VERSION ""

NS_ :

BS_:

BU_: BCM NAB NVO SGW

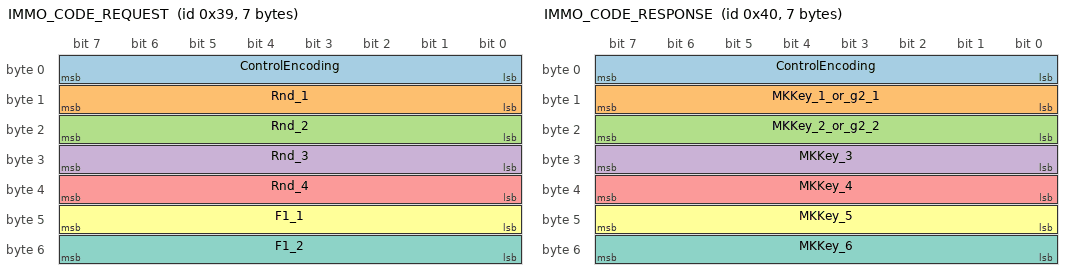
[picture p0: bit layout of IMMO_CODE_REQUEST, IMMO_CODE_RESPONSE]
BO_ 57 IMMO_CODE_REQUEST: 7 SGW
  SG_ ControlEncoding : 7|8@0+ (1,0) [0|255] "" BCM
  SG_ Rnd_1 : 15|8@0+ (1,0) [0|255] "" BCM
  SG_ Rnd_2 : 23|8@0+ (1,0) [0|255] "" BCM
  SG_ Rnd_3 : 31|8@0+ (1,0) [0|255] "" BCM
  SG_ Rnd_4 : 39|8@0+ (1,0) [0|255] "" BCM
  SG_ F1_1 : 47|8@0+ (1,0) [0|255] "" BCM
  SG_ F1_2 : 55|8@0+ (1,0) [0|255] "" BCM

BO_ 64 IMMO_CODE_RESPONSE: 7 BCM
  SG_ ControlEncoding : 7|8@0+ (1,0) [0|255] "" SGW
  SG_ MKKey_1_or_g2_1 : 15|8@0+ (1,0) [0|255] "" SGW
  SG_ MKKey_2_or_g2_2 : 23|8@0+ (1,0) [0|255] "" SGW
  SG_ MKKey_3 : 31|8@0+ (1,0) [0|255] "" SGW
  SG_ MKKey_4 : 39|8@0+ (1,0) [0|255] "" SGW
  SG_ MKKey_5 : 47|8@0+ (1,0) [0|255] "" SGW
  SG_ MKKey_6 : 55|8@0+ (1,0) [0|255] "" SGW

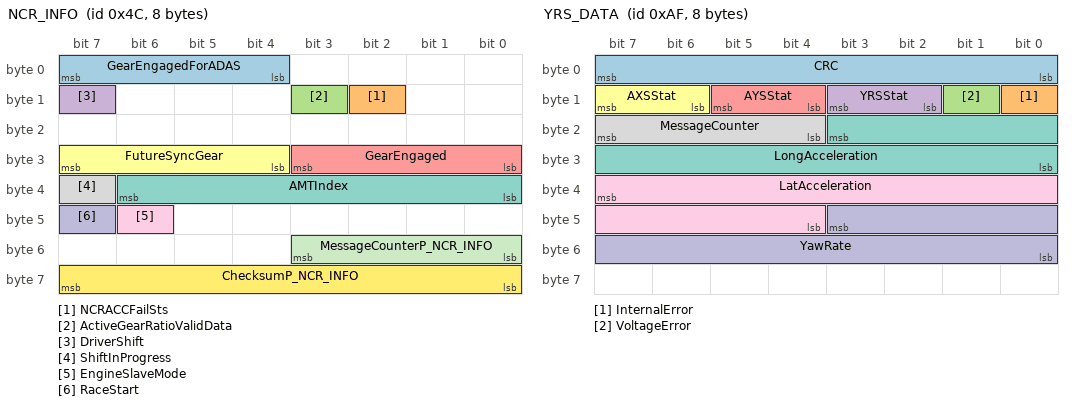
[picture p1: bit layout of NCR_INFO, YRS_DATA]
BO_ 76 NCR_INFO: 8 SGW
  SG_ GearEngagedForADAS : 7|4@0+ (1,0) [0|15] "" Vector__XXX
  SG_ NCRACCFailSts : 10|1@0+ (1,0) [0|1] "" Vector__XXX
  SG_ ActiveGearRatioValidData : 11|1@0+ (1,0) [0|1] "" Vector__XXX
  SG_ DriverShift : 15|1@0+ (1,0) [0|1] "" Vector__XXX
  SG_ GearEngaged : 27|4@0+ (1,0) [0|15] "" BCM
  SG_ FutureSyncGear : 31|4@0+ (1,0) [0|15] "" Vector__XXX
  SG_ AMTIndex : 38|7@0+ (1,0) [0|100] "" Vector__XXX
  SG_ ShiftInProgress : 39|1@0+ (1,0) [0|1] "" Vector__XXX
  SG_ EngineSlaveMode : 46|1@0+ (1,0) [0|1] "" Vector__XXX
  SG_ RaceStart : 47|1@0+ (1,0) [0|1] "" Vector__XXX
  SG_ MessageCounterP_NCR_INFO : 51|4@0+ (1,0) [0|15] "" Vector__XXX
  SG_ ChecksumP_NCR_INFO : 63|8@0+ (1,0) [0|255] "" Vector__XXX

BO_ 175 YRS_DATA: 8 SGW
  SG_ CRC : 7|8@0+ (1,0) [0|255] "" BCM,NAB
  SG_ InternalError : 8|1@0+ (1,0) [0|1] "" Vector__XXX
  SG_ VoltageError : 9|1@0+ (1,0) [0|1] "" Vector__XXX
  SG_ YRSStat : 11|2@0+ (1,0) [0|3] "" BCM
  SG_ AYSStat : 13|2@0+ (1,0) [0|3] "" BCM
  SG_ AXSStat : 15|2@0+ (1,0) [0|3] "" BCM
  SG_ LongAcceleration : 19|12@0+ (0.02,-40.96) [-40.96|40.92] "m/s²" BCM
  SG_ MessageCounter : 23|4@0+ (1,0) [0|15] "" BCM,NAB
  SG_ LatAcceleration : 39|12@0+ (0.02,-40.96) [-40.96|40.92] "m/s²" BCM
  SG_ YawRate : 43|12@0+ (0.08,-163.84) [-163.84|163.68] "°/s" BCM,NAB

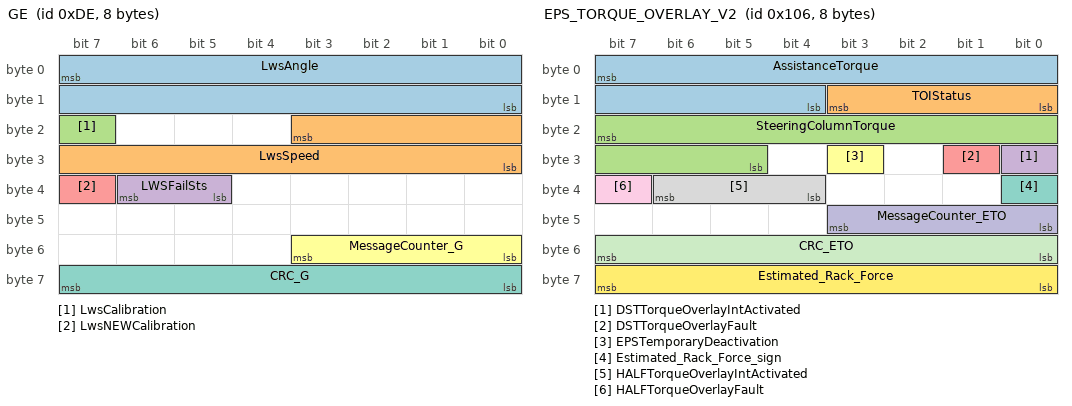
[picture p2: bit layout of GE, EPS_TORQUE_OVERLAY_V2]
BO_ 222 GE: 8 SGW
  SG_ LwsAngle : 7|16@0+ (0.1,-720) [-720|720] "°" BCM,NAB
  SG_ LwsSpeed : 19|12@0+ (1,-2000) [-2000|2094] "°/S" Vector__XXX
  SG_ LwsCalibration : 23|1@0+ (1,0) [0|1] "" Vector__XXX
  SG_ LWSFailSts : 38|2@0+ (1,0) [0|3] "" BCM,NAB
  SG_ LwsNEWCalibration : 39|1@0+ (1,0) [0|1] "" Vector__XXX
  SG_ MessageCounter_G : 51|4@0+ (1,0) [0|15] "" Vector__XXX
  SG_ CRC_G : 63|8@0+ (1,0) [0|255] "" Vector__XXX

BO_ 262 EPS_TORQUE_OVERLAY_V2: 8 SGW
  SG_ AssistanceTorque : 7|12@0+ (0.05,-100) [-100|104.75] "Nm" Vector__XXX
  SG_ TOIStatus : 11|4@0+ (1,0) [0|15] "" Vector__XXX
  SG_ SteeringColumnTorque : 23|11@0+ (0.0078125,-8) [-8|7.984375] "Nm" Vector__XXX
  SG_ DSTTorqueOverlayIntActivated : 24|1@0+ (1,0) [0|1] "" Vector__XXX
  SG_ DSTTorqueOverlayFault : 25|1@0+ (1,0) [0|1] "" Vector__XXX
  SG_ EPSTemporaryDeactivation : 27|1@0+ (1,0) [0|1] "" Vector__XXX
  SG_ Estimated_Rack_Force_sign : 32|1@0+ (1,0) [0|1] "" Vector__XXX
  SG_ HALFTorqueOverlayIntActivated : 38|3@0+ (1,0) [0|7] "" NAB
  SG_ HALFTorqueOverlayFault : 39|1@0+ (1,0) [0|1] "" NAB
  SG_ MessageCounter_ETO : 43|4@0+ (1,0) [0|15] "" Vector__XXX
  SG_ CRC_ETO : 55|8@0+ (1,0) [0|255] "" Vector__XXX
  SG_ Estimated_Rack_Force : 63|8@0+ (80,0) [0|20400] "N" Vector__XXX

BO_ 359 RFHUB1: 8 BCM
  SG_ ExteriorRearSwitch : 0|1@0+ (1,0) [0|1] "" SGW
  SG_ IgnPosSts : 3|3@0+ (1,0) [0|7] "" SGW
  SG_ ValidKeySts : 5|2@0+ (1,0) [0|3] "" SGW
  SG_ CustKeyInIgnSts : 7|2@0+ (1,0) [0|3] "" SGW
  SG_ RFFuncReq : 8|5@0+ (1,0) [0|31] "" SGW
  SG_ RFFobNum : 12|4@0+ (1,0) [0|15] "" SGW
  SG_ RFRearFuncReq : 15|3@0+ (1,0) [0|7] "" SGW
  SG_ FobSearchResult : 16|8@0+ (1,0) [0|255] "" SGW
  SG_ RFReq : 19|3@0+ (1,0) [0|7] "" SGW
  SG_ EmergencyShutdown : 24|1@0+ (1,0) [0|1] "" SGW
  SG_ FobSearchFault : 32|1@0+ (1,0) [0|1] "" SGW
  SG_ HMIPowerOnReq : 33|1@0+ (1,0) [0|1] "" NVO,SGW
  SG_ FOBInterferenceAvoid : 34|1@0+ (1,0) [0|1] "raw" SGW
  SG_ DriverEnginOffRequest : 35|1@0+ (1,0) [0|1] "" SGW
  SG_ FobSearchResult_LongPressure : 39|3@0+ (1,0) [0|7] "" SGW
  SG_ FobSearchExteriorRear : 41|1@0+ (1,0) [0|1] "" SGW
  SG_ FobSearchExteriorLeft : 42|1@0+ (1,0) [0|1] "" SGW
  SG_ FobSearchExteriorRight : 43|1@0+ (1,0) [0|1] "" SGW
  SG_ FobSearchInterior : 44|1@0+ (1,0) [0|1] "" SGW
  SG_ FobSearchTrunk : 45|1@0+ (1,0) [0|1] "" SGW
  SG_ FobSearchStatus : 47|2@0+ (1,0) [0|3] "" SGW
  SG_ MessageCounter_HUB1 : 51|4@0+ (1,0) [0|15] "" SGW
  SG_ KeyCommandReq : 52|1@0+ (1,0) [0|1] "" SGW
  SG_ NPE_ActuationReq : 55|2@0+ (1,0) [0|3] "" SGW
  SG_ Checksum_HUB1 : 63|8@0+ (1,0) [0|255] "" SGW

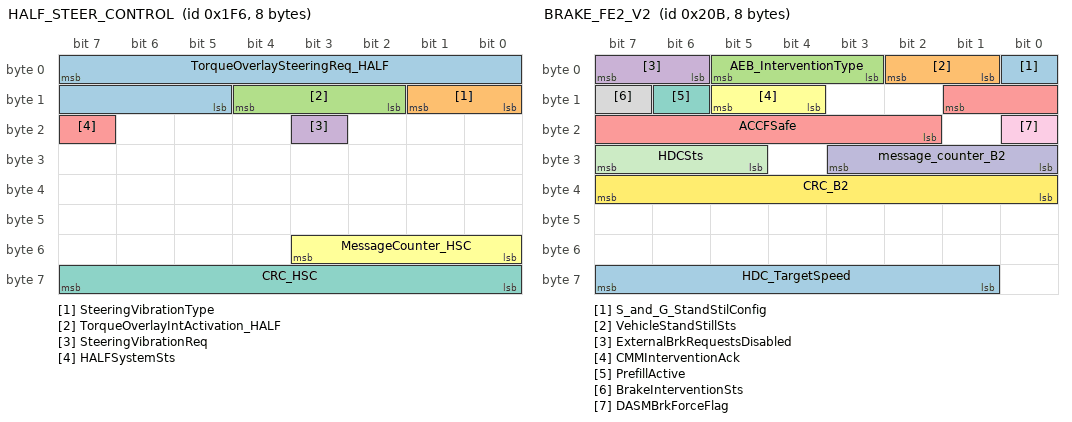
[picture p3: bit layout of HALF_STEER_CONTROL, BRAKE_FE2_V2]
BO_ 502 HALF_STEER_CONTROL: 8 SGW
  SG_ TorqueOverlaySteeringReq_HALF : 7|11@0+ (0.00195312,-2) [-2|1.99803664] "Nm" Vector__XXX
  SG_ SteeringVibrationType : 9|2@0+ (1,0) [0|3] "" Vector__XXX
  SG_ TorqueOverlayIntActivation_HALF : 12|3@0+ (1,0) [0|7] "" Vector__XXX
  SG_ SteeringVibrationReq : 19|1@0+ (1,0) [0|1] "" Vector__XXX
  SG_ HALFSystemSts : 23|1@0+ (1,0) [0|1] "" NAB
  SG_ MessageCounter_HSC : 51|4@0+ (1,0) [0|15] "" Vector__XXX
  SG_ CRC_HSC : 63|8@0+ (1,0) [0|255] "" Vector__XXX

BO_ 523 BRAKE_FE2_V2: 8 SGW
  SG_ S_and_G_StandStilConfig : 0|1@0+ (1,0) [0|1] "" Vector__XXX
  SG_ VehicleStandStillSts : 2|2@0+ (1,0) [0|3] "" Vector__XXX
  SG_ AEB_InterventionType : 5|3@0+ (1,0) [0|7] "" NAB
  SG_ ExternalBrkRequestsDisabled : 7|2@0+ (1,0) [0|3] "" Vector__XXX
  SG_ ACCFSafe : 9|8@0+ (1,0) [0|255] "" Vector__XXX
  SG_ CMMInterventionAck : 13|2@0+ (1,0) [0|3] "" Vector__XXX
  SG_ PrefillActive : 14|1@0+ (1,0) [0|1] "" Vector__XXX
  SG_ BrakeInterventionSts : 15|1@0+ (1,0) [0|1] "" Vector__XXX
  SG_ DASMBrkForceFlag : 16|1@0+ (1,0) [0|1] "" Vector__XXX
  SG_ message_counter_B2 : 27|4@0+ (1,0) [0|15] "" NVO
  SG_ HDCSts : 31|3@0+ (1,0) [0|7] "" NVO
  SG_ CRC_B2 : 39|8@0+ (1,0) [0|255] "" NVO
  SG_ HDC_TargetSpeed : 63|7@0+ (1,0) [0|120] "" Vector__XXX

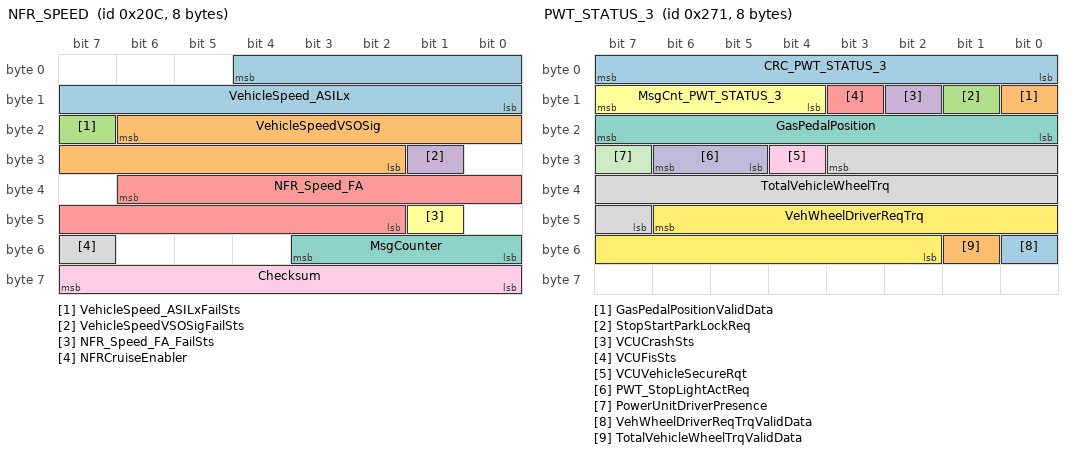
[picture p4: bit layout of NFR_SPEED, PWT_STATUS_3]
BO_ 524 NFR_SPEED: 8 SGW
  SG_ VehicleSpeed_ASILx : 4|13@0+ (0.0625,0) [0|511.9375] "km/h" BCM
  SG_ VehicleSpeedVSOSig : 22|13@0+ (0.0625,0) [0|511.9375] "km/h" BCM,NAB,NVO
  SG_ VehicleSpeed_ASILxFailSts : 23|1@0+ (1,0) [0|1] "" BCM
  SG_ VehicleSpeedVSOSigFailSts : 25|1@0+ (1,0) [0|1] "" BCM,NAB,NVO
  SG_ NFR_Speed_FA : 38|13@0+ (0.0625,0) [0|511.9375] "km/h" BCM,NAB
  SG_ NFR_Speed_FA_FailSts : 41|1@0+ (1,0) [0|1] "" BCM,NAB
  SG_ MsgCounter : 51|4@0+ (1,0) [0|15] "" BCM
  SG_ NFRCruiseEnabler : 55|1@0+ (1,0) [0|1] "" BCM
  SG_ Checksum : 63|8@0+ (1,0) [0|255] "" BCM

BO_ 599 AIRBAG1: 8 NAB
  SG_ SBR2RowCentralSeatBuckleFailSts : 0|2@0+ (1,0) [0|3] "" BCM,SGW
  SG_ SBR2RowCentralSeatConfigSts : 1|1@0+ (1,0) [0|1] "" BCM,SGW
  SG_ AirBagFailSts : 7|2@0+ (1,0) [0|3] "" BCM,SGW
  SG_ SBR1RowDriverSeatFailSts : 8|2@0+ (1,0) [0|3] "" BCM,SGW
  SG_ SBR1RowDriverSeatConfigSts : 9|1@0+ (1,0) [0|1] "" BCM,SGW
  SG_ SBR2RowCentralSeatSts : 12|3@0+ (1,0) [0|7] "" BCM,SGW
  SG_ SBR1RowCentralSeatPPDFailSts : 14|2@0+ (1,0) [0|3] "" BCM,SGW
  SG_ SBR1RowPsngrSeatPPDFailSts : 17|2@0+ (1,0) [0|3] "" BCM,SGW
  SG_ SBR1RowPsngrSeatBuckleFailSts : 19|2@0+ (1,0) [0|3] "" BCM,SGW
  SG_ SBR1RowPsngrSeatConfigSts : 20|1@0+ (1,0) [0|1] "" BCM,SGW
  SG_ SBR1RowDriverSeatSts : 22|2@0+ (1,0) [0|3] "" BCM,SGW
  SG_ SBR2RowLeftSeatSts : 24|2@0+ (1,0) [0|3] "" BCM,SGW
  SG_ SBR2RowRightSeatFailSts : 26|2@0+ (1,0) [0|3] "" BCM,SGW
  SG_ SBR2RowLeftSeatFailSts : 28|2@0+ (1,0) [0|3] "" BCM,SGW
  SG_ SBR1RowPsngrSeatSts : 31|3@0+ (1,0) [0|7] "" BCM,SGW
  SG_ CrashOutputSts : 36|8@0+ (1,0) [0|255] "" BCM,SGW
  SG_ SBR2RowRightSeatSts : 38|2@0+ (1,0) [0|3] "" BCM,SGW
  SG_ MessageCounterNAB1 : 43|4@0+ (1,0) [0|15] "" BCM,SGW
  SG_ CrashOutputValidData : 44|1@0+ (1,0) [0|1] "" BCM,SGW
  SG_ ChecksumNAB1 : 55|8@0+ (1,0) [0|255] "" BCM,SGW
  SG_ AirBagWarningPADLampOnSts : 56|1@0+ (1,0) [0|1] "" BCM,SGW
  SG_ AirBagWarningPADLampOffSts : 57|1@0+ (1,0) [0|1] "" BCM,SGW
  SG_ SBR2RowRightSeatConfigSts : 58|1@0+ (1,0) [0|1] "" BCM,SGW
  SG_ SBR2RowLeftSeatConfigSts : 59|1@0+ (1,0) [0|1] "" BCM,SGW
  SG_ Ppd_psngr_info : 61|2@0+ (1,0) [0|3] "" BCM,SGW
  SG_ AirBagWarningLampSts : 62|1@0+ (1,0) [0|1] "" BCM,SGW
  SG_ AirBagWarningPADPassengerAirbagSts : 63|1@0+ (1,0) [0|1] "" BCM,SGW

BO_ 625 PWT_STATUS_3: 8 SGW
  SG_ CRC_PWT_STATUS_3 : 7|8@0+ (1,0) [0|255] "" BCM
  SG_ GasPedalPositionValidData : 8|1@0+ (1,0) [0|1] "" Vector__XXX
  SG_ StopStartParkLockReq : 9|1@0+ (1,0) [0|1] "" Vector__XXX
  SG_ VCUCrashSts : 10|1@0+ (1,0) [0|1] "" Vector__XXX
  SG_ VCUFisSts : 11|1@0+ (1,0) [0|1] "" BCM
  SG_ MsgCnt_PWT_STATUS_3 : 15|4@0+ (1,0) [0|14] "" BCM
  SG_ GasPedalPosition : 23|8@0+ (0.392,0) [0|99.96] "%" Vector__XXX
  SG_ TotalVehicleWheelTrq : 27|13@0+ (10,-25000) [-25000|25000] "Nm" Vector__XXX
  SG_ VCUVehicleSecureRqt : 28|1@0+ (1,0) [0|1] "" Vector__XXX
  SG_ PWT_StopLightActReq : 30|2@0+ (1,0) [0|3] "" Vector__XXX
  SG_ PowerUnitDriverPresence : 31|1@0+ (1,0) [0|1] "" Vector__XXX
  SG_ VehWheelDriverReqTrq : 46|13@0+ (10,-25000) [-25000|25000] "Nm" Vector__XXX
  SG_ VehWheelDriverReqTrqValidData : 48|1@0+ (1,0) [0|1] "" Vector__XXX
  SG_ TotalVehicleWheelTrqValidData : 49|1@0+ (1,0) [0|1] "" Vector__XXX

BO_ 630 NFR_INFO: 8 SGW
  SG_ CRC_NFR_INFO : 7|8@0+ (1,0) [0|255] "" BCM
  SG_ EPBMalfunction : 8|1@0+ (1,0) [0|1] "" BCM,NAB
  SG_ EPBSts : 11|3@0+ (1,0) [0|7] "" BCM,NAB
  SG_ MessageCounter_NFR_INFO : 15|4@0+ (1,0) [0|14] "" BCM
  SG_ CRBSts : 17|3@0+ (1,0) [0|7] "" BCM
  SG_ AVHSts : 20|3@0+ (1,0) [0|7] "" BCM
  SG_ CDPSts : 23|3@0+ (1,0) [0|7] "" BCM
  SG_ HHCSts : 24|3@0+ (1,0) [0|7] "" BCM
  SG_ ABSSts : 27|3@0+ (1,0) [0|7] "" BCM,NAB
  SG_ EBDSts : 30|3@0+ (1,0) [0|7] "" BCM
  SG_ ESCOFF_Mode : 32|1@0+ (1,0) [0|1] "" BCM,NAB
  SG_ MSRSts : 35|3@0+ (1,0) [0|7] "" BCM
  SG_ EPB_ButtonSts : 37|2@0+ (1,0) [0|3] "" BCM
  SG_ AutoEPBEnable : 41|2@0+ (1,0) [0|3] "" BCM
  SG_ VDCSts : 44|3@0+ (1,0) [0|7] "" BCM,NAB
  SG_ LDISts : 47|3@0+ (1,0) [0|7] "" BCM
  SG_ Slope : 53|7@0+ (1,-61) [-61|61] "%" BCM
  SG_ TireToleranceCompensation : 54|1@0+ (1,0) [0|1] "" BCM
  SG_ MiniSpareDetection : 55|1@0+ (1,0) [0|1] "" BCM
  SG_ SlopeValidData : 62|1@0+ (1,0) [0|1] "" BCM

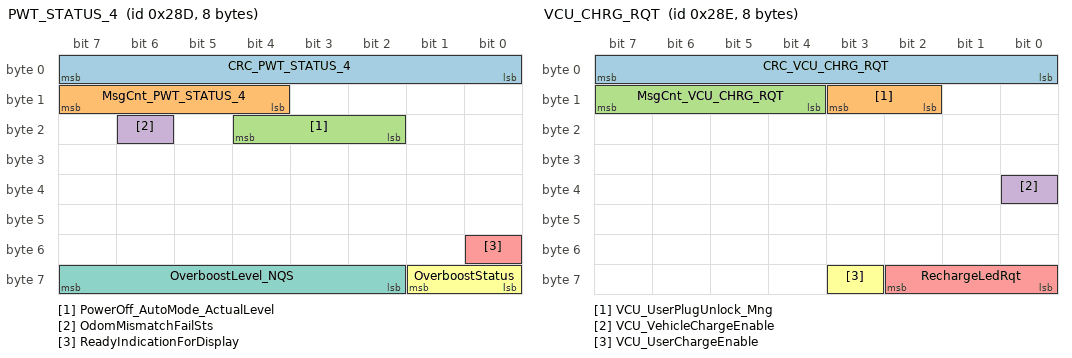
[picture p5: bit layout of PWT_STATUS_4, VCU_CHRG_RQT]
BO_ 653 PWT_STATUS_4: 8 SGW
  SG_ CRC_PWT_STATUS_4 : 7|8@0+ (1,0) [0|255] "" Vector__XXX
  SG_ MsgCnt_PWT_STATUS_4 : 15|4@0+ (1,0) [0|14] "" Vector__XXX
  SG_ PowerOff_AutoMode_ActualLevel : 20|3@0+ (1,0) [0|7] "" Vector__XXX
  SG_ OdomMismatchFailSts : 22|1@0+ (1,0) [0|1] "" Vector__XXX
  SG_ ReadyIndicationForDisplay : 48|1@0+ (1,0) [0|1] "" Vector__XXX
  SG_ OverboostStatus : 57|2@0+ (1,0) [0|3] "" Vector__XXX
  SG_ OverboostLevel_NQS : 63|6@0+ (1,0) [0|60] "" Vector__XXX

BO_ 654 VCU_CHRG_RQT: 8 SGW
  SG_ CRC_VCU_CHRG_RQT : 7|8@0+ (1,0) [0|255] "" BCM
  SG_ VCU_UserPlugUnlock_Mng : 11|2@0+ (1,0) [0|3] "" BCM
  SG_ MsgCnt_VCU_CHRG_RQT : 15|4@0+ (1,0) [0|14] "" BCM
  SG_ VCU_VehicleChargeEnable : 32|1@0+ (1,0) [0|1] "" BCM
  SG_ RechargeLedRqt : 58|3@0+ (1,0) [0|7] "" BCM
  SG_ VCU_UserChargeEnable : 59|1@0+ (1,0) [0|1] "" BCM

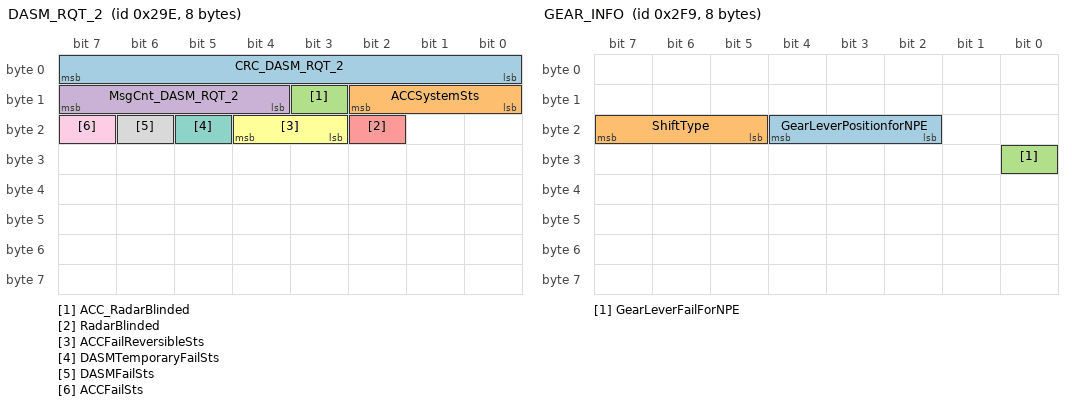
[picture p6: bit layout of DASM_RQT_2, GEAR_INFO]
BO_ 670 DASM_RQT_2: 8 SGW
  SG_ CRC_DASM_RQT_2 : 7|8@0+ (1,0) [0|255] "" NVO
  SG_ ACCSystemSts : 10|3@0+ (1,0) [0|7] "" NAB,NVO
  SG_ ACC_RadarBlinded : 11|1@0+ (1,0) [0|1] "" Vector__XXX
  SG_ MsgCnt_DASM_RQT_2 : 15|4@0+ (1,0) [0|14] "" NVO
  SG_ RadarBlinded : 18|1@0+ (1,0) [0|1] "" Vector__XXX
  SG_ ACCFailReversibleSts : 20|2@0+ (1,0) [0|3] "" Vector__XXX
  SG_ DASMTemporaryFailSts : 21|1@0+ (1,0) [0|1] "" NAB
  SG_ DASMFailSts : 22|1@0+ (1,0) [0|1] "" NAB
  SG_ ACCFailSts : 23|1@0+ (1,0) [0|1] "" NAB

BO_ 761 GEAR_INFO: 8 SGW
  SG_ GearLeverPositionforNPE : 20|3@0+ (1,0) [0|7] "" BCM
  SG_ ShiftType : 23|3@0+ (1,0) [0|7] "" Vector__XXX
  SG_ GearLeverFailForNPE : 24|1@0+ (1,0) [0|1] "" BCM

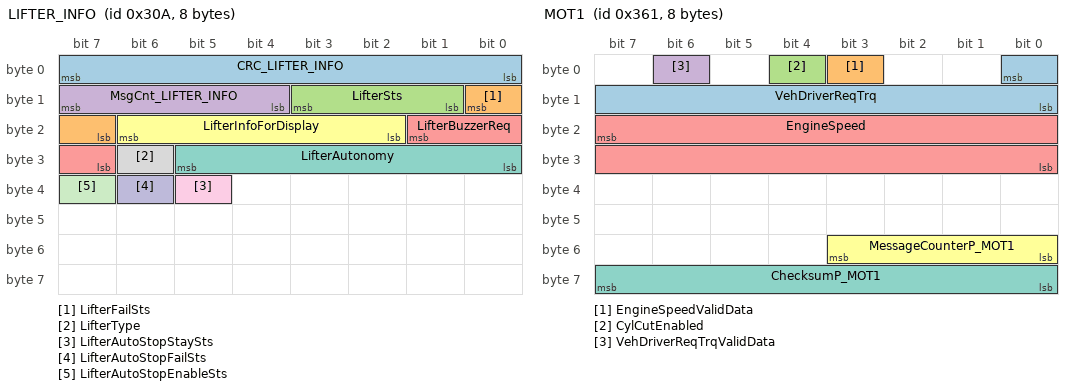
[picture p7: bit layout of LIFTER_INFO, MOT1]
BO_ 778 LIFTER_INFO: 8 SGW
  SG_ CRC_LIFTER_INFO : 7|8@0+ (1,0) [0|255] "" BCM
  SG_ LifterFailSts : 8|2@0+ (1,0) [0|3] "" BCM
  SG_ LifterSts : 11|3@0+ (1,0) [0|7] "" BCM
  SG_ MsgCnt_LIFTER_INFO : 15|4@0+ (1,0) [0|14] "" BCM
  SG_ LifterBuzzerReq : 17|3@0+ (1,0) [0|7] "" Vector__XXX
  SG_ LifterInfoForDisplay : 22|5@0+ (1,0) [0|31] "" Vector__XXX
  SG_ LifterAutonomy : 29|6@0+ (5,0) [0|300] "" Vector__XXX
  SG_ LifterType : 30|1@0+ (1,0) [0|1] "" Vector__XXX
  SG_ LifterAutoStopStaySts : 37|1@0+ (1,0) [0|1] "" Vector__XXX
  SG_ LifterAutoStopFailSts : 38|1@0+ (1,0) [0|1] "" Vector__XXX
  SG_ LifterAutoStopEnableSts : 39|1@0+ (1,0) [0|1] "" Vector__XXX

BO_ 865 MOT1: 8 SGW
  SG_ VehDriverReqTrq : 0|9@0+ (4,-508) [-508|1536] "Nm" Vector__XXX
  SG_ EngineSpeedValidData : 3|1@0+ (1,0) [0|1] "" NAB
  SG_ CylCutEnabled : 4|1@0+ (1,0) [0|1] "" Vector__XXX
  SG_ VehDriverReqTrqValidData : 6|1@0+ (1,0) [0|1] "" Vector__XXX
  SG_ EngineSpeed : 23|16@0+ (1,0) [0|10240] "1/min" NAB
  SG_ MessageCounterP_MOT1 : 51|4@0+ (1,0) [0|15] "" BCM
  SG_ ChecksumP_MOT1 : 63|8@0+ (1,0) [0|255] "" BCM

BO_ 980 NVO_INFO_V2: 8 NVO
  SG_ CruiseControlCmdResumeSts : 0|1@0+ (1,0) [0|1] "" BCM,SGW
  SG_ CruiseControlCmdChangeSts : 1|1@0+ (1,0) [0|1] "" BCM,SGW
  SG_ CruiseControlCmdDecelerationSts : 2|1@0+ (1,0) [0|1] "" BCM,SGW
  SG_ CruiseControlCmdAccelerationSts : 3|1@0+ (1,0) [0|1] "" BCM,SGW
  SG_ EManettinoDriverWish : 7|4@0+ (1,0) [0|15] "" BCM,SGW
  SG_ CruiseControlFailSts : 9|1@0+ (1,0) [0|1] "" SGW
  SG_ ACC_OnOffSts : 10|1@0+ (1,0) [0|1] "" BCM,SGW
  SG_ SpeedRockerSts : 13|3@0+ (1,0) [0|7] "" BCM,SGW
  SG_ ACC_DistSts : 14|1@0+ (1,0) [0|1] "" SGW
  SG_ ResumeSwitch : 15|1@0+ (1,0) [0|1] "" BCM,SGW
  SG_ ManettinoSuspensionSts : 18|3@0+ (1,0) [0|7] "" SGW
  SG_ ESPChangeModeReqSts : 19|1@0+ (1,0) [0|1] "" SGW
  SG_ ManettinoFailSts : 20|1@0+ (1,0) [0|1] "" SGW
  SG_ ManettinoSts : 23|3@0+ (1,0) [0|7] "" BCM,SGW
  SG_ FrontWindshieldWiperSwitchSts : 26|3@0+ (1,0) [0|7] "" BCM,SGW
  SG_ SuspensionButtonSts : 27|1@0+ (1,0) [0|1] "" BCM,SGW
  SG_ LdirectionSwitchSts : 28|1@0+ (1,0) [0|1] "" BCM,SGW
  SG_ RdirectionSwitchSts : 29|1@0+ (1,0) [0|1] "" BCM,SGW
  SG_ LTICmdFailSts : 32|1@0+ (1,0) [0|1] "" BCM,SGW
  SG_ SuspensionButtonValidData : 33|1@0+ (1,0) [0|1] "" SGW
  SG_ EManettinoDriverWishDirection : 35|2@0+ (1,0) [0|3] "" SGW
  SG_ HDCButtonSts : 37|1@0+ (1,0) [0|1] "" SGW
  SG_ WiperCmdFailSts : 38|1@0+ (1,0) [0|1] "" BCM,SGW
  SG_ FrontWindshieldWasherSwitchSts : 39|1@0+ (1,0) [0|1] "" BCM,SGW
  SG_ ConfirmationCommand : 42|2@0+ (1,0) [0|3] "" BCM,SGW
  SG_ ContentsCommand : 44|2@0+ (1,0) [0|3] "" BCM,SGW
  SG_ RChangeLaneSts : 45|1@0+ (1,0) [0|1] "" BCM,SGW
  SG_ LChangeLaneSts : 46|1@0+ (1,0) [0|1] "" BCM,SGW
  SG_ RTICmdFailSts : 47|1@0+ (1,0) [0|1] "" BCM,SGW
  SG_ MessageCounterP_NVO_INFO : 51|4@0+ (1,0) [0|15] "" BCM,SGW
  SG_ ChecksumP_NVO_INFO : 63|8@0+ (1,0) [0|255] "" BCM,SGW

BO_ 988 STATUS_NTP: 8 SGW
  SG_ TyrePressureSystemSts : 0|1@0+ (1,0) [0|1] "" NAB
  SG_ TyrePressureSystemFailSts : 1|1@0+ (1,0) [0|1] "" NAB
  SG_ TyrePressureSysCalibrationSts : 2|1@0+ (1,0) [0|1] "" Vector__XXX
  SG_ NTPTempNotActiveSts : 3|1@0+ (1,0) [0|1] "" Vector__XXX
  SG_ NTPCalibrationReqACK : 4|1@0+ (1,0) [0|1] "" Vector__XXX
  SG_ IDtyre_temperature : 7|2@0+ (1,0) [0|3] "" Vector__XXX
  SG_ TemperatureSts_xx : 15|8@0+ (1,-40) [-40|125] "°C" Vector__XXX
  SG_ UnknownTyrePressureSts : 17|2@0+ (1,0) [0|3] "" Vector__XXX
  SG_ TPMSTelltaleSts : 23|2@0+ (1,0) [0|3] "" Vector__XXX
  SG_ RHRTyrePressureSts : 25|2@0+ (1,0) [0|3] "" Vector__XXX
  SG_ LHRTyrePressureSts : 27|2@0+ (1,0) [0|3] "" Vector__XXX
  SG_ RHFTyrePressureSts : 29|2@0+ (1,0) [0|3] "" Vector__XXX
  SG_ LHFTyrePressureSts : 31|2@0+ (1,0) [0|3] "" Vector__XXX
  SG_ LHFPressureSts : 39|8@0+ (0.025,0) [0|5.375] "bar" Vector__XXX
  SG_ RHFPressureSts : 47|8@0+ (0.025,0) [0|5.375] "bar" Vector__XXX
  SG_ LHRPressureSts : 55|8@0+ (0.025,0) [0|5.375] "bar" Vector__XXX
  SG_ RHRPressureSts : 63|8@0+ (0.025,0) [0|5.375] "bar" Vector__XXX

BO_ 1023 LCU_COMMAND: 8 BCM
  SG_ HBActivation : 1|2@0+ (1,0) [0|3] "" SGW
  SG_ LBActivation : 2|1@0+ (1,0) [0|1] "" SGW
  SG_ ParkingLightCmd : 3|1@0+ (1,0) [0|1] "" SGW
  SG_ LeftPL : 4|1@0+ (1,0) [0|1] "" SGW
  SG_ RightPL : 5|1@0+ (1,0) [0|1] "" SGW
  SG_ LeftDRL : 6|1@0+ (1,0) [0|1] "" SGW
  SG_ RightDRL : 7|1@0+ (1,0) [0|1] "" SGW
  SG_ AHB_Memory : 12|1@0+ (1,0) [0|1] "" SGW
  SG_ FBL_Activation : 13|1@0+ (1,0) [0|1] "" SGW
  SG_ TrafficChangeEnable : 15|2@0+ (1,0) [0|3] "" SGW
  SG_ AFSReq : 40|1@0+ (1,0) [0|1] "" SGW
  SG_ MsgCounter_LCUCmd : 51|4@0+ (1,0) [0|15] "" SGW
  SG_ FrontWindshieldWiperSts : 52|1@0+ (1,0) [0|1] "" SGW
  SG_ FrontWindshieldWasherSts : 53|1@0+ (1,0) [0|1] "" SGW
  SG_ AHBFeature : 54|1@0+ (1,0) [0|1] "" SGW
  SG_ AHB_ON : 55|1@0+ (1,0) [0|1] "" SGW
  SG_ Checksum_LCUCmd : 63|8@0+ (1,0) [0|255] "" SGW

BO_ 1024 Gyro_Data: 6 BCM
  SG_ YawRate : 39|12@0+ (0.08,-163.84) [-163.84|163.68] "°/s" SGW
  SG_ YRSStat : 43|2@0+ (1,0) [0|3] "" SGW

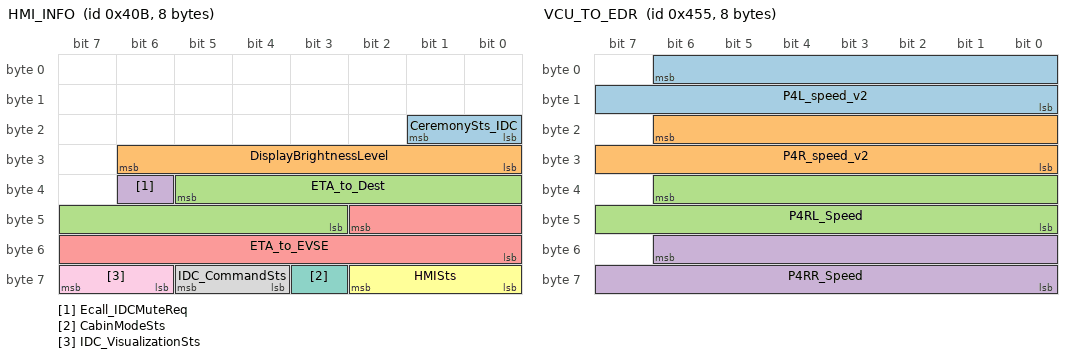
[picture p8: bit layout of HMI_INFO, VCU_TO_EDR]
BO_ 1035 HMI_INFO: 8 SGW
  SG_ CeremonySts_IDC : 17|2@0+ (1,0) [0|3] "" BCM
  SG_ DisplayBrightnessLevel : 30|7@0+ (1,0) [0|127] "" BCM
  SG_ ETA_to_Dest : 37|11@0+ (1,0) [0|2047] "min" BCM
  SG_ Ecall_IDCMuteReq : 38|1@0+ (1,0) [0|1] "" BCM
  SG_ ETA_to_EVSE : 42|11@0+ (1,0) [0|2047] "min" BCM
  SG_ HMISts : 58|3@0+ (1,0) [0|3] "" BCM,NVO
  SG_ CabinModeSts : 59|1@0+ (1,0) [0|1] "" BCM
  SG_ IDC_CommandSts : 61|2@0+ (1,0) [0|3] "" BCM
  SG_ IDC_VisualizationSts : 63|2@0+ (1,0) [0|3] "" BCM

BO_ 1109 VCU_TO_EDR: 8 SGW
  SG_ P4L_speed_v2 : 6|15@0+ (2,-20000) [-20000|40000] "rpm" NAB
  SG_ P4R_speed_v2 : 22|15@0+ (2,-20000) [-20000|40000] "rpm" NAB
  SG_ P4RL_Speed : 38|15@0+ (2,-20000) [-20000|40000] "rpm" NAB
  SG_ P4RR_Speed : 54|15@0+ (2,-20000) [-20000|40000] "rpm" NAB

BO_ 1212 COMMAND_SGW_TO_NBC: 8 SGW
  SG_ RemoteFuncReq : 11|4@0+ (1,0) [0|15] "" BCM
  SG_ TCU_Replacement_Warning : 23|1@0+ (1,0) [0|1] "" BCM

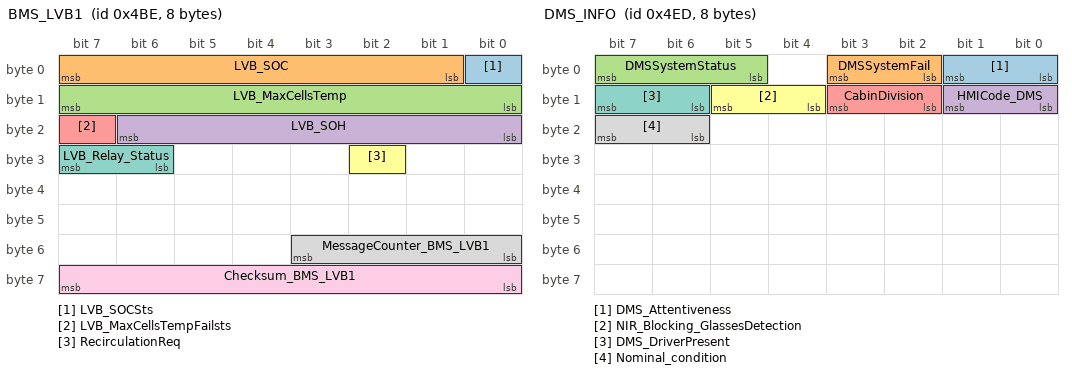
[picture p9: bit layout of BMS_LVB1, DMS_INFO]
BO_ 1214 BMS_LVB1: 8 SGW
  SG_ LVB_SOCSts : 0|1@0+ (1,0) [0|1] "" BCM
  SG_ LVB_SOC : 7|7@0+ (1,0) [0|100] "%" BCM
  SG_ LVB_MaxCellsTemp : 15|8@0+ (1,-45) [-45|170] "°C" BCM
  SG_ LVB_SOH : 22|7@0+ (1,0) [0|100] "%" BCM
  SG_ LVB_MaxCellsTempFailsts : 23|1@0+ (1,0) [0|1] "" BCM
  SG_ RecirculationReq : 26|1@0+ (1,0) [0|1] "" BCM
  SG_ LVB_Relay_Status : 31|2@0+ (1,0) [0|3] "" BCM
  SG_ MessageCounter_BMS_LVB1 : 51|4@0+ (1,0) [0|15] "" BCM
  SG_ Checksum_BMS_LVB1 : 63|8@0+ (1,0) [0|255] "" BCM

BO_ 1261 DMS_INFO: 8 SGW
  SG_ DMS_Attentiveness : 1|2@0+ (1,0) [0|3] "" Vector__XXX
  SG_ DMSSystemFail : 3|2@0+ (1,0) [0|3] "" Vector__XXX
  SG_ DMSSystemStatus : 7|3@0+ (1,0) [0|7] "" Vector__XXX
  SG_ HMICode_DMS : 9|2@0+ (1,0) [0|3] "" Vector__XXX
  SG_ CabinDivision : 11|2@0+ (1,0) [0|3] "" Vector__XXX
  SG_ NIR_Blocking_GlassesDetection : 13|2@0+ (1,0) [0|3] "" Vector__XXX
  SG_ DMS_DriverPresent : 15|2@0+ (1,0) [0|3] "" BCM
  SG_ Nominal_condition : 23|2@0+ (1,0) [0|3] "" Vector__XXX

BO_ 1267 PWT_STATUS_1: 8 SGW
  SG_ CRC_PWT_STATUS_1 : 7|8@0+ (1,0) [0|255] "" BCM
  SG_ PWT_Limited_Perfo : 8|1@0+ (1,0) [0|1] "" BCM
  SG_ RechargeSts_HVB : 10|2@0+ (1,0) [0|3] "" BCM
  SG_ PWTBuzzerReq : 11|1@0+ (1,0) [0|1] "" BCM
  SG_ MsgCnt_PWT_STATUS_1 : 15|4@0+ (1,0) [0|14] "" BCM
  SG_ HMICode_CC : 18|5@0+ (1,0) [0|31] "" BCM
  SG_ Recharge_PlugSts : 20|2@0+ (1,0) [0|3] "" BCM
  SG_ VehicleStartNotAllowed : 21|1@0+ (1,0) [0|1] "" BCM
  SG_ START_ButtonPress_Rqt : 23|2@0+ (1,0) [0|3] "" BCM
  SG_ CCSpeedWarning : 29|2@0+ (1,0) [0|1] "" BCM
  SG_ PlugInRechargeWarning : 36|5@0+ (1,0) [0|31] "" BCM
  SG_ LVSysWarningForDisplay : 42|5@0+ (1,0) [0|31] "" BCM
  SG_ PWTSystemWarningForDisplay : 47|5@0+ (1,0) [0|31] "" BCM
  SG_ PWTLimpHomeSts : 53|5@0+ (1,0) [0|31] "" BCM
  SG_ PropulsionSystemFailure : 57|1@0+ (1,0) [0|1] "" BCM
  SG_ MVSysWarningForDisplay : 61|4@0+ (1,0) [0|15] "" BCM
  SG_ PWTFailSts : 62|1@0+ (1,0) [0|1] "" BCM
  SG_ MVFailSts : 63|1@0+ (1,0) [0|1] "" BCM

BO_ 1274 NPE_DEBUG_1: 8 BCM
  SG_ Five_min_decount : 7|16@0+ (1,0) [0|65535] "" Vector__XXX
  SG_ rub_Current_WAL_Status : 18|3@0+ (1,0) [0|7] "" Vector__XXX
  SG_ rub_WAL_Current_Activation : 22|4@0+ (1,0) [0|15] "" Vector__XXX
  SG_ Passenger_And_ReadDoors_Closed : 23|1@0+ (1,0) [0|1] "" Vector__XXX
  SG_ WAL_Trig_EV : 27|4@0+ (1,0) [0|15] "" Vector__XXX
  SG_ WAL_Exit_Trig_EV : 28|1@0+ (1,0) [0|1] "" Vector__XXX
  SG_ X_SET_WAL_Area_To_Search_m : 31|3@0+ (1,0) [0|7] "" Vector__XXX
  SG_ is_WAL_Search : 34|3@0+ (1,0) [0|7] "" Vector__XXX
  SG_ X_SET_WAL_RKE_Window_c : 35|1@0+ (1,0) [0|1] "" Vector__XXX
  SG_ rub_WAL_Current_Exit : 39|4@0+ (1,0) [0|15] "" Vector__XXX
  SG_ rub_wal_activity_sts : 40|1@0+ (1,0) [0|1] "" Vector__XXX
  SG_ rub_walsearch_activity_sts : 41|1@0+ (1,0) [0|1] "" Vector__XXX
  SG_ rub_wal_tracking_ID_allowed : 42|1@0+ (1,0) [0|1] "" Vector__XXX
  SG_ PEStatus : 43|1@0+ (1,0) [0|1] "" Vector__XXX
  SG_ TSC_AUTH_VALID : 44|1@0+ (1,0) [0|1] "" Vector__XXX
  SG_ rub_PK_AUTH_RESULT_C : 45|1@0+ (1,0) [0|1] "" Vector__XXX
  SG_ rub_TP_AUTH_RESULT_C : 46|1@0+ (1,0) [0|1] "" Vector__XXX
  SG_ Message1_Byte5 : 47|1@0+ (1,0) [0|1] "" Vector__XXX
  SG_ Message1_Byte6 : 55|8@0+ (1,0) [0|255] "" Vector__XXX
  SG_ Message1_Byte7 : 63|8@0+ (1,0) [0|255] "" Vector__XXX

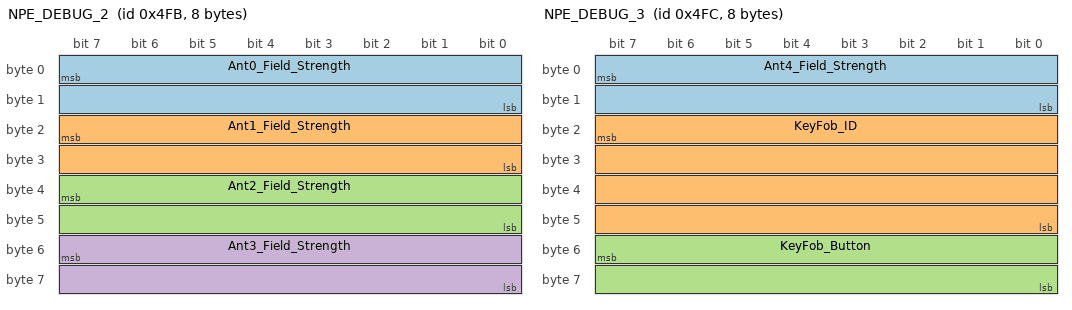
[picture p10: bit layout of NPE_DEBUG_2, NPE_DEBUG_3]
BO_ 1275 NPE_DEBUG_2: 8 BCM
  SG_ Ant0_Field_Strength : 7|16@0+ (1,0) [0|32768] "" Vector__XXX
  SG_ Ant1_Field_Strength : 23|16@0+ (1,0) [0|32768] "" Vector__XXX
  SG_ Ant2_Field_Strength : 39|16@0+ (1,0) [0|32768] "" Vector__XXX
  SG_ Ant3_Field_Strength : 55|16@0+ (1,0) [0|32768] "" Vector__XXX

BO_ 1276 NPE_DEBUG_3: 8 BCM
  SG_ Ant4_Field_Strength : 7|16@0+ (1,0) [0|32768] "" Vector__XXX
  SG_ KeyFob_ID : 23|32@0+ (1,0) [0|4294967295] "" Vector__XXX
  SG_ KeyFob_Button : 55|16@0+ (1,0) [0|64] "" Vector__XXX

BO_ 1286 NFR_HMI: 8 SGW
  SG_ AVHDisplayInfo : 1|2@0+ (1,0) [0|3] "" Vector__XXX
  SG_ HHCDisplayInfo : 2|1@0+ (1,0) [0|1] "" Vector__XXX
  SG_ EBDDisplayInfo : 3|1@0+ (1,0) [0|1] "" BCM
  SG_ ABSDisplayInfo : 4|1@0+ (1,0) [0|1] "" NAB
  SG_ ESCOFFLampRequest : 5|1@0+ (1,0) [0|1] "" NAB,NVO
  SG_ BrakeFluidLevelSts : 7|1@0+ (1,0) [0|1] "" Vector__XXX
  SG_ NFRSts : 11|4@0+ (1,0) [0|15] "" NAB,NVO
  SG_ EPBRemovePLRqtInfo : 14|1@0+ (1,0) [0|1] "" Vector__XXX
  SG_ ThirdLightFaultSts : 15|1@0+ (1,0) [0|1] "" Vector__XXX
  SG_ EPB_BrakePedalPressIndicationReq : 16|1@0+ (1,0) [0|1] "" Vector__XXX
  SG_ EPB_BuzzerReq : 17|1@0+ (1,0) [0|1] "" BCM
  SG_ LDIDisplayInfo : 20|3@0+ (1,0) [0|7] "" NAB
  SG_ PBDisplayInfoValidData : 21|1@0+ (1,0) [0|1] "" BCM
  SG_ VDCDisplayInfo : 23|2@0+ (1,0) [0|3] "" NAB,NVO
  SG_ ServiceLampBlinkFreq : 26|3@0+ (1,0) [0|7] "" BCM
  SG_ PBDisplayInfo : 31|5@0+ (1,0) [0|31] "" BCM
  SG_ FadeWarning : 33|2@0+ (1,0) [0|3] "" Vector__XXX
  SG_ EPBDisplayEnable : 35|2@0+ (1,0) [0|3] "" Vector__XXX
  SG_ WarningLampReq : 37|2@0+ (1,0) [0|3] "" BCM
  SG_ ServiceLampReq : 39|2@0+ (1,0) [0|3] "" Vector__XXX
  SG_ ESCOFF_Inhibition_Info : 43|1@0+ (1,0) [0|1] "" Vector__XXX
  SG_ CRBInfoForDisplay : 45|2@0+ (1,0) [0|3] "" Vector__XXX
  SG_ MSRInfoForDisplay : 47|2@0+ (1,0) [0|3] "" Vector__XXX
  SG_ MessageCounter : 51|4@0+ (1,0) [0|15] "" BCM
  SG_ EPBLifeCycleWarning : 52|1@0+ (1,0) [0|1] "" BCM
  SG_ HDC_Pop_Up : 55|3@0+ (1,0) [0|3] "" Vector__XXX
  SG_ Checksum : 63|8@0+ (1,0) [0|255] "" BCM

BO_ 1312 VEHSTAT_V2: 8 BCM
  SG_ TurnIndicatorSts : 2|2@0+ (1,0) [0|3] "" NAB,SGW
  SG_ KeySts : 6|4@0+ (1,0) [0|15] "raw" SGW
  SG_ TrailerConnected : 7|1@0+ (1,0) [0|1] "" SGW
  SG_ LHRTurnLightFailSts : 8|1@0+ (1,0) [0|1] "" SGW
  SG_ LHRParkTailLightFailSts : 9|1@0+ (1,0) [0|1] "" SGW
  SG_ HazardLightSts : 10|1@0+ (1,0) [0|1] "" NAB,SGW
  SG_ LHFTurnLightFailSts : 11|1@0+ (1,0) [0|1] "" SGW
  SG_ NBCFISSts : 12|1@0+ (1,0) [0|1] "" SGW
  SG_ StopLightFault : 13|1@0+ (1,0) [0|1] "" SGW
  SG_ AHBFeature : 14|1@0+ (1,0) [0|1] "" SGW
  SG_ RHTurnSignalSts : 16|1@0+ (1,0) [0|1] "" SGW
  SG_ RHStopLightFailSts : 17|1@0+ (1,0) [0|1] "" SGW
  SG_ RHRTurnLightFailSts : 18|1@0+ (1,0) [0|1] "" SGW
  SG_ RHRParkTailLightFailSts : 19|1@0+ (1,0) [0|1] "" SGW
  SG_ TrailerConnectedFailSts : 20|1@0+ (1,0) [0|1] "" SGW
  SG_ RHFTurnLightFailSts : 21|1@0+ (1,0) [0|1] "" SGW
  SG_ LHTurnSignalSts : 22|1@0+ (1,0) [0|1] "" SGW
  SG_ LHStopLightFailSts : 23|1@0+ (1,0) [0|1] "" SGW
  SG_ Position_FbkWMRR : 27|4@0+ (10,0) [0|1000] "" SGW
  SG_ LBCmdNightInfoForDisplay : 28|1@0+ (1,0) [0|1] "" SGW
  SG_ Position_Fbk_WLMR : 35|4@0+ (10,0) [0|1000] "" SGW
  SG_ Position_FbkWMRL : 39|4@0+ (10,0) [0|1000] "" SGW
  SG_ NSVSts : 41|2@0+ (1,0) [0|3] "" SGW
  SG_ LHParkTailLightSts : 42|1@0+ (1,0) [0|1] "" SGW
  SG_ RHParkTailLightSts : 43|1@0+ (1,0) [0|1] "" SGW
  SG_ Position_Fbk_WLML : 47|4@0+ (10,0) [0|1000] "" SGW
  SG_ message_counter_B01 : 51|4@0+ (1,0) [0|15] "" SGW
  SG_ RLSWiperSpeed : 54|3@0+ (1,0) [0|7] "" SGW
  SG_ FrontWiperModeSts : 55|1@0+ (1,0) [0|1] "" SGW
  SG_ CRC_B01 : 63|8@0+ (1,0) [0|255] "" SGW

BO_ 1313 STATUS_DOORS: 8 BCM
  SG_ STS_DRS_DriverLatchsts : 1|2@0+ (1,0) [0|3] "" SGW
  SG_ STS_DRS_PsngrDoorSts : 3|2@0+ (1,0) [0|3] "" SGW
  SG_ STS_DRS_DriverDoorSts : 5|2@0+ (1,0) [0|3] "" SGW
  SG_ STS_DRS_VPSTrunkSts : 7|2@0+ (1,0) [0|3] "" SGW
  SG_ STS_DRS_RearRightLatchsts : 9|2@0+ (1,0) [0|3] "" SGW
  SG_ STS_DRS_RearLeftDoorSts : 11|2@0+ (1,0) [0|3] "" SGW
  SG_ STS_DRS_RearRightDoorSts : 13|2@0+ (1,0) [0|3] "" SGW
  SG_ STS_DRS_PsngrLatchsts : 15|2@0+ (1,0) [0|3] "" SGW
  SG_ STS_DRS_PsngrWindowSts : 17|3@0+ (1,0) [0|7] "" SGW
  SG_ STS_DRS_DriverWindowSts : 20|3@0+ (1,0) [0|7] "" SGW
  SG_ STS_DRS_VPSLockValidData : 21|1@0+ (1,0) [0|1] "" SGW
  SG_ STS_DRS_RearLeftLatchsts : 23|2@0+ (1,0) [0|3] "" SGW
  SG_ TrunkInternalButton : 24|1@0+ (1,0) [0|1] "" SGW
  SG_ STS_DRS_RearRightWindowSts : 27|3@0+ (1,0) [0|7] "" SGW
  SG_ STS_DRS_RearLeftWindowSts : 30|3@0+ (1,0) [0|7] "" SGW
  SG_ Interior_Lock : 35|1@0+ (1,0) [0|1] "" SGW
  SG_ VPSDoorSts : 37|2@0+ (1,0) [0|3] "" SGW
  SG_ LockUnlockDoors_Button : 38|1@0+ (1,0) [0|1] "" SGW
  SG_ TrunkExternalButton : 39|1@0+ (1,0) [0|1] "" SGW
  SG_ STS_DRS_MsgCounter : 51|4@0+ (1,0) [0|15] "" SGW
  SG_ STS_DRS_Checksum : 63|8@0+ (1,0) [0|255] "" SGW

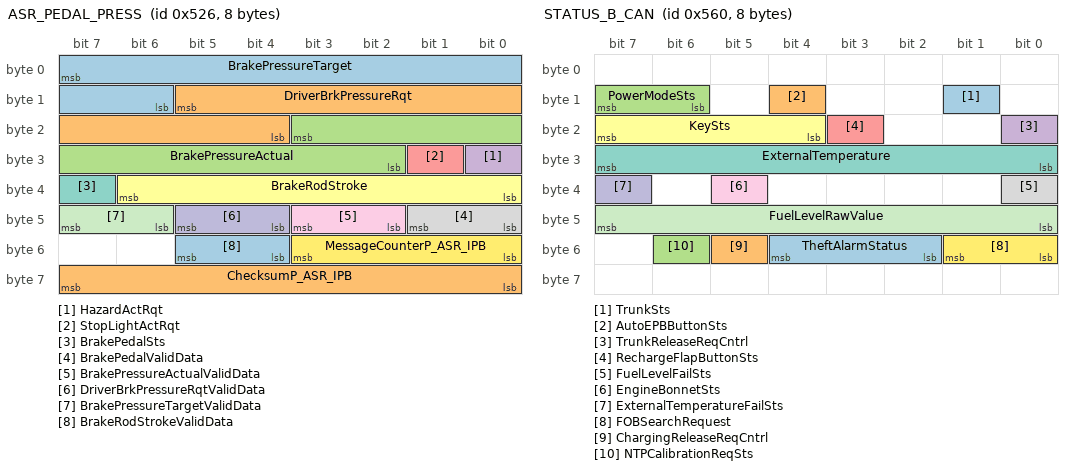
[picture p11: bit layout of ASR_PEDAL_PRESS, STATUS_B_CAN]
BO_ 1318 ASR_PEDAL_PRESS: 8 SGW
  SG_ BrakePressureTarget : 7|10@0+ (0.25,0) [0|200] "bar" BCM
  SG_ DriverBrkPressureRqt : 13|10@0+ (0.25,0) [0|200] "bar" BCM
  SG_ BrakePressureActual : 19|10@0+ (0.25,0) [0|200] "bar" BCM
  SG_ HazardActRqt : 24|1@0+ (1,0) [0|1] "" BCM
  SG_ StopLightActRqt : 25|1@0+ (1,0) [0|1] "" BCM
  SG_ BrakeRodStroke : 38|7@0+ (0.2,0) [0|20] "mm" BCM,NAB
  SG_ BrakePedalSts : 39|1@0+ (1,0) [0|1] "" BCM,NAB
  SG_ BrakePedalValidData : 41|2@0+ (1,0) [0|3] "" BCM,NAB
  SG_ BrakePressureActualValidData : 43|2@0+ (1,0) [0|3] "" BCM
  SG_ DriverBrkPressureRqtValidData : 45|2@0+ (1,0) [0|3] "" BCM
  SG_ BrakePressureTargetValidData : 47|2@0+ (1,0) [0|3] "" BCM
  SG_ MessageCounterP_ASR_IPB : 51|4@0+ (1,0) [0|15] "" BCM
  SG_ BrakeRodStrokeValidData : 53|2@0+ (1,0) [0|3] "" BCM,NAB
  SG_ ChecksumP_ASR_IPB : 63|8@0+ (1,0) [0|255] "" BCM

BO_ 1351 HAPTIC1: 8 SGW
  SG_ HALF_CHIME_TYPESts : 3|4@0+ (1,0) [0|15] "" Vector__XXX
  SG_ TSR_Fault : 4|1@0+ (1,0) [0|1] "" Vector__XXX
  SG_ TSR_ON : 5|1@0+ (1,0) [0|1] "" Vector__XXX
  SG_ LDWSystemSts : 7|2@0+ (1,0) [0|3] "" NAB
  SG_ StatusLKA : 9|2@0+ (1,0) [0|3] "" NAB
  SG_ LDWSensitivitySts : 13|2@0+ (1,0) [0|3] "" Vector__XXX
  SG_ HALF_RF_CHIME_RQSts : 14|1@0+ (1,0) [0|1] "" Vector__XXX
  SG_ HALF_LF_CHIME_RQSts : 15|1@0+ (1,0) [0|1] "" Vector__XXX
  SG_ TSA_ON : 17|2@0+ (1,0) [0|3] "" Vector__XXX
  SG_ HandsOnSts : 21|3@0+ (1,0) [0|7] "" Vector__XXX
  SG_ StatusDDA : 23|2@0+ (1,0) [0|3] "" Vector__XXX
  SG_ ADAS_Unavailable_Camera : 27|2@0+ (1,0) [0|3] "" Vector__XXX
  SG_ TSAMainSign2Fbk : 29|2@0+ (1,0) [0|3] "" Vector__XXX
  SG_ TSASignChangeFbk : 31|2@0+ (1,0) [0|3] "" Vector__XXX
  SG_ DDAW_Level : 35|4@0+ (1,0) [0|15] "" Vector__XXX
  SG_ DrowsinessSts : 37|2@0+ (1,0) [0|3] "" Vector__XXX
  SG_ LDWWarningType_fbk : 39|2@0+ (1,0) [0|3] "" Vector__XXX
  SG_ DisplaySts : 40|8@0+ (1,0) [0|255] "" NAB
  SG_ SensorBlinded : 41|1@0+ (1,0) [0|1] "" BCM
  SG_ AHBFault : 42|1@0+ (1,0) [0|1] "" BCM
  SG_ AHB_ON : 43|1@0+ (1,0) [0|1] "" BCM
  SG_ TSR_Sts : 46|1@0+ (1,0) [0|1] "" Vector__XXX
  SG_ HALF_heaterSts : 47|1@0+ (1,0) [0|1] "" Vector__XXX
  SG_ DDAW_Index : 48|9@0+ (0.2,0) [0|100] "" Vector__XXX

BO_ 1376 STATUS_B_CAN: 8 BCM
  SG_ TrunkSts : 9|1@0+ (1,0) [0|1] "" SGW
  SG_ AutoEPBButtonSts : 12|1@0+ (1,0) [0|1] "" SGW
  SG_ PowerModeSts : 15|2@0+ (1,0) [0|3] "" SGW
  SG_ TrunkReleaseReqCntrl : 16|1@0+ (1,0) [0|1] "" SGW
  SG_ RechargeFlapButtonSts : 19|1@0+ (1,0) [0|1] "" SGW
  SG_ KeySts : 23|4@0+ (1,0) [0|15] "raw" NAB,NVO,SGW
  SG_ ExternalTemperature : 31|8@0+ (0.5,-40) [-39.5|87.5] "°C" NAB,SGW
  SG_ FuelLevelFailSts : 32|1@0+ (1,0) [0|1] "" SGW
  SG_ EngineBonnetSts : 37|1@0+ (1,0) [0|1] "" SGW
  SG_ ExternalTemperatureFailSts : 39|1@0+ (1,0) [0|1] "" NAB,SGW
  SG_ FuelLevelRawValue : 47|8@0+ (1,0) [0|100] "%" SGW
  SG_ FOBSearchRequest : 49|2@0+ (1,0) [0|3] "" SGW
  SG_ TheftAlarmStatus : 52|3@0+ (1,0) [0|7] "" SGW
  SG_ ChargingReleaseReqCntrl : 53|1@0+ (1,0) [0|1] "" SGW
  SG_ NTPCalibrationReqSts : 54|1@0+ (1,0) [0|1] "" SGW

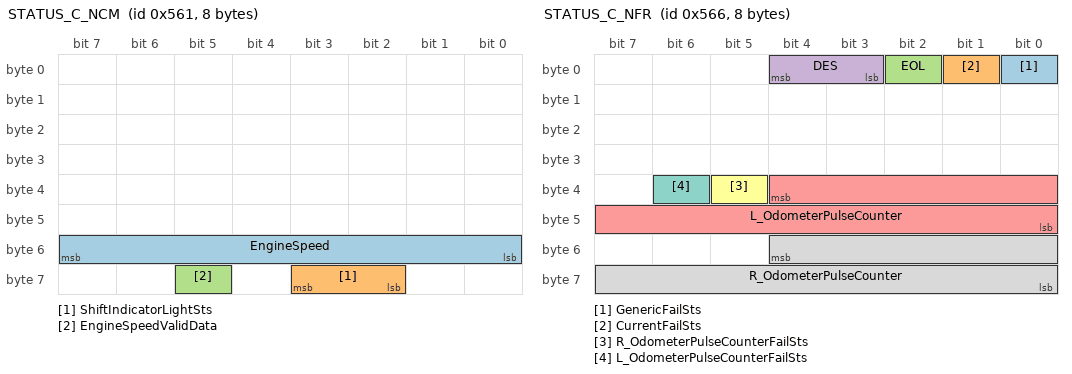
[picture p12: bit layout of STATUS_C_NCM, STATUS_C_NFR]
BO_ 1377 STATUS_C_NCM: 8 SGW
  SG_ EngineSpeed : 55|8@0+ (40,0) [0|10200] "rpm" BCM
  SG_ ShiftIndicatorLightSts : 59|2@0+ (1,0) [0|3] "" Vector__XXX
  SG_ EngineSpeedValidData : 61|1@0+ (1,0) [0|1] "" BCM

BO_ 1382 STATUS_C_NFR: 8 SGW
  SG_ GenericFailSts : 0|1@0+ (1,0) [0|1] "" BCM
  SG_ CurrentFailSts : 1|1@0+ (1,0) [0|1] "" BCM
  SG_ EOL : 2|1@0+ (1,0) [0|1] "" BCM
  SG_ DES : 4|2@0+ (1,0) [0|3] "" BCM
  SG_ L_OdometerPulseCounter : 36|13@0+ (1,0) [0|8191] "pulses" BCM
  SG_ R_OdometerPulseCounterFailSts : 37|1@0+ (1,0) [0|1] "" BCM
  SG_ L_OdometerPulseCounterFailSts : 38|1@0+ (1,0) [0|1] "" BCM
  SG_ R_OdometerPulseCounter : 52|13@0+ (1,0) [0|8191] "pulses" BCM

BO_ 1387 STATUS_C_NCA_NCR: 8 SGW
  SG_ GenericFailSts : 0|1@0+ (1,0) [0|1] "" BCM
  SG_ CurrentFailSts : 1|1@0+ (1,0) [0|1] "" BCM
  SG_ EOL : 2|1@0+ (1,0) [0|1] "" BCM
  SG_ D_ES : 4|2@0+ (1,0) [0|3] "" BCM
  SG_ GPFInfo_NCR_RollingCounter : 9|2@0+ (1,0) [0|3] "" BCM
  SG_ GPFInfo_NCR_Muxed : 14|5@0+ (1,0) [0|31] "" BCM
  SG_ ShiftModeSts : 15|1@0+ (1,0) [0|1] "" BCM
  SG_ Automatic_RoboticXmsnFailSts : 16|1@0+ (1,0) [0|1] "" BCM
  SG_ ActualGearForDisplay : 20|4@0+ (1,0) [0|15] "" BCM,NAB
  SG_ NCDFailSts : 22|2@0+ (1,0) [0|3] "" BCM,NVO
  SG_ GPFInfo_NCR_MuxId : 23|1@0+ (1,0) [0|1] "" BCM
  SG_ LaunchCircularLedSts : 25|2@0+ (1,0) [0|3] "" BCM
  SG_ AutoEPBInhibitionReq : 26|1@0+ (1,0) [0|1] "" BCM
  SG_ Command_Lamp_Fail_Gear : 27|1@0+ (1,0) [0|1] "" BCM
  SG_ BuzzerReqSts : 29|2@0+ (1,0) [0|3] "" BCM
  SG_ GPFInfo_NCR_ValidData : 30|1@0+ (1,0) [0|1] "" BCM
  SG_ GearIndicationSts : 31|1@0+ (1,0) [0|1] "" BCM
  SG_ LaunchLedSts : 33|2@0+ (1,0) [0|3] "" BCM
  SG_ PerformanceLaunchIndication : 35|2@0+ (1,0) [0|3] "" BCM
  SG_ AutomaticRoboticXmsnDegradedMode : 40|1@0+ (1,0) [0|1] "" BCM
  SG_ PerformanceLaunchMode : 41|1@0+ (1,0) [0|1] "" BCM
  SG_ RoboticTransmissionWarning : 47|6@0+ (1,0) [0|63] "" BCM
  SG_ MessageCounter : 51|4@0+ (1,0) [0|15] "" BCM,NVO
  SG_ PLockSts : 53|2@0+ (1,0) [0|3] "" BCM
  SG_ NCR_EPB_Req : 54|1@0+ (1,0) [0|1] "" BCM
  SG_ SailingAct : 55|1@0+ (1,0) [0|1] "" BCM
  SG_ Checksum_STATUS_C_NCA_NCR : 63|8@0+ (1,0) [0|255] "" BCM,NVO

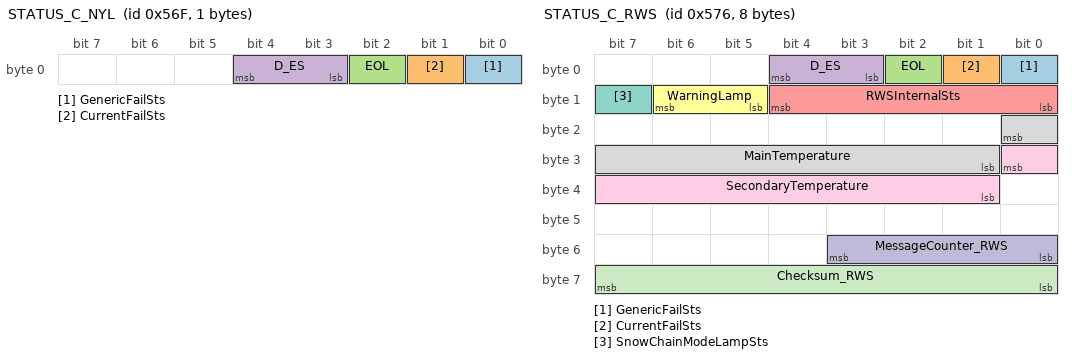
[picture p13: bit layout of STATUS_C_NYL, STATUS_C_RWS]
BO_ 1391 STATUS_C_NYL: 1 SGW
  SG_ GenericFailSts : 0|1@0+ (1,0) [0|1] "" BCM
  SG_ CurrentFailSts : 1|1@0+ (1,0) [0|1] "" BCM
  SG_ EOL : 2|1@0+ (1,0) [0|1] "" BCM
  SG_ D_ES : 4|2@0+ (1,0) [0|3] "" BCM

BO_ 1398 STATUS_C_RWS: 8 SGW
  SG_ GenericFailSts : 0|1@0+ (1,0) [0|1] "" BCM
  SG_ CurrentFailSts : 1|1@0+ (1,0) [0|1] "" BCM
  SG_ EOL : 2|1@0+ (1,0) [0|1] "" BCM
  SG_ D_ES : 4|2@0+ (1,0) [0|3] "" BCM
  SG_ RWSInternalSts : 12|5@0+ (1,0) [0|31] "" Vector__XXX
  SG_ WarningLamp : 14|2@0+ (1,0) [0|3] "" Vector__XXX
  SG_ SnowChainModeLampSts : 15|1@0+ (1,0) [0|1] "" Vector__XXX
  SG_ MainTemperature : 16|8@0+ (1,-40) [-40|150] "°C" Vector__XXX
  SG_ SecondaryTemperature : 24|8@0+ (1,-40) [-40|150] "°C" Vector__XXX
  SG_ MessageCounter_RWS : 51|4@0+ (1,0) [0|15] "" BCM
  SG_ Checksum_RWS : 63|8@0+ (1,0) [0|255] "" BCM

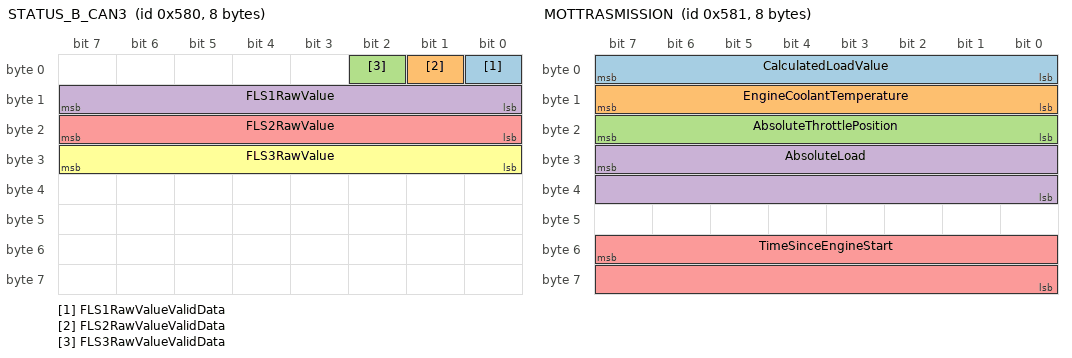
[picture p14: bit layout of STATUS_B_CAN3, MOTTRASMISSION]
BO_ 1408 STATUS_B_CAN3: 8 BCM
  SG_ FLS1RawValueValidData : 0|1@0+ (1,0) [0|1] "" Vector__XXX
  SG_ FLS2RawValueValidData : 1|1@0+ (1,0) [0|1] "" Vector__XXX
  SG_ FLS3RawValueValidData : 2|1@0+ (1,0) [0|1] "" Vector__XXX
  SG_ FLS1RawValue : 15|8@0+ (1,0) [0|100] "%" Vector__XXX
  SG_ FLS2RawValue : 23|8@0+ (1,0) [0|100] "%" Vector__XXX
  SG_ FLS3RawValue : 31|8@0+ (1,0) [0|100] "%" Vector__XXX

BO_ 1409 MOTTRASMISSION: 8 SGW
  SG_ CalculatedLoadValue : 7|8@0+ (0.392,0) [0|99.96] "%" Vector__XXX
  SG_ EngineCoolantTemperature : 15|8@0+ (1,-40) [-40|215] "°C" Vector__XXX
  SG_ AbsoluteThrottlePosition : 23|8@0+ (0.392,0) [0|99.96] "%" NAB
  SG_ AbsoluteLoad : 31|16@0+ (0.392,0) [0|25689.72] "%" Vector__XXX
  SG_ TimeSinceEngineStart : 55|16@0+ (1,0) [0|65535] "sec." Vector__XXX

BO_ 1441 PWT_STATUS_2: 8 SGW
  SG_ CRC_PWT_STATUS_2 : 7|8@0+ (1,0) [0|255] "" BCM,NVO
  SG_ ReducePowerAssist : 9|1@0+ (1,0) [0|1] "" BCM
  SG_ BatteryDisconnectionWarning : 10|1@0+ (1,0) [0|1] "" BCM
  SG_ VCU_EnergyProfileRqt : 13|3@0+ (1,0) [0|7] "" BCM
  SG_ VehicleNotInUse : 15|2@0+ (1,0) [0|3] "" BCM
  SG_ EManettinoSts : 18|3@0+ (1,0) [0|7] "" BCM,NVO
  SG_ EManettinoFailSts : 19|1@0+ (1,0) [0|1] "" BCM,NVO
  SG_ EManettinoTransitionInfo : 22|3@0+ (1,0) [0|7] "" BCM,NVO
  SG_ MVLoadEnable_NPR : 23|1@0+ (1,0) [0|1] "" BCM
  SG_ BatteryVoltageLevel : 30|7@0+ (0.16,0) [0|18] "volt" BCM
  SG_ CruiseControlSts : 31|1@0+ (1,0) [0|1] "" BCM
  SG_ CruiseControlLampSts : 33|2@0+ (1,0) [0|3] "" BCM,NAB,NVO
  SG_ RechargeSts : 34|1@0+ (1,0) [0|1] "" BCM
  SG_ MsgCnt_PWT_STATUS_2 : 38|4@0+ (1,0) [0|15] "" BCM,NVO
  SG_ BatteryVoltageLevelFailSts : 39|1@0+ (1,0) [0|1] "" BCM
  SG_ EngineSts : 45|2@0+ (1,0) [0|3] "" BCM
  SG_ StopStartSts : 47|2@0+ (1,0) [0|3] "" BCM
  SG_ PowertrainSts : 50|3@0+ (1,0) [0|7] "" BCM
  SG_ EDriveSts : 54|2@0+ (1,0) [0|3] "" BCM
  SG_ TargetSpeed : 63|8@0+ (1,0) [0|255] "km/h" BCM,NVO

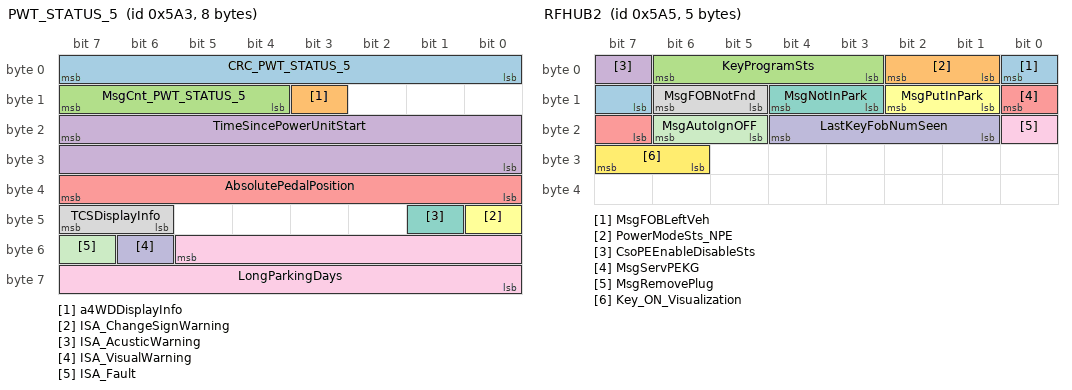
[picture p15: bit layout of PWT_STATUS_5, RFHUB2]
BO_ 1443 PWT_STATUS_5: 8 SGW
  SG_ CRC_PWT_STATUS_5 : 7|8@0+ (1,0) [0|255] "" NVO
  SG_ a4WDDisplayInfo : 11|1@0+ (1,0) [0|1] "" Vector__XXX
  SG_ MsgCnt_PWT_STATUS_5 : 15|4@0+ (1,0) [0|14] "" NVO
  SG_ TimeSincePowerUnitStart : 23|16@0+ (1,0) [0|65535] "sec." Vector__XXX
  SG_ AbsolutePedalPosition : 39|8@0+ (0.392,0) [0|99.96] "%" NAB
  SG_ ISA_ChangeSignWarning : 40|1@0+ (1,0) [0|1] "" Vector__XXX
  SG_ ISA_AcusticWarning : 41|1@0+ (1,0) [0|1] "" Vector__XXX
  SG_ TCSDisplayInfo : 47|2@0+ (1,0) [0|3] "" NAB,NVO
  SG_ LongParkingDays : 53|14@0+ (1,0) [0|9999] "" Vector__XXX
  SG_ ISA_VisualWarning : 54|1@0+ (1,0) [0|1] "" Vector__XXX
  SG_ ISA_Fault : 55|1@0+ (1,0) [0|1] "" Vector__XXX

BO_ 1445 RFHUB2: 5 BCM
  SG_ MsgFOBLeftVeh : 0|2@0+ (1,0) [0|3] "" SGW
  SG_ PowerModeSts_NPE : 2|2@0+ (1,0) [0|3] "" SGW
  SG_ KeyProgramSts : 6|4@0+ (1,0) [0|15] "" SGW
  SG_ CsoPEEnableDisableSts : 7|1@0+ (1,0) [0|1] "" SGW
  SG_ MsgServPEKG : 8|2@0+ (1,0) [0|3] "" SGW
  SG_ MsgPutInPark : 10|2@0+ (1,0) [0|3] "" SGW
  SG_ MsgNotInPark : 12|2@0+ (1,0) [0|3] "" SGW
  SG_ MsgFOBNotFnd : 14|2@0+ (1,0) [0|3] "" SGW
  SG_ MsgRemovePlug : 16|1@0+ (1,0) [0|1] "" SGW
  SG_ LastKeyFobNumSeen : 20|4@0+ (1,0) [0|15] "" SGW
  SG_ MsgAutoIgnOFF : 22|2@0+ (1,0) [0|3] "" SGW
  SG_ Key_ON_Visualization : 31|2@0+ (1,0) [0|3] "" SGW

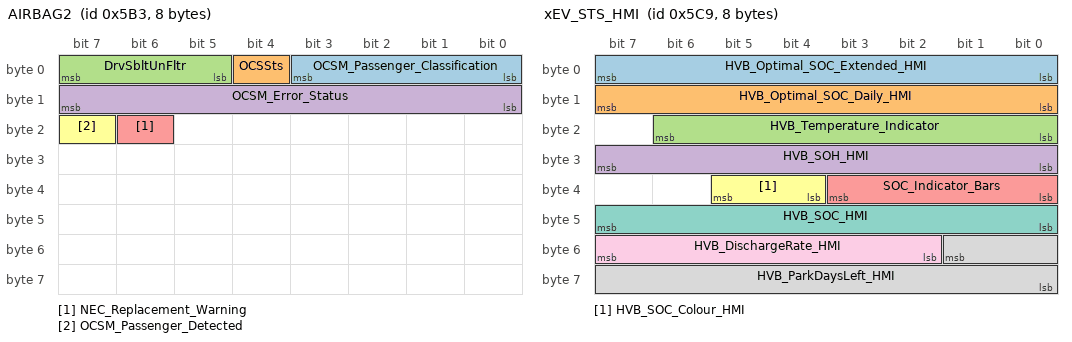
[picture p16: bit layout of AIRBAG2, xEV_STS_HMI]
BO_ 1459 AIRBAG2: 8 NAB
  SG_ OCSM_Passenger_Classification : 3|4@0+ (1,0) [0|15] "" SGW
  SG_ OCSSts : 4|1@0+ (1,0) [0|1] "" SGW
  SG_ DrvSbltUnFltr : 7|3@0+ (1,0) [0|7] "" SGW
  SG_ OCSM_Error_Status : 15|8@0+ (1,0) [0|255] "" SGW
  SG_ NEC_Replacement_Warning : 22|1@0+ (1,0) [0|1] "" BCM,SGW
  SG_ OCSM_Passenger_Detected : 23|1@0+ (1,0) [0|1] "" SGW

BO_ 1481 xEV_STS_HMI: 8 SGW
  SG_ HVB_Optimal_SOC_Extended_HMI : 7|8@0+ (0.39215686274509803,0) [0|100] "%" BCM
  SG_ HVB_Optimal_SOC_Daily_HMI : 15|8@0+ (0.39215686274509803,0) [0|100] "%" BCM
  SG_ HVB_Temperature_Indicator : 22|7@0+ (1,-31) [-31|86] "°C" BCM
  SG_ HVB_SOH_HMI : 31|8@0+ (0.39215686274509803,0) [0|100] "%" BCM
  SG_ SOC_Indicator_Bars : 35|4@0+ (1,0) [0|15] "" BCM
  SG_ HVB_SOC_Colour_HMI : 37|2@0+ (1,0) [0|3] "" BCM
  SG_ HVB_SOC_HMI : 47|8@0+ (0.39215686274509803,0) [0|100] "%" BCM
  SG_ HVB_ParkDaysLeft_HMI : 49|10@0+ (1,0) [0|1023] "day" BCM
  SG_ HVB_DischargeRate_HMI : 55|6@0+ (0.1,0) [0|6.4] "%/h" BCM

BO_ 1485 HVB_HMI_STS: 8 SGW
  SG_ CRC_HVB_HMI_STS : 7|8@0+ (1,0) [0|255] "" BCM
  SG_ LongParkingInfoForDisplay : 10|3@0+ (1,0) [0|7] "" BCM
  SG_ HVBBuzzerReq : 11|1@0+ (1,0) [0|1] "" BCM
  SG_ MsgCnt_HVB_HMI_STS : 15|4@0+ (1,0) [0|14] "" BCM
  SG_ HVBChargeWarningForDisplay : 20|5@0+ (1,0) [0|31] "" BCM
  SG_ LongParkingSts : 21|1@0+ (1,0) [0|1] "" BCM
  SG_ HVBSOC_Status_HMI : 23|2@0+ (1,0) [0|3] "" BCM
  SG_ HVB_SOC_BEV_HMI : 31|8@0+ (0.39215686274509803,0) [0|100] "%" BCM
  SG_ HVB_TemperatureFailSts : 33|2@0+ (1,0) [0|3] "" BCM
  SG_ BatPrecondSts : 35|2@0+ (1,0) [0|3] "" BCM
  SG_ HVSysWarningForDisplay : 39|4@0+ (1,0) [0|15] "" BCM
  SG_ BatEstTimeToTarget : 46|7@0+ (1,0) [0|127] "min" BCM
  SG_ MILrequest : 47|1@0+ (1,0) [0|1] "" BCM
  SG_ BatPrecondProgress : 55|8@0+ (0.5,0) [0|127.5] "%" BCM
  SG_ HVBWarningForDisplay : 60|5@0+ (1,0) [0|31] "" BCM
  SG_ HVBStatus : 62|2@0+ (1,0) [0|3] "" BCM
  SG_ HVBSOC_Status_China_HMI : 63|1@0+ (1,0) [0|1] "" BCM

CM_ BU_ BCM "Nodo Body Computer";
CM_ BU_ NAB "Nodo AIRbag";
CM_ BU_ NVO "Nodo Volante";
CM_ BO_ 175 "{For F173: Sender = NYL}";
CM_ BO_ 1382 "All values less than the minimun VehicleSpeed sensitivity (actually 1.75 Km/h) must be set to 0";
CM_ BO_ 1391 "{For F173: Sender = NYL}";
CM_ BO_ 1409 "{For F173: Sender = NCM_SX}";
CM_ SG_ 57 Rnd_4 "In case the 4 byte field rnd_1 to rnd_4 is processed as a 32 bit integer, rnd_1 is the Most Significant Byte and rnd_4 the Least Significant Byte";
CM_ SG_ 57 F1_2 "In case the 2 byte field f2_1 to f2_2 is processed as a 16 bit integer, f2_1 is the Most Significant Byte and f2_2 is the Least Significant Byte";
CM_ SG_ 64 MKKey_2_or_g2_2 "In case the 2 byte field g2_1 to g2_2 is processed as a 16 bit integer, g2_1 is the Most Significant Byte and g2_2 is the Least Significant Byte";
CM_ SG_ 64 MKKey_6 "In case the 6 byte field MKKey_1 to MKKey_6 is processed as a 48 bit integer, MKKey_1 is the Most Significant Byte and MKKey_6 the Least Significant Byte";
CM_ SG_ 76 GearEngaged "{For 8Marce: Property = 'Not Coded'}";
CM_ SG_ 76 FutureSyncGear "{For 8Marce: Property = 'Not Coded'}";
CM_ SG_ 76 AMTIndex "values can be in the range [0-100]
0: full overlapshift
100: amtshift";
CM_ SG_ 175 CRC "CRC according to SAE
J1850 standard";
CM_ SG_ 222 CRC_G "CRC according to SAE J1850 standard ";
CM_ SG_ 262 MessageCounter_ETO "Calculated by SAE-J1850";
CM_ SG_ 359 RFRearFuncReq "{For F175: Sig_name = RFRearFuncReq}";
CM_ SG_ 359 FobSearchResult "   7         6       5       4         3              2                 1                 0
|Status|Status|Fault|Trunk|Interior|ExteriorRight|ExteriorLeft|ExteriorRear|

Status is 2 bits encoded as:
  7     6
  0     0   = NO_ACTION
  0     1   = IN_PROGRESS
  1     0   = COMPLETE
  1     1   = TIMEOUT

Fault: 0 = NO_FAULT, 1 = FAULT

Trunk, Interior, ExteriorRight, ExteriorLeft, ExteriorRear: 
0 = NO_FOB_IN_ZONE, 1 = FOB_IN_ZONE";
CM_ SG_ 359 FobSearchResult_LongPressure "Passive Entry system (ASC-PE)";
CM_ SG_ 523 ACCFSafe "?";
CM_ SG_ 523 message_counter_B2 "SAE J1850";
CM_ SG_ 523 CRC_B2 "SAE J1850";
CM_ SG_ 524 VehicleSpeedVSOSig "Speed is computed based on driven wheels ( rear wheels for Ferrari-Maserati )
This value is computed as the STATUS_C-NFR.VehicleSpeed received by NBC.
Signal not valid for 500ms after startup ";
CM_ SG_ 524 VehicleSpeedVSOSigFailSts "Signal not valid for 500ms after startup";
CM_ SG_ 524 MsgCounter "SAE J1850";
CM_ SG_ 524 Checksum "According to SAE J1850";
CM_ SG_ 599 ChecksumNAB1 "According SAE J-1850";
CM_ SG_ 625 GasPedalPosition "See Functional Requirements";
CM_ SG_ 865 VehDriverReqTrq "Nm @ clutch level";
CM_ SG_ 865 CylCutEnabled "Partial_cylinder_injection_cut_[enabled/not_enabled]_for_DCT";
CM_ SG_ 865 EngineSpeed "For Ferrari application FFFFhex means :
Data NotValid (Failure)
140322: Remove NOTE $FFFF as invalid value";
CM_ SG_ 980 ManettinoSuspensionSts "(*) See Project SFS for positions name definition";
CM_ SG_ 980 ManettinoSts "See Project SFS for positions name definition
Position 0 has not to be used by any project";
CM_ SG_ 988 TyrePressureSystemSts "TPMS_STAT_OFF";
CM_ SG_ 988 TyrePressureSystemFailSts "TPMS_STAT_SERVICE";
CM_ SG_ 988 TyrePressureSysCalibrationSts "TPMS_STAT_NOTCAL";
CM_ SG_ 988 NTPTempNotActiveSts "TPMS_STAT_TEMPNOTACT";
CM_ SG_ 988 NTPCalibrationReqACK "TPMS_STAT_CALACK";
CM_ SG_ 1023 MsgCounter_LCUCmd "SAE J1850";
CM_ SG_ 1023 Checksum_LCUCmd "SAE J1850";
CM_ SG_ 1286 NFRSts "NVO FAILURE with values (2) and (3)";
CM_ SG_ 1286 ServiceLampBlinkFreq "Note:Without  ServiceLamp ON no blinkfrequency can be set.
Blinking must be processed with Colors set by ServiceLampColors Blinking means Flashing";
CM_ SG_ 1286 PBDisplayInfo "(1) See function F252";
CM_ SG_ 1286 WarningLampReq "Indicates all malfunctions ";
CM_ SG_ 1286 ServiceLampReq "Indicates all safety related malfunctions and system functions";
CM_ SG_ 1286 Checksum "According SAE J-1850";
CM_ SG_ 1312 message_counter_B01 "SAE J1850";
CM_ SG_ 1312 CRC_B01 "SAE J1850";
CM_ SG_ 1313 STS_DRS_DriverLatchsts "Passive Entry system (ASC-PE)";
CM_ SG_ 1313 STS_DRS_PsngrDoorSts "Passive Entry system (ASC-PE)";
CM_ SG_ 1313 STS_DRS_DriverDoorSts "Passive Entry system (ASC-PE)";
CM_ SG_ 1313 STS_DRS_RearRightLatchsts "Passive Entry system (ASC-PE)";
CM_ SG_ 1313 STS_DRS_RearLeftDoorSts "Passive Entry system (ASC-PE)";
CM_ SG_ 1313 STS_DRS_RearRightDoorSts "Passive Entry system (ASC-PE)";
CM_ SG_ 1313 STS_DRS_PsngrLatchsts "Passive Entry system (ASC-PE)";
CM_ SG_ 1313 STS_DRS_RearLeftLatchsts "Passive Entry system (ASC-PE)";
CM_ SG_ 1313 STS_DRS_MsgCounter "Passive Entry system (ASC-PE)";
CM_ SG_ 1313 STS_DRS_Checksum "According SAE J-1850 - Passive Entry system (ASC-PE)";
CM_ SG_ 1318 BrakePressureTarget "Target pressure value available by wire (p_TAR), it includes externnal brake requests (ACC, ?) NOT Available in Back Up mode";
CM_ SG_ 1318 DriverBrkPressureRqt "If valid, it is the master cylinder pressure (pMC), in the 'driver circuit'. Only in by wire mode is related to Brake Rod Stroke (sPTS) by the DBR-curve. In back Up mode reflects the actual pressure in the caliper circuit. ";
CM_ SG_ 1318 BrakePressureActual "Maximum pressure value available at wheels (pS_SP). NOTAvailable in Back Up mode";
CM_ SG_ 1318 StopLightActRqt "This signal is internally used by NBC only. There aren?t any changes for Gateway Function.";
CM_ SG_ 1318 BrakeRodStroke "Available in both 'by wire' and 'Back Up' mode.
Indicate if the Bake pedal is pressed or not AND the amount of the Rod stroke";
CM_ SG_ 1318 BrakePedalSts "Available in both 'by wire' and 'Back Up' mode.
Indicate if the Bake pedal is pressed or not";
CM_ SG_ 1318 DriverBrkPressureRqtValidData "Signal not valid for 800ms after startup";
CM_ SG_ 1376 TrunkReleaseReqCntrl "Passive Entry system (ASC-PE)";
CM_ SG_ 1376 ExternalTemperature "value = -40°C. This value is not the real extenal temperature processed: it means means no valid data available";
CM_ SG_ 1377 EngineSpeed "For Ferrari application Range High is extended from 8000 to 10200 rpm.
Resolution has been increased from 32 to 40 rpm.";
CM_ SG_ 1387 NCDFailSts "0 niente
1 spia ambra
2 spia ambra e richiesta a NVO di forzare il manettino in prima posizione
3 spia rossa e richiesta a NVO di forzare il manettino in prima posizione";
CM_ SG_ 1387 PLockSts "{For VetturaTermica: Sig_name = PLockSts}";
CM_ SG_ 1387 NCR_EPB_Req "{For VetturaTermica: Sig_name = NCR_EPB_Req}";
CM_ SG_ 1398 Checksum_RWS "According SAE J-1850";
CM_ SG_ 1441 BatteryDisconnectionWarning "signal used to inform the driver to don't disconnect the Battery";
CM_ SG_ 1441 EngineSts "This signal indicates the engine state.";
CM_ SG_ 1441 StopStartSts "Engine restart: active 80 mSec before restart, 3 seconds after engine ON";
CM_ SG_ 1485 MILrequest "request mil lamp";

BA_DEF_ SG_  "GenSigSendType" ENUM "NotUsed","OnWrite","OnWriteWithRepetition","OnChange","OnChangeWithRepetition","IfActive","IfActiveWithRepetition","NoSigSendType";
BA_DEF_ SG_  "GenSigInactiveValue" INT 0 2147483647;
BA_DEF_ SG_  "GenSigStartValue" INT 0 2147483647;
BA_DEF_ BO_  "DiagState" ENUM "No","Yes";
BA_DEF_ BO_  "GenMsgDelayTime" INT 0 65535;
BA_DEF_ BO_  "GenMsgCycleTimeFast" INT 0 65535;
BA_DEF_ BO_  "GenMsgStartDelayTime" INT 0 65535;
BA_DEF_ BO_  "GenMsgILSupport" ENUM "No","Yes";
BA_DEF_ BO_  "GenMsgTimeoutTime" INT 0 10000;
BA_DEF_ BO_  "GenMsgSendType" ENUM "Cyclic","NotUsed","NotUsed","NotUsed","NotUsed","NotUsed","NotUsed","NotUsed","NoMsgSendType";
BA_DEF_ BO_  "NmMessage" ENUM "No","Yes";
BA_DEF_ BO_  "Type" ENUM "P","C","PE","COC","PE_Cntrl","E","E_Cntrl","OC","S","BAF","DC","EM","MM","-";
BA_DEF_ BO_  "Period" INT 0 65535;
BA_DEF_ BU_  "TpOwnSystemEcuNumber" HEX 0 255;
BA_DEF_ BU_  "NwmNodeType" ENUM "kMaster","kSlave15","kSlave30","none";
BA_DEF_ BU_  "NmNodeType" ENUM "kMaster","kSlave15","kSlave30","none";
BA_DEF_ BU_  "ILUsed" ENUM "No","Yes";
BA_DEF_ BU_  "NmNode" ENUM "No","Yes";
BA_DEF_ BU_  "NmStationAddress" HEX 0 255;
BA_DEF_ BU_  "NodeLayerModules" STRING;
BA_DEF_ BU_  "Description" STRING;
BA_DEF_ BU_  "NodeAddress" INT 0 127;
BA_DEF_  "Manufacturer" STRING;
BA_DEF_  "VersionYear" INT 0 99;
BA_DEF_  "VersionWeek" INT 0 53;
BA_DEF_  "Version" HEX 0 255;
BA_DEF_  "DBName" STRING;
BA_DEF_  "Baudrate_ARB" INT 0 1000000;
BA_DEF_  "Baudrate_DATA" INT 0 0;
BA_DEF_  "NmType" STRING;
BA_DEF_  "BusType" STRING;
BA_DEF_ SG_  "EventTrans" ENUM "Yes","No";
BA_DEF_ SG_  "Accuracy" STRING;
BA_DEF_ SG_  "SignalAge" INT 0 100000;
BA_DEF_ SG_  "InitialValue" INT -65536 65535;
BA_DEF_ BO_  "DiagResponse" ENUM "No","Yes";
BA_DEF_ BO_  "DiagRequest" ENUM "No","Yes";
BA_DEF_ BO_  "GenMsgCycleTime" INT 0 10000;

BA_DEF_DEF_  "Baudrate_ARB" 500000;
BA_DEF_DEF_  "Baudrate_DATA" 500000;
BA_DEF_DEF_  "DBName" "CAN";
BA_DEF_DEF_  "DiagRequest" "No";
BA_DEF_DEF_  "DiagResponse" "No";
BA_DEF_DEF_  "DiagState" "No";
BA_DEF_DEF_  "EventTrans" "No";
BA_DEF_DEF_  "GenMsgCycleTime" 0;
BA_DEF_DEF_  "GenMsgCycleTimeFast" 0;
BA_DEF_DEF_  "GenMsgDelayTime" 0;
BA_DEF_DEF_  "GenMsgILSupport" "No";
BA_DEF_DEF_  "GenMsgSendType" "NoMsgSendType";
BA_DEF_DEF_  "GenMsgStartDelayTime" 0;
BA_DEF_DEF_  "GenMsgTimeoutTime" 0;
BA_DEF_DEF_  "GenSigInactiveValue" 0;
BA_DEF_DEF_  "GenSigSendType" "NoSigSendType";
BA_DEF_DEF_  "GenSigStartValue" 0;
BA_DEF_DEF_  "ILUsed" "Yes";
BA_DEF_DEF_  "InitialValue" 0;
BA_DEF_DEF_  "Manufacturer" "Ferrari";
BA_DEF_DEF_  "NmMessage" "No";
BA_DEF_DEF_  "NmNode" "Yes";
BA_DEF_DEF_  "NmNodeType" "none";
BA_DEF_DEF_  "NmStationAddress" 0;
BA_DEF_DEF_  "NodeAddress" 0;
BA_DEF_DEF_  "NodeLayerModules" "Osek_TP.dll";
BA_DEF_DEF_  "NwmNodeType" "none";
BA_DEF_DEF_  "Period" 0;
BA_DEF_DEF_  "SignalAge" 0;
BA_DEF_DEF_  "TpOwnSystemEcuNumber" 0;
BA_DEF_DEF_  "Type" "-";
BA_DEF_DEF_  "Version" 160;
BA_DEF_DEF_  "VersionWeek" 51;
BA_DEF_DEF_  "VersionYear" 13;

BA_ "BusType" "CAN";
BA_ "Manufacturer" "Fiat";
BA_ "NmType" "Fiat_Class_C";
BA_ "Version" 0;
BA_ "VersionWeek" 0;
BA_ "VersionYear" 0;
BA_ "Description" BU_ BCM "Nodo Body Computer";
BA_ "NmNodeType" BU_ BCM 0;
BA_ "NmStationAddress" BU_ BCM 64;
BA_ "NodeLayerModules" BU_ BCM "CANoeILNLFiat.dll";
BA_ "NwmNodeType" BU_ BCM 0;
BA_ "TpOwnSystemEcuNumber" BU_ BCM 64;
BA_ "Description" BU_ NAB "Nodo AIRbag";
BA_ "NmNodeType" BU_ NAB 2;
BA_ "NmStationAddress" BU_ NAB 192;
BA_ "NodeAddress" BU_ NAB 26;
BA_ "NodeLayerModules" BU_ NAB "CANoeILNLFiat.dll";
BA_ "NwmNodeType" BU_ NAB 2;
BA_ "TpOwnSystemEcuNumber" BU_ NAB 192;
BA_ "Description" BU_ NVO "Nodo Volante";
BA_ "NmStationAddress" BU_ NVO 143;
BA_ "NodeAddress" BU_ NVO 4;
BA_ "TpOwnSystemEcuNumber" BU_ NVO 143;
BA_ "NmStationAddress" BU_ SGW 203;
BA_ "NodeAddress" BU_ SGW 89;
BA_ "TpOwnSystemEcuNumber" BU_ SGW 203;
BA_ "DiagRequest" BO_ 57 1;
BA_ "Type" BO_ 57 8;
BA_ "DiagResponse" BO_ 64 1;
BA_ "Type" BO_ 64 8;
BA_ "GenMsgCycleTime" BO_ 76 10;
BA_ "GenMsgILSupport" BO_ 76 1;
BA_ "GenMsgSendType" BO_ 76 0;
BA_ "GenMsgTimeoutTime" BO_ 76 2500;
BA_ "Period" BO_ 76 10;
BA_ "Type" BO_ 76 0;
BA_ "GenMsgCycleTime" BO_ 175 10;
BA_ "GenMsgCycleTime" BO_ 175 10;
BA_ "GenMsgILSupport" BO_ 175 1;
BA_ "GenMsgSendType" BO_ 175 0;
BA_ "GenMsgTimeoutTime" BO_ 175 2500;
BA_ "Period" BO_ 175 10;
BA_ "Period" BO_ 175 10;
BA_ "Type" BO_ 175 1;
BA_ "GenMsgCycleTime" BO_ 222 10;
BA_ "GenMsgILSupport" BO_ 222 1;
BA_ "GenMsgSendType" BO_ 222 0;
BA_ "GenMsgTimeoutTime" BO_ 222 2500;
BA_ "Period" BO_ 222 10;
BA_ "Type" BO_ 222 1;
BA_ "GenMsgCycleTime" BO_ 262 10;
BA_ "GenMsgILSupport" BO_ 262 1;
BA_ "GenMsgSendType" BO_ 262 0;
BA_ "GenMsgTimeoutTime" BO_ 262 2500;
BA_ "Period" BO_ 262 10;
BA_ "Type" BO_ 262 1;
BA_ "GenMsgCycleTime" BO_ 359 20;
BA_ "GenMsgILSupport" BO_ 359 1;
BA_ "GenMsgSendType" BO_ 359 0;
BA_ "GenMsgTimeoutTime" BO_ 359 2500;
BA_ "Period" BO_ 359 20;
BA_ "Type" BO_ 359 1;
BA_ "GenMsgCycleTime" BO_ 502 10;
BA_ "GenMsgCycleTime" BO_ 502 10;
BA_ "GenMsgILSupport" BO_ 502 1;
BA_ "GenMsgSendType" BO_ 502 0;
BA_ "GenMsgTimeoutTime" BO_ 502 2500;
BA_ "GenMsgTimeoutTime" BO_ 502 2500;
BA_ "Period" BO_ 502 10;
BA_ "Period" BO_ 502 10;
BA_ "Type" BO_ 502 1;
BA_ "GenMsgCycleTime" BO_ 523 20;
BA_ "GenMsgILSupport" BO_ 523 1;
BA_ "GenMsgSendType" BO_ 523 0;
BA_ "GenMsgTimeoutTime" BO_ 523 2500;
BA_ "Period" BO_ 523 20;
BA_ "Type" BO_ 523 0;
BA_ "GenMsgCycleTime" BO_ 524 20;
BA_ "GenMsgCycleTime" BO_ 524 20;
BA_ "GenMsgILSupport" BO_ 524 1;
BA_ "GenMsgSendType" BO_ 524 0;
BA_ "GenMsgTimeoutTime" BO_ 524 2500;
BA_ "Period" BO_ 524 20;
BA_ "Period" BO_ 524 20;
BA_ "Type" BO_ 524 0;
BA_ "GenMsgCycleTime" BO_ 599 100;
BA_ "GenMsgCycleTime" BO_ 599 100;
BA_ "GenMsgDelayTime" BO_ 599 10;
BA_ "GenMsgDelayTime" BO_ 599 10;
BA_ "GenMsgILSupport" BO_ 599 1;
BA_ "GenMsgSendType" BO_ 599 0;
BA_ "GenMsgTimeoutTime" BO_ 599 2500;
BA_ "Period" BO_ 599 100;
BA_ "Period" BO_ 599 100;
BA_ "Type" BO_ 599 3;
BA_ "GenMsgCycleTime" BO_ 625 10;
BA_ "GenMsgILSupport" BO_ 625 1;
BA_ "GenMsgSendType" BO_ 625 0;
BA_ "GenMsgTimeoutTime" BO_ 625 2500;
BA_ "Period" BO_ 625 10;
BA_ "Type" BO_ 625 1;
BA_ "GenMsgCycleTime" BO_ 630 20;
BA_ "GenMsgCycleTime" BO_ 630 20;
BA_ "GenMsgILSupport" BO_ 630 1;
BA_ "GenMsgSendType" BO_ 630 0;
BA_ "GenMsgTimeoutTime" BO_ 630 2500;
BA_ "Period" BO_ 630 20;
BA_ "Period" BO_ 630 20;
BA_ "Type" BO_ 630 0;
BA_ "GenMsgCycleTime" BO_ 653 50;
BA_ "GenMsgCycleTime" BO_ 653 50;
BA_ "GenMsgILSupport" BO_ 653 1;
BA_ "GenMsgSendType" BO_ 653 0;
BA_ "GenMsgTimeoutTime" BO_ 653 2500;
BA_ "Period" BO_ 653 50;
BA_ "Period" BO_ 653 50;
BA_ "Type" BO_ 653 1;
BA_ "GenMsgCycleTime" BO_ 654 50;
BA_ "GenMsgILSupport" BO_ 654 1;
BA_ "GenMsgSendType" BO_ 654 0;
BA_ "GenMsgTimeoutTime" BO_ 654 2500;
BA_ "Period" BO_ 654 50;
BA_ "Type" BO_ 654 1;
BA_ "GenMsgCycleTime" BO_ 670 20;
BA_ "GenMsgDelayTime" BO_ 670 10;
BA_ "GenMsgILSupport" BO_ 670 1;
BA_ "GenMsgTimeoutTime" BO_ 670 2500;
BA_ "Period" BO_ 670 20;
BA_ "Type" BO_ 670 1;
BA_ "GenMsgCycleTime" BO_ 761 100;
BA_ "GenMsgILSupport" BO_ 761 1;
BA_ "GenMsgSendType" BO_ 761 0;
BA_ "GenMsgTimeoutTime" BO_ 761 2500;
BA_ "Period" BO_ 761 100;
BA_ "Type" BO_ 761 1;
BA_ "GenMsgCycleTime" BO_ 778 100;
BA_ "GenMsgILSupport" BO_ 778 1;
BA_ "GenMsgSendType" BO_ 778 0;
BA_ "GenMsgTimeoutTime" BO_ 778 2500;
BA_ "Period" BO_ 778 100;
BA_ "Type" BO_ 778 1;
BA_ "GenMsgCycleTime" BO_ 865 10;
BA_ "GenMsgCycleTime" BO_ 865 10;
BA_ "GenMsgILSupport" BO_ 865 1;
BA_ "GenMsgSendType" BO_ 865 0;
BA_ "GenMsgTimeoutTime" BO_ 865 2500;
BA_ "Period" BO_ 865 10;
BA_ "Period" BO_ 865 10;
BA_ "Type" BO_ 865 0;
BA_ "GenMsgCycleTime" BO_ 980 100;
BA_ "GenMsgCycleTime" BO_ 980 100;
BA_ "GenMsgILSupport" BO_ 980 1;
BA_ "GenMsgSendType" BO_ 980 0;
BA_ "GenMsgTimeoutTime" BO_ 980 2500;
BA_ "Period" BO_ 980 100;
BA_ "Period" BO_ 980 100;
BA_ "Type" BO_ 980 0;
BA_ "GenMsgCycleTime" BO_ 988 500;
BA_ "GenMsgCycleTime" BO_ 988 500;
BA_ "GenMsgCycleTimeFast" BO_ 988 500;
BA_ "GenMsgILSupport" BO_ 988 1;
BA_ "GenMsgSendType" BO_ 988 0;
BA_ "GenMsgTimeoutTime" BO_ 988 2500;
BA_ "Period" BO_ 988 500;
BA_ "Period" BO_ 988 500;
BA_ "Type" BO_ 988 3;
BA_ "GenMsgCycleTime" BO_ 1023 100;
BA_ "GenMsgDelayTime" BO_ 1023 10;
BA_ "GenMsgILSupport" BO_ 1023 1;
BA_ "GenMsgSendType" BO_ 1023 0;
BA_ "GenMsgStartDelayTime" BO_ 1023 10;
BA_ "GenMsgTimeoutTime" BO_ 1023 2500;
BA_ "Period" BO_ 1023 100;
BA_ "Type" BO_ 1023 3;
BA_ "GenMsgCycleTime" BO_ 1024 60;
BA_ "GenMsgDelayTime" BO_ 1024 10;
BA_ "GenMsgILSupport" BO_ 1024 1;
BA_ "GenMsgSendType" BO_ 1024 0;
BA_ "GenMsgStartDelayTime" BO_ 1024 10;
BA_ "GenMsgTimeoutTime" BO_ 1024 2500;
BA_ "Period" BO_ 1024 60;
BA_ "Type" BO_ 1024 0;
BA_ "GenMsgCycleTime" BO_ 1035 100;
BA_ "GenMsgILSupport" BO_ 1035 1;
BA_ "GenMsgSendType" BO_ 1035 0;
BA_ "GenMsgTimeoutTime" BO_ 1035 2500;
BA_ "Period" BO_ 1035 100;
BA_ "Type" BO_ 1035 1;
BA_ "GenMsgCycleTime" BO_ 1109 100;
BA_ "GenMsgILSupport" BO_ 1109 1;
BA_ "GenMsgSendType" BO_ 1109 0;
BA_ "GenMsgTimeoutTime" BO_ 1109 2500;
BA_ "Period" BO_ 1109 100;
BA_ "Type" BO_ 1109 1;
BA_ "GenMsgCycleTime" BO_ 1212 100;
BA_ "GenMsgILSupport" BO_ 1212 1;
BA_ "GenMsgSendType" BO_ 1212 0;
BA_ "GenMsgTimeoutTime" BO_ 1212 2500;
BA_ "Period" BO_ 1212 100;
BA_ "Type" BO_ 1212 3;
BA_ "GenMsgCycleTime" BO_ 1214 500;
BA_ "GenMsgILSupport" BO_ 1214 1;
BA_ "GenMsgSendType" BO_ 1214 0;
BA_ "GenMsgTimeoutTime" BO_ 1214 2500;
BA_ "Period" BO_ 1214 500;
BA_ "Type" BO_ 1214 1;
BA_ "GenMsgCycleTime" BO_ 1261 200;
BA_ "GenMsgILSupport" BO_ 1261 1;
BA_ "GenMsgSendType" BO_ 1261 0;
BA_ "GenMsgTimeoutTime" BO_ 1261 2500;
BA_ "Period" BO_ 1261 200;
BA_ "Type" BO_ 1261 1;
BA_ "GenMsgCycleTime" BO_ 1267 500;
BA_ "GenMsgILSupport" BO_ 1267 1;
BA_ "GenMsgSendType" BO_ 1267 0;
BA_ "GenMsgTimeoutTime" BO_ 1267 2500;
BA_ "Period" BO_ 1267 500;
BA_ "Type" BO_ 1267 1;
BA_ "GenMsgCycleTime" BO_ 1274 20;
BA_ "GenMsgILSupport" BO_ 1274 1;
BA_ "GenMsgSendType" BO_ 1274 0;
BA_ "GenMsgTimeoutTime" BO_ 1274 2500;
BA_ "Period" BO_ 1274 20;
BA_ "Type" BO_ 1274 0;
BA_ "GenMsgCycleTime" BO_ 1275 20;
BA_ "GenMsgILSupport" BO_ 1275 1;
BA_ "GenMsgSendType" BO_ 1275 0;
BA_ "GenMsgTimeoutTime" BO_ 1275 2500;
BA_ "Period" BO_ 1275 20;
BA_ "Type" BO_ 1275 0;
BA_ "GenMsgCycleTime" BO_ 1276 20;
BA_ "GenMsgILSupport" BO_ 1276 1;
BA_ "GenMsgSendType" BO_ 1276 0;
BA_ "GenMsgTimeoutTime" BO_ 1276 2500;
BA_ "Period" BO_ 1276 20;
BA_ "Type" BO_ 1276 0;
BA_ "GenMsgCycleTime" BO_ 1286 100;
BA_ "GenMsgCycleTime" BO_ 1286 100;
BA_ "GenMsgDelayTime" BO_ 1286 10;
BA_ "GenMsgDelayTime" BO_ 1286 10;
BA_ "GenMsgILSupport" BO_ 1286 1;
BA_ "GenMsgSendType" BO_ 1286 0;
BA_ "GenMsgTimeoutTime" BO_ 1286 2500;
BA_ "Period" BO_ 1286 100;
BA_ "Period" BO_ 1286 100;
BA_ "Type" BO_ 1286 1;
BA_ "GenMsgCycleTime" BO_ 1312 50;
BA_ "GenMsgDelayTime" BO_ 1312 10;
BA_ "GenMsgILSupport" BO_ 1312 1;
BA_ "GenMsgSendType" BO_ 1312 0;
BA_ "GenMsgStartDelayTime" BO_ 1312 10;
BA_ "GenMsgTimeoutTime" BO_ 1312 2500;
BA_ "Period" BO_ 1312 50;
BA_ "Type" BO_ 1312 0;
BA_ "GenMsgCycleTime" BO_ 1313 100;
BA_ "GenMsgCycleTime" BO_ 1313 100;
BA_ "GenMsgDelayTime" BO_ 1313 10;
BA_ "GenMsgDelayTime" BO_ 1313 10;
BA_ "GenMsgILSupport" BO_ 1313 1;
BA_ "GenMsgSendType" BO_ 1313 0;
BA_ "GenMsgTimeoutTime" BO_ 1313 2500;
BA_ "Period" BO_ 1313 100;
BA_ "Period" BO_ 1313 100;
BA_ "Type" BO_ 1313 1;
BA_ "GenMsgCycleTime" BO_ 1318 20;
BA_ "GenMsgCycleTime" BO_ 1318 20;
BA_ "GenMsgILSupport" BO_ 1318 1;
BA_ "GenMsgSendType" BO_ 1318 0;
BA_ "GenMsgTimeoutTime" BO_ 1318 2500;
BA_ "Period" BO_ 1318 20;
BA_ "Period" BO_ 1318 20;
BA_ "Type" BO_ 1318 0;
BA_ "GenMsgCycleTime" BO_ 1351 250;
BA_ "GenMsgCycleTime" BO_ 1351 250;
BA_ "GenMsgILSupport" BO_ 1351 1;
BA_ "GenMsgTimeoutTime" BO_ 1351 2500;
BA_ "Period" BO_ 1351 250;
BA_ "Period" BO_ 1351 250;
BA_ "Type" BO_ 1351 3;
BA_ "GenMsgCycleTime" BO_ 1376 100;
BA_ "GenMsgDelayTime" BO_ 1376 10;
BA_ "GenMsgILSupport" BO_ 1376 1;
BA_ "GenMsgSendType" BO_ 1376 0;
BA_ "GenMsgStartDelayTime" BO_ 1376 10;
BA_ "GenMsgTimeoutTime" BO_ 1376 2500;
BA_ "Period" BO_ 1376 100;
BA_ "Type" BO_ 1376 1;
BA_ "GenMsgCycleTime" BO_ 1377 50;
BA_ "GenMsgCycleTime" BO_ 1377 50;
BA_ "GenMsgILSupport" BO_ 1377 1;
BA_ "GenMsgSendType" BO_ 1377 0;
BA_ "GenMsgTimeoutTime" BO_ 1377 2500;
BA_ "Period" BO_ 1377 50;
BA_ "Period" BO_ 1377 50;
BA_ "Type" BO_ 1377 1;
BA_ "GenMsgCycleTime" BO_ 1382 100;
BA_ "GenMsgCycleTime" BO_ 1382 100;
BA_ "GenMsgILSupport" BO_ 1382 1;
BA_ "GenMsgSendType" BO_ 1382 0;
BA_ "GenMsgTimeoutTime" BO_ 1382 2500;
BA_ "Period" BO_ 1382 100;
BA_ "Period" BO_ 1382 100;
BA_ "Type" BO_ 1382 1;
BA_ "GenMsgCycleTime" BO_ 1387 100;
BA_ "GenMsgILSupport" BO_ 1387 1;
BA_ "GenMsgSendType" BO_ 1387 0;
BA_ "GenMsgStartDelayTime" BO_ 1387 20;
BA_ "GenMsgTimeoutTime" BO_ 1387 2500;
BA_ "Period" BO_ 1387 100;
BA_ "Type" BO_ 1387 1;
BA_ "GenMsgCycleTime" BO_ 1391 500;
BA_ "GenMsgILSupport" BO_ 1391 1;
BA_ "GenMsgSendType" BO_ 1391 0;
BA_ "GenMsgTimeoutTime" BO_ 1391 2500;
BA_ "Period" BO_ 1391 500;
BA_ "Type" BO_ 1391 1;
BA_ "GenMsgCycleTime" BO_ 1398 250;
BA_ "GenMsgILSupport" BO_ 1398 1;
BA_ "GenMsgSendType" BO_ 1398 0;
BA_ "GenMsgTimeoutTime" BO_ 1398 2500;
BA_ "Period" BO_ 1398 250;
BA_ "Type" BO_ 1398 0;
BA_ "GenMsgCycleTime" BO_ 1408 100;
BA_ "GenMsgILSupport" BO_ 1408 1;
BA_ "GenMsgSendType" BO_ 1408 0;
BA_ "GenMsgTimeoutTime" BO_ 1408 2500;
BA_ "Period" BO_ 1408 100;
BA_ "Type" BO_ 1408 1;
BA_ "GenMsgCycleTime" BO_ 1409 1000;
BA_ "GenMsgILSupport" BO_ 1409 1;
BA_ "GenMsgSendType" BO_ 1409 0;
BA_ "GenMsgTimeoutTime" BO_ 1409 2500;
BA_ "Period" BO_ 1409 1000;
BA_ "Type" BO_ 1409 0;
BA_ "GenMsgCycleTime" BO_ 1441 50;
BA_ "GenMsgCycleTime" BO_ 1441 50;
BA_ "GenMsgILSupport" BO_ 1441 1;
BA_ "GenMsgSendType" BO_ 1441 0;
BA_ "GenMsgTimeoutTime" BO_ 1441 2500;
BA_ "Period" BO_ 1441 50;
BA_ "Period" BO_ 1441 50;
BA_ "Type" BO_ 1441 1;
BA_ "GenMsgCycleTime" BO_ 1443 500;
BA_ "GenMsgILSupport" BO_ 1443 1;
BA_ "GenMsgSendType" BO_ 1443 0;
BA_ "GenMsgTimeoutTime" BO_ 1443 2500;
BA_ "Period" BO_ 1443 500;
BA_ "Type" BO_ 1443 0;
BA_ "GenMsgCycleTime" BO_ 1445 1000;
BA_ "GenMsgILSupport" BO_ 1445 1;
BA_ "GenMsgSendType" BO_ 1445 0;
BA_ "GenMsgTimeoutTime" BO_ 1445 2500;
BA_ "Period" BO_ 1445 1000;
BA_ "Type" BO_ 1445 1;
BA_ "GenMsgCycleTime" BO_ 1459 1000;
BA_ "GenMsgILSupport" BO_ 1459 1;
BA_ "GenMsgSendType" BO_ 1459 0;
BA_ "GenMsgTimeoutTime" BO_ 1459 2500;
BA_ "Period" BO_ 1459 1000;
BA_ "Type" BO_ 1459 3;
BA_ "GenMsgCycleTime" BO_ 1481 500;
BA_ "GenMsgILSupport" BO_ 1481 1;
BA_ "GenMsgSendType" BO_ 1481 0;
BA_ "GenMsgTimeoutTime" BO_ 1481 2500;
BA_ "Period" BO_ 1481 500;
BA_ "Type" BO_ 1481 1;
BA_ "GenMsgCycleTime" BO_ 1485 500;
BA_ "GenMsgILSupport" BO_ 1485 1;
BA_ "GenMsgSendType" BO_ 1485 0;
BA_ "GenMsgTimeoutTime" BO_ 1485 2500;
BA_ "Period" BO_ 1485 500;
BA_ "Type" BO_ 1485 1;
BA_ "EventTrans" SG_ 57 ControlEncoding 0;
BA_ "GenSigSendType" SG_ 57 ControlEncoding 1;
BA_ "EventTrans" SG_ 57 Rnd_1 0;
BA_ "GenSigSendType" SG_ 57 Rnd_1 1;
BA_ "EventTrans" SG_ 57 Rnd_2 0;
BA_ "GenSigSendType" SG_ 57 Rnd_2 1;
BA_ "EventTrans" SG_ 57 Rnd_3 0;
BA_ "GenSigSendType" SG_ 57 Rnd_3 1;
BA_ "EventTrans" SG_ 57 Rnd_4 0;
BA_ "GenSigSendType" SG_ 57 Rnd_4 1;
BA_ "EventTrans" SG_ 57 F1_1 0;
BA_ "GenSigSendType" SG_ 57 F1_1 1;
BA_ "EventTrans" SG_ 57 F1_2 0;
BA_ "GenSigSendType" SG_ 57 F1_2 1;
BA_ "EventTrans" SG_ 64 ControlEncoding 0;
BA_ "GenSigSendType" SG_ 64 ControlEncoding 1;
BA_ "EventTrans" SG_ 64 MKKey_1_or_g2_1 0;
BA_ "GenSigSendType" SG_ 64 MKKey_1_or_g2_1 1;
BA_ "EventTrans" SG_ 64 MKKey_2_or_g2_2 0;
BA_ "GenSigSendType" SG_ 64 MKKey_2_or_g2_2 1;
BA_ "EventTrans" SG_ 64 MKKey_3 0;
BA_ "GenSigSendType" SG_ 64 MKKey_3 1;
BA_ "EventTrans" SG_ 64 MKKey_4 0;
BA_ "GenSigSendType" SG_ 64 MKKey_4 1;
BA_ "EventTrans" SG_ 64 MKKey_5 0;
BA_ "GenSigSendType" SG_ 64 MKKey_5 1;
BA_ "EventTrans" SG_ 64 MKKey_6 0;
BA_ "GenSigSendType" SG_ 64 MKKey_6 1;
BA_ "Accuracy" SG_ 76 AMTIndex "1";
BA_ "SignalAge" SG_ 76 AMTIndex 10;
BA_ "Accuracy" SG_ 175 CRC "1";
BA_ "SignalAge" SG_ 175 CRC 10;
BA_ "GenSigStartValue" SG_ 175 YRSStat 3;
BA_ "InitialValue" SG_ 175 YRSStat 3;
BA_ "GenSigStartValue" SG_ 175 AYSStat 3;
BA_ "InitialValue" SG_ 175 AYSStat 3;
BA_ "GenSigStartValue" SG_ 175 AXSStat 3;
BA_ "InitialValue" SG_ 175 AXSStat 3;
BA_ "Accuracy" SG_ 175 LongAcceleration "0,02";
BA_ "GenSigStartValue" SG_ 175 LongAcceleration 2048;
BA_ "SignalAge" SG_ 175 LongAcceleration 10;
BA_ "Accuracy" SG_ 175 MessageCounter "1";
BA_ "SignalAge" SG_ 175 MessageCounter 10;
BA_ "Accuracy" SG_ 175 LatAcceleration "0,02";
BA_ "GenSigStartValue" SG_ 175 LatAcceleration 2048;
BA_ "SignalAge" SG_ 175 LatAcceleration 10;
BA_ "Accuracy" SG_ 175 YawRate "0,08";
BA_ "GenSigStartValue" SG_ 175 YawRate 2048;
BA_ "SignalAge" SG_ 175 YawRate 10;
BA_ "Accuracy" SG_ 222 LwsAngle "± 2,8 °";
BA_ "GenSigStartValue" SG_ 222 LwsAngle 7200;
BA_ "SignalAge" SG_ 222 LwsAngle 10;
BA_ "Accuracy" SG_ 222 LwsSpeed "15 °/S";
BA_ "GenSigStartValue" SG_ 222 LwsSpeed 2000;
BA_ "SignalAge" SG_ 222 LwsSpeed 10;
BA_ "SignalAge" SG_ 222 MessageCounter_G 10;
BA_ "Accuracy" SG_ 262 AssistanceTorque "+/- 0,05";
BA_ "GenSigStartValue" SG_ 262 AssistanceTorque 2000;
BA_ "SignalAge" SG_ 262 AssistanceTorque 10;
BA_ "Accuracy" SG_ 262 SteeringColumnTorque "+/- 0,47";
BA_ "GenSigStartValue" SG_ 262 SteeringColumnTorque 1024;
BA_ "SignalAge" SG_ 262 SteeringColumnTorque 10;
BA_ "GenSigStartValue" SG_ 502 TorqueOverlaySteeringReq_HALF 1024;
BA_ "GenSigStartValue" SG_ 523 VehicleStandStillSts 1;
BA_ "InitialValue" SG_ 523 VehicleStandStillSts 1;
BA_ "Accuracy" SG_ 524 VehicleSpeed_ASILx "± 0,0625km/h";
BA_ "SignalAge" SG_ 524 VehicleSpeed_ASILx 10;
BA_ "Accuracy" SG_ 524 VehicleSpeedVSOSig "± 0,0625km/h";
BA_ "SignalAge" SG_ 524 VehicleSpeedVSOSig 10;
BA_ "GenSigStartValue" SG_ 524 VehicleSpeed_ASILxFailSts 1;
BA_ "InitialValue" SG_ 524 VehicleSpeed_ASILxFailSts 1;
BA_ "GenSigStartValue" SG_ 524 VehicleSpeedVSOSigFailSts 1;
BA_ "InitialValue" SG_ 524 VehicleSpeedVSOSigFailSts 1;
BA_ "Accuracy" SG_ 524 NFR_Speed_FA "± 0,0625km/h";
BA_ "SignalAge" SG_ 524 NFR_Speed_FA 20;
BA_ "GenSigStartValue" SG_ 524 NFR_Speed_FA_FailSts 1;
BA_ "InitialValue" SG_ 524 NFR_Speed_FA_FailSts 1;
BA_ "SignalAge" SG_ 524 NFR_Speed_FA_FailSts 20;
BA_ "GenSigStartValue" SG_ 599 SBR2RowCentralSeatBuckleFailSts 3;
BA_ "InitialValue" SG_ 599 SBR2RowCentralSeatBuckleFailSts 3;
BA_ "EventTrans" SG_ 599 AirBagFailSts 0;
BA_ "GenSigSendType" SG_ 599 AirBagFailSts 3;
BA_ "GenSigStartValue" SG_ 599 AirBagFailSts 2;
BA_ "InitialValue" SG_ 599 AirBagFailSts 2;
BA_ "EventTrans" SG_ 599 SBR1RowDriverSeatFailSts 0;
BA_ "GenSigSendType" SG_ 599 SBR1RowDriverSeatFailSts 3;
BA_ "GenSigStartValue" SG_ 599 SBR1RowDriverSeatFailSts 3;
BA_ "InitialValue" SG_ 599 SBR1RowDriverSeatFailSts 3;
BA_ "EventTrans" SG_ 599 SBR1RowDriverSeatConfigSts 0;
BA_ "GenSigSendType" SG_ 599 SBR1RowDriverSeatConfigSts 3;
BA_ "GenSigStartValue" SG_ 599 SBR2RowCentralSeatSts 7;
BA_ "InitialValue" SG_ 599 SBR2RowCentralSeatSts 7;
BA_ "EventTrans" SG_ 599 SBR1RowCentralSeatPPDFailSts 0;
BA_ "GenSigSendType" SG_ 599 SBR1RowCentralSeatPPDFailSts 3;
BA_ "GenSigStartValue" SG_ 599 SBR1RowCentralSeatPPDFailSts 3;
BA_ "InitialValue" SG_ 599 SBR1RowCentralSeatPPDFailSts 3;
BA_ "EventTrans" SG_ 599 SBR1RowPsngrSeatPPDFailSts 0;
BA_ "GenSigSendType" SG_ 599 SBR1RowPsngrSeatPPDFailSts 3;
BA_ "GenSigStartValue" SG_ 599 SBR1RowPsngrSeatPPDFailSts 3;
BA_ "InitialValue" SG_ 599 SBR1RowPsngrSeatPPDFailSts 3;
BA_ "EventTrans" SG_ 599 SBR1RowPsngrSeatBuckleFailSts 0;
BA_ "GenSigSendType" SG_ 599 SBR1RowPsngrSeatBuckleFailSts 3;
BA_ "GenSigStartValue" SG_ 599 SBR1RowPsngrSeatBuckleFailSts 3;
BA_ "InitialValue" SG_ 599 SBR1RowPsngrSeatBuckleFailSts 3;
BA_ "EventTrans" SG_ 599 SBR1RowPsngrSeatConfigSts 0;
BA_ "GenSigSendType" SG_ 599 SBR1RowPsngrSeatConfigSts 3;
BA_ "EventTrans" SG_ 599 SBR1RowDriverSeatSts 0;
BA_ "GenSigSendType" SG_ 599 SBR1RowDriverSeatSts 3;
BA_ "GenSigStartValue" SG_ 599 SBR1RowDriverSeatSts 3;
BA_ "InitialValue" SG_ 599 SBR1RowDriverSeatSts 3;
BA_ "EventTrans" SG_ 599 SBR2RowLeftSeatSts 0;
BA_ "GenSigSendType" SG_ 599 SBR2RowLeftSeatSts 3;
BA_ "GenSigStartValue" SG_ 599 SBR2RowLeftSeatSts 3;
BA_ "InitialValue" SG_ 599 SBR2RowLeftSeatSts 3;
BA_ "EventTrans" SG_ 599 SBR2RowRightSeatFailSts 0;
BA_ "GenSigSendType" SG_ 599 SBR2RowRightSeatFailSts 3;
BA_ "GenSigStartValue" SG_ 599 SBR2RowRightSeatFailSts 3;
BA_ "InitialValue" SG_ 599 SBR2RowRightSeatFailSts 3;
BA_ "EventTrans" SG_ 599 SBR2RowLeftSeatFailSts 0;
BA_ "GenSigSendType" SG_ 599 SBR2RowLeftSeatFailSts 3;
BA_ "GenSigStartValue" SG_ 599 SBR2RowLeftSeatFailSts 3;
BA_ "InitialValue" SG_ 599 SBR2RowLeftSeatFailSts 3;
BA_ "EventTrans" SG_ 599 SBR1RowPsngrSeatSts 0;
BA_ "GenSigSendType" SG_ 599 SBR1RowPsngrSeatSts 3;
BA_ "GenSigStartValue" SG_ 599 SBR1RowPsngrSeatSts 7;
BA_ "InitialValue" SG_ 599 SBR1RowPsngrSeatSts 7;
BA_ "EventTrans" SG_ 599 CrashOutputSts 0;
BA_ "GenSigSendType" SG_ 599 CrashOutputSts 3;
BA_ "EventTrans" SG_ 599 SBR2RowRightSeatSts 0;
BA_ "GenSigSendType" SG_ 599 SBR2RowRightSeatSts 3;
BA_ "GenSigStartValue" SG_ 599 SBR2RowRightSeatSts 3;
BA_ "InitialValue" SG_ 599 SBR2RowRightSeatSts 3;
BA_ "SignalAge" SG_ 599 MessageCounterNAB1 10;
BA_ "EventTrans" SG_ 599 CrashOutputValidData 0;
BA_ "GenSigSendType" SG_ 599 CrashOutputValidData 3;
BA_ "SignalAge" SG_ 599 ChecksumNAB1 10;
BA_ "EventTrans" SG_ 599 AirBagWarningPADLampOnSts 0;
BA_ "GenSigSendType" SG_ 599 AirBagWarningPADLampOnSts 3;
BA_ "EventTrans" SG_ 599 AirBagWarningPADLampOffSts 0;
BA_ "GenSigSendType" SG_ 599 AirBagWarningPADLampOffSts 3;
BA_ "EventTrans" SG_ 599 SBR2RowRightSeatConfigSts 0;
BA_ "GenSigSendType" SG_ 599 SBR2RowRightSeatConfigSts 3;
BA_ "EventTrans" SG_ 599 SBR2RowLeftSeatConfigSts 0;
BA_ "GenSigSendType" SG_ 599 SBR2RowLeftSeatConfigSts 3;
BA_ "EventTrans" SG_ 599 Ppd_psngr_info 0;
BA_ "GenSigSendType" SG_ 599 Ppd_psngr_info 3;
BA_ "EventTrans" SG_ 599 AirBagWarningLampSts 0;
BA_ "GenSigSendType" SG_ 599 AirBagWarningLampSts 3;
BA_ "Accuracy" SG_ 625 GasPedalPosition "± 0,392%";
BA_ "SignalAge" SG_ 625 GasPedalPosition 10;
BA_ "GenSigStartValue" SG_ 630 EPBSts 7;
BA_ "InitialValue" SG_ 630 EPBSts 7;
BA_ "GenSigStartValue" SG_ 630 AutoEPBEnable 1;
BA_ "InitialValue" SG_ 630 AutoEPBEnable 1;
BA_ "GenSigStartValue" SG_ 630 Slope 61;
BA_ "EventTrans" SG_ 670 ACCSystemSts 0;
BA_ "GenSigSendType" SG_ 670 ACCSystemSts 3;
BA_ "EventTrans" SG_ 670 ACC_RadarBlinded 0;
BA_ "GenSigSendType" SG_ 670 ACC_RadarBlinded 3;
BA_ "GenSigStartValue" SG_ 670 ACC_RadarBlinded 1;
BA_ "InitialValue" SG_ 670 ACC_RadarBlinded 1;
BA_ "EventTrans" SG_ 670 RadarBlinded 0;
BA_ "GenSigSendType" SG_ 670 RadarBlinded 3;
BA_ "GenSigStartValue" SG_ 670 RadarBlinded 1;
BA_ "InitialValue" SG_ 670 RadarBlinded 1;
BA_ "EventTrans" SG_ 670 ACCFailReversibleSts 0;
BA_ "GenSigSendType" SG_ 670 ACCFailReversibleSts 3;
BA_ "EventTrans" SG_ 670 DASMTemporaryFailSts 0;
BA_ "GenSigSendType" SG_ 670 DASMTemporaryFailSts 3;
BA_ "GenSigStartValue" SG_ 670 DASMTemporaryFailSts 1;
BA_ "InitialValue" SG_ 670 DASMTemporaryFailSts 1;
BA_ "EventTrans" SG_ 670 DASMFailSts 0;
BA_ "GenSigSendType" SG_ 670 DASMFailSts 3;
BA_ "GenSigStartValue" SG_ 670 DASMFailSts 1;
BA_ "InitialValue" SG_ 670 DASMFailSts 1;
BA_ "EventTrans" SG_ 670 ACCFailSts 0;
BA_ "GenSigSendType" SG_ 670 ACCFailSts 3;
BA_ "GenSigStartValue" SG_ 761 GearLeverPositionforNPE 5;
BA_ "InitialValue" SG_ 761 GearLeverPositionforNPE 5;
BA_ "InitialValue" SG_ 865 VehDriverReqTrq -508;
BA_ "GenSigStartValue" SG_ 865 EngineSpeedValidData 1;
BA_ "InitialValue" SG_ 865 EngineSpeedValidData 1;
BA_ "Accuracy" SG_ 865 EngineSpeed "± 1/min";
BA_ "EventTrans" SG_ 980 ManettinoSuspensionSts 0;
BA_ "GenSigSendType" SG_ 980 ManettinoSuspensionSts 3;
BA_ "EventTrans" SG_ 980 ESPChangeModeReqSts 0;
BA_ "GenSigSendType" SG_ 980 ESPChangeModeReqSts 3;
BA_ "EventTrans" SG_ 980 ManettinoFailSts 0;
BA_ "GenSigSendType" SG_ 980 ManettinoFailSts 3;
BA_ "EventTrans" SG_ 980 ManettinoSts 0;
BA_ "GenSigSendType" SG_ 980 ManettinoSts 3;
BA_ "EventTrans" SG_ 980 FrontWindshieldWiperSwitchSts 0;
BA_ "GenSigSendType" SG_ 980 FrontWindshieldWiperSwitchSts 3;
BA_ "EventTrans" SG_ 980 LdirectionSwitchSts 0;
BA_ "GenSigSendType" SG_ 980 LdirectionSwitchSts 3;
BA_ "EventTrans" SG_ 980 RdirectionSwitchSts 0;
BA_ "GenSigSendType" SG_ 980 RdirectionSwitchSts 3;
BA_ "EventTrans" SG_ 980 FrontWindshieldWasherSwitchSts 0;
BA_ "GenSigSendType" SG_ 980 FrontWindshieldWasherSwitchSts 3;
BA_ "EventTrans" SG_ 980 RChangeLaneSts 0;
BA_ "GenSigSendType" SG_ 980 RChangeLaneSts 3;
BA_ "EventTrans" SG_ 980 LChangeLaneSts 0;
BA_ "GenSigSendType" SG_ 980 LChangeLaneSts 3;
BA_ "EventTrans" SG_ 988 TyrePressureSystemSts 0;
BA_ "GenSigSendType" SG_ 988 TyrePressureSystemSts 3;
BA_ "EventTrans" SG_ 988 TyrePressureSystemFailSts 0;
BA_ "GenSigSendType" SG_ 988 TyrePressureSystemFailSts 3;
BA_ "EventTrans" SG_ 988 TyrePressureSysCalibrationSts 0;
BA_ "GenSigSendType" SG_ 988 TyrePressureSysCalibrationSts 3;
BA_ "EventTrans" SG_ 988 NTPTempNotActiveSts 0;
BA_ "GenSigSendType" SG_ 988 NTPTempNotActiveSts 3;
BA_ "EventTrans" SG_ 988 NTPCalibrationReqACK 0;
BA_ "GenSigSendType" SG_ 988 NTPCalibrationReqACK 3;
BA_ "Accuracy" SG_ 988 TemperatureSts_xx "Tbd";
BA_ "InitialValue" SG_ 988 TemperatureSts_xx -40;
BA_ "EventTrans" SG_ 988 TPMSTelltaleSts 0;
BA_ "GenSigSendType" SG_ 988 TPMSTelltaleSts 3;
BA_ "Accuracy" SG_ 988 LHFPressureSts "0,075 bar";
BA_ "Accuracy" SG_ 988 RHFPressureSts "0,075 bar";
BA_ "Accuracy" SG_ 988 LHRPressureSts "0,075 bar";
BA_ "Accuracy" SG_ 988 RHRPressureSts "0,075 bar";
BA_ "EventTrans" SG_ 1023 HBActivation 0;
BA_ "GenSigSendType" SG_ 1023 HBActivation 3;
BA_ "EventTrans" SG_ 1023 LBActivation 0;
BA_ "GenSigSendType" SG_ 1023 LBActivation 3;
BA_ "EventTrans" SG_ 1023 ParkingLightCmd 0;
BA_ "GenSigSendType" SG_ 1023 ParkingLightCmd 3;
BA_ "EventTrans" SG_ 1023 LeftPL 0;
BA_ "GenSigSendType" SG_ 1023 LeftPL 3;
BA_ "EventTrans" SG_ 1023 RightPL 0;
BA_ "GenSigSendType" SG_ 1023 RightPL 3;
BA_ "EventTrans" SG_ 1023 LeftDRL 0;
BA_ "GenSigSendType" SG_ 1023 LeftDRL 3;
BA_ "EventTrans" SG_ 1023 RightDRL 0;
BA_ "GenSigSendType" SG_ 1023 RightDRL 3;
BA_ "EventTrans" SG_ 1023 AHB_Memory 0;
BA_ "GenSigSendType" SG_ 1023 AHB_Memory 3;
BA_ "EventTrans" SG_ 1023 FBL_Activation 0;
BA_ "GenSigSendType" SG_ 1023 FBL_Activation 3;
BA_ "EventTrans" SG_ 1023 TrafficChangeEnable 0;
BA_ "GenSigSendType" SG_ 1023 TrafficChangeEnable 3;
BA_ "EventTrans" SG_ 1023 AFSReq 0;
BA_ "GenSigSendType" SG_ 1023 AFSReq 3;
BA_ "EventTrans" SG_ 1023 FrontWindshieldWiperSts 0;
BA_ "GenSigSendType" SG_ 1023 FrontWindshieldWiperSts 3;
BA_ "EventTrans" SG_ 1023 FrontWindshieldWasherSts 0;
BA_ "GenSigSendType" SG_ 1023 FrontWindshieldWasherSts 3;
BA_ "EventTrans" SG_ 1023 AHBFeature 0;
BA_ "GenSigSendType" SG_ 1023 AHBFeature 3;
BA_ "EventTrans" SG_ 1023 AHB_ON 0;
BA_ "GenSigSendType" SG_ 1023 AHB_ON 3;
BA_ "Accuracy" SG_ 1024 YawRate "0.08";
BA_ "GenSigStartValue" SG_ 1024 YawRate 2048;
BA_ "SignalAge" SG_ 1024 YawRate 10;
BA_ "GenSigStartValue" SG_ 1024 YRSStat 3;
BA_ "InitialValue" SG_ 1024 YRSStat 3;
BA_ "GenSigStartValue" SG_ 1035 DisplayBrightnessLevel 50;
BA_ "InitialValue" SG_ 1035 DisplayBrightnessLevel 50;
BA_ "EventTrans" SG_ 1212 RemoteFuncReq 0;
BA_ "GenSigSendType" SG_ 1212 RemoteFuncReq 3;
BA_ "EventTrans" SG_ 1212 TCU_Replacement_Warning 0;
BA_ "GenSigSendType" SG_ 1212 TCU_Replacement_Warning 3;
BA_ "InitialValue" SG_ 1214 LVB_MaxCellsTemp -45;
BA_ "GenSigStartValue" SG_ 1214 LVB_SOH 127;
BA_ "InitialValue" SG_ 1214 LVB_SOH 127;
BA_ "GenSigStartValue" SG_ 1214 LVB_Relay_Status 3;
BA_ "InitialValue" SG_ 1214 LVB_Relay_Status 3;
BA_ "GenSigStartValue" SG_ 1286 PBDisplayInfoValidData 1;
BA_ "InitialValue" SG_ 1286 PBDisplayInfoValidData 1;
BA_ "GenSigStartValue" SG_ 1286 EPBDisplayEnable 2;
BA_ "InitialValue" SG_ 1286 EPBDisplayEnable 2;
BA_ "EventTrans" SG_ 1312 NBCFISSts 0;
BA_ "GenSigSendType" SG_ 1312 NBCFISSts 3;
BA_ "EventTrans" SG_ 1312 AHBFeature 0;
BA_ "GenSigSendType" SG_ 1312 AHBFeature 3;
BA_ "EventTrans" SG_ 1313 LockUnlockDoors_Button 0;
BA_ "GenSigSendType" SG_ 1313 LockUnlockDoors_Button 3;
BA_ "SignalAge" SG_ 1313 STS_DRS_Checksum 10;
BA_ "Accuracy" SG_ 1318 BrakePressureTarget "± 5 bar";
BA_ "SignalAge" SG_ 1318 BrakePressureTarget 7;
BA_ "Accuracy" SG_ 1318 DriverBrkPressureRqt "± 5 bar";
BA_ "SignalAge" SG_ 1318 DriverBrkPressureRqt 7;
BA_ "Accuracy" SG_ 1318 BrakePressureActual "± 5 bar";
BA_ "SignalAge" SG_ 1318 BrakePressureActual 7;
BA_ "EventTrans" SG_ 1351 HALF_CHIME_TYPESts 0;
BA_ "GenSigSendType" SG_ 1351 HALF_CHIME_TYPESts 3;
BA_ "EventTrans" SG_ 1351 TSR_Fault 0;
BA_ "GenSigSendType" SG_ 1351 TSR_Fault 3;
BA_ "EventTrans" SG_ 1351 TSR_ON 0;
BA_ "GenSigSendType" SG_ 1351 TSR_ON 3;
BA_ "EventTrans" SG_ 1351 LDWSystemSts 0;
BA_ "GenSigSendType" SG_ 1351 LDWSystemSts 3;
BA_ "GenSigStartValue" SG_ 1351 LDWSystemSts 2;
BA_ "InitialValue" SG_ 1351 LDWSystemSts 2;
BA_ "GenSigStartValue" SG_ 1351 StatusLKA 3;
BA_ "InitialValue" SG_ 1351 StatusLKA 3;
BA_ "GenSigStartValue" SG_ 1351 LDWSensitivitySts 3;
BA_ "InitialValue" SG_ 1351 LDWSensitivitySts 3;
BA_ "EventTrans" SG_ 1351 HALF_RF_CHIME_RQSts 0;
BA_ "GenSigSendType" SG_ 1351 HALF_RF_CHIME_RQSts 3;
BA_ "EventTrans" SG_ 1351 HALF_LF_CHIME_RQSts 0;
BA_ "GenSigSendType" SG_ 1351 HALF_LF_CHIME_RQSts 3;
BA_ "EventTrans" SG_ 1351 HandsOnSts 0;
BA_ "GenSigSendType" SG_ 1351 HandsOnSts 3;
BA_ "GenSigStartValue" SG_ 1351 HandsOnSts 6;
BA_ "InitialValue" SG_ 1351 HandsOnSts 6;
BA_ "GenSigStartValue" SG_ 1351 DrowsinessSts 3;
BA_ "InitialValue" SG_ 1351 DrowsinessSts 3;
BA_ "GenSigStartValue" SG_ 1351 LDWWarningType_fbk 3;
BA_ "InitialValue" SG_ 1351 LDWWarningType_fbk 3;
BA_ "EventTrans" SG_ 1351 DisplaySts 0;
BA_ "GenSigSendType" SG_ 1351 DisplaySts 3;
BA_ "EventTrans" SG_ 1351 SensorBlinded 0;
BA_ "GenSigSendType" SG_ 1351 SensorBlinded 3;
BA_ "EventTrans" SG_ 1351 AHBFault 0;
BA_ "GenSigSendType" SG_ 1351 AHBFault 3;
BA_ "EventTrans" SG_ 1351 AHB_ON 0;
BA_ "GenSigSendType" SG_ 1351 AHB_ON 3;
BA_ "EventTrans" SG_ 1351 TSR_Sts 0;
BA_ "GenSigSendType" SG_ 1351 TSR_Sts 3;
BA_ "EventTrans" SG_ 1351 HALF_heaterSts 0;
BA_ "GenSigSendType" SG_ 1351 HALF_heaterSts 3;
BA_ "EventTrans" SG_ 1376 KeySts 0;
BA_ "GenSigSendType" SG_ 1376 KeySts 3;
BA_ "Accuracy" SG_ 1376 ExternalTemperature "0,5 °C (-10 °C / +20°C)";
BA_ "GenSigStartValue" SG_ 1376 ExternalTemperature 1;
BA_ "InitialValue" SG_ 1376 ExternalTemperature -39;
BA_ "SignalAge" SG_ 1376 ExternalTemperature 50;
BA_ "Accuracy" SG_ 1376 FuelLevelRawValue "±2,5 at17,5%";
BA_ "SignalAge" SG_ 1376 FuelLevelRawValue 250;
BA_ "EventTrans" SG_ 1376 NTPCalibrationReqSts 0;
BA_ "GenSigSendType" SG_ 1376 NTPCalibrationReqSts 3;
BA_ "Accuracy" SG_ 1377 EngineSpeed "± 1 rpm";
BA_ "SignalAge" SG_ 1377 EngineSpeed 35;
BA_ "GenSigStartValue" SG_ 1387 ShiftModeSts 1;
BA_ "InitialValue" SG_ 1387 ShiftModeSts 1;
BA_ "GenSigStartValue" SG_ 1387 AutomaticRoboticXmsnDegradedMode 1;
BA_ "InitialValue" SG_ 1387 AutomaticRoboticXmsnDegradedMode 1;
BA_ "SignalAge" SG_ 1398 RWSInternalSts 10;
BA_ "InitialValue" SG_ 1398 MainTemperature -40;
BA_ "InitialValue" SG_ 1398 SecondaryTemperature -40;
BA_ "Accuracy" SG_ 1409 CalculatedLoadValue "+/-0,392%";
BA_ "SignalAge" SG_ 1409 CalculatedLoadValue 100;
BA_ "Accuracy" SG_ 1409 EngineCoolantTemperature "+/-2°C";
BA_ "InitialValue" SG_ 1409 EngineCoolantTemperature -40;
BA_ "SignalAge" SG_ 1409 EngineCoolantTemperature 100;
BA_ "Accuracy" SG_ 1409 AbsoluteThrottlePosition "+/-0,392%";
BA_ "SignalAge" SG_ 1409 AbsoluteThrottlePosition 100;
BA_ "Accuracy" SG_ 1409 AbsoluteLoad "+/-0,392%";
BA_ "SignalAge" SG_ 1409 AbsoluteLoad 100;
BA_ "Accuracy" SG_ 1409 TimeSinceEngineStart "1 sec.";
BA_ "Accuracy" SG_ 1441 BatteryVoltageLevel "±0,05V";
BA_ "SignalAge" SG_ 1441 BatteryVoltageLevel 1000;
BA_ "GenSigStartValue" SG_ 1441 RechargeSts 1;
BA_ "InitialValue" SG_ 1441 RechargeSts 1;
BA_ "InitialValue" SG_ 1481 HVB_Temperature_Indicator -31;
BA_ "GenSigStartValue" SG_ 1485 LongParkingSts 1;
BA_ "InitialValue" SG_ 1485 LongParkingSts 1;

VAL_ 76 GearEngagedForADAS 0 "Not_Coded" 1 "_1th_gear" 2 "_2th_gear" 3 "_3th_gear" 4 "_4th_gear" 5 "_5th_gear" 6 "_6th_gear" 7 "_7th_gear" 8 "_8th_gear" 9 "Not_used" 10 "Not_used" 11 "Not_used" 12 "Not_used" 13 "Not_used" 14 "R" 15 "N";
VAL_ 76 NCRACCFailSts 0 "Fail_not_present" 1 "Fail_present";
VAL_ 76 ActiveGearRatioValidData 0 "Valid" 1 "Not_valid";
VAL_ 76 DriverShift 0 "Not_Active" 1 "Active";
VAL_ 76 GearEngaged 0 "'Not Coded'" 1 "'1st gear'" 2 "'2nd gear'" 3 "'3rd gear'" 4 "'4th gear'" 5 "'5th gear'" 6 "'6th gear'" 7 "'7th gear'" 8 "'8th gear'" 9 "Not_used" 10 "Not_used" 11 "Not_used" 12 "Not_used" 13 "Not_used" 14 "'R'" 15 "'N'";
VAL_ 76 FutureSyncGear 0 "'Not Coded'" 1 "'1st gear'" 2 "'2nd gear'" 3 "'3rd gear'" 4 "'4th gear'" 5 "'5th gear'" 6 "'6th gear'" 7 "'7th gear'" 8 "'8th gear'" 9 "Not_used" 10 "Not_used" 11 "Not_used" 12 "Not_used" 13 "Not_used" 14 "'R'" 15 "'N'";
VAL_ 76 ShiftInProgress 0 "No_Shift_in_progress" 1 "Shift_in_progress";
VAL_ 76 EngineSlaveMode 0 "No_slave" 1 "Slave_mode";
VAL_ 76 RaceStart 0 "Not_Active" 1 "Active";
VAL_ 175 InternalError 0 "No_internal_processing_error_det" 1 "An_internal_processing_error_det";
VAL_ 175 VoltageError 0 "No_Overvoltage_undervoltage_det" 1 "Overvoltage_undervoltage_detectd";
VAL_ 175 YRSStat 0 "Signal_in_specification_limits" 1 "Temporary_signal_error" 2 "Permanent_signal_error" 3 "Sensor_element_in_initialization";
VAL_ 175 AYSStat 0 "Signal_in_specification_limits" 1 "Temporary_signal_error" 2 "Permanent_signal_error" 3 "Sensor_element_in_initialization";
VAL_ 175 AXSStat 0 "Signal_in_specification_limits" 1 "Temporary_signal_error" 2 "Permanent_signal_error" 3 "Sensor_element_in_initialization";
VAL_ 175 LongAcceleration 4095 "Invalid_value";
VAL_ 175 LatAcceleration 4095 "Invalid_value";
VAL_ 175 YawRate 4095 "Invalid_value";
VAL_ 222 LwsAngle 65535 "Invalid";
VAL_ 222 LwsSpeed 4095 "Invalid";
VAL_ 222 LwsCalibration 0 "Not_calibrated" 1 "Calibrated";
VAL_ 222 LWSFailSts 0 "Fail_not_Present" 1 "Fail_Present_Ignition_Latched" 2 "Fail_Present_Recoverable" 3 "FailPresentBatteryDisconnection";
VAL_ 222 LwsNEWCalibration 0 "Not_Active" 1 "Active";
VAL_ 262 AssistanceTorque 4095 "Invalid";
VAL_ 262 TOIStatus 0 "TOI_Deactivated" 1 "TOI_TNA" 2 "TOI_PNA" 3 "TOI_Ready" 4 "TOI_Req_Denied" 5 "TOI_ACTIVE_AR_ENABLE" 6 "TOI_ACTIVE_AR_DISABLE" 7 "Not_Used" 8 "Not_Used" 9 "Not_Used" 10 "Not_Used" 11 "Not_Used" 12 "Not_Used" 13 "Not_Used" 14 "Not_Used" 15 "Not_Used";
VAL_ 262 SteeringColumnTorque 2047 "Invalid";
VAL_ 262 DSTTorqueOverlayIntActivated 0 "False" 1 "True";
VAL_ 262 DSTTorqueOverlayFault 0 "False" 1 "True";
VAL_ 262 EPSTemporaryDeactivation 0 "False" 1 "True";
VAL_ 262 Estimated_Rack_Force_sign 0 "Positive" 1 "Negative";
VAL_ 262 HALFTorqueOverlayIntActivated 0 "IDLE" 1 "HAS" 2 "LKA" 3 "ABSD" 4 "TJA" 5 "not_used" 6 "not_used" 7 "SNA";
VAL_ 262 HALFTorqueOverlayFault 0 "False" 1 "True";
VAL_ 262 Estimated_Rack_Force 255 "Invalid";
VAL_ 359 IgnPosSts 0 "Initialization" 1 "IGN_LK" 2 "Shutdown_req" 3 "ACC" 4 "RUN" 5 "START" 6 "Not_used" 7 "SNA";
VAL_ 359 ValidKeySts 0 "CUST_IMMOB_KEY_DEFAULT" 1 "CUST_IMMOB_KEY_VALID" 2 "Not_used" 3 "SNA";
VAL_ 359 CustKeyInIgnSts 0 "CUST_KEY_DEFAULT" 1 "CUST_KEY_NOT_IN_IGNITION" 2 "CUST_KEY_IN_IGNITION" 3 "SNA";
VAL_ 359 RFFuncReq 0 "NO_BASIC_REQUEST" 1 "UNLOCK_BUTTON_Single_Pressure" 2 "UNLOCK_BUTTON_Double_Pressure" 3 "UNLOCK_BUTTON_Long_Pressure" 4 "LOCK_BUTTON_Single_Pressure" 5 "LOCK_BUTTON_Double_Pressure" 6 "LOCK_BUTTON_Long_Pressure" 7 "TRUNK_BUTTON_Single_Pressure" 8 "TRUNK_BUTTON_Double_Pressure" 9 "TRUNK_BUTTON_long_Pressure" 10 "BUTTON_D_Single_Pressure" 11 "BUTTON_D_Double_Pressure" 12 "BUTTON_D_long_Pressure" 13 "ALL_UNLOCK_REQUEST" 14 "BUTTON_A_Single_Pressure" 15 "BUTTON_A_Double_Pressure" 16 "BUTTON_A_Long_Pressure" 17 "BUTTON_B_Single_Pressure" 18 "BUTTON_B_Double_Pressure" 19 "BUTTON_B_Long_Pressure" 20 "BUTTON_C_Single_Pressure" 21 "BUTTON_C_Double_Pressure" 22 "BUTTON_C_Long_Pressure" 23 "Left_Unlatch_Switch_Actuation" 24 "Right_Unlatch_Switch_Actuation" 25 "Left_Lock_Switch_Actuation" 26 "Right_Lock_Switch_Actuation" 27 "Ext_Trunk_Open_Switch_Actuation" 28 "Button_C_Button_D_Single_Pressure" 29 "Button_C_Button_D_Long_Pressure" 30 "Charging_Open_Switch_Actuation" 31 "SNA";
VAL_ 359 RFFobNum 0 "FOB_DEFAULT" 1 "FOB_1" 2 "FOB_2" 3 "FOB_3" 4 "FOB_4" 5 "FOB_5" 6 "FOB_6" 7 "FOB_7" 8 "FOB_8" 9 "Not_used" 10 "Not_used" 11 "Not_used" 12 "Not_used" 13 "Not_used" 14 "Not_used" 15 "Not_used";
VAL_ 359 RFRearFuncReq 0 "NO_BASIC_REQUEST" 1 "RearLeftUnlatchSwitchActuation" 2 "RearRightUnlatchSwitchActuation" 3 "RearLeftLockSwitchActuation" 4 "RearRightLockSwitchActuation" 5 "Not_used" 6 "Not_used" 7 "SNA";
VAL_ 359 FobSearchResult 0 "No_Action" 1 "No_Action_ExteriorRear" 2 "No_Action_ExteriorLeft" 3 "No_Action_ExteriorRight" 4 "No_Action_Interior" 5 "Invalid" 6 "Invalid" 7 "Invalid" 8 "Interior" 9 "Invalid" 10 "Invalid" 11 "Invalid" 12 "Invalid" 13 "Invalid" 14 "Invalid" 15 "Invalid" 16 "No_Action_Trunk" 17 "Invalid" 18 "Invalid" 19 "Invalid" 20 "Invalid" 21 "Invalid" 22 "Invalid" 23 "Invalid" 24 "Invalid" 25 "Invalid" 26 "Invalid" 27 "Invalid" 28 "Invalid" 29 "Invalid" 30 "Invalid" 31 "Invalid" 32 "Fault" 33 "Fault" 34 "Fault" 35 "Fault" 36 "Fault" 37 "Fault" 38 "Fault" 39 "Fault" 40 "Fault" 41 "Fault" 42 "Fault" 43 "Fault" 44 "Fault" 45 "Fault" 46 "Fault" 47 "Fault" 48 "Fault" 49 "Fault" 50 "Fault" 51 "Fault" 52 "Fault" 53 "Fault" 54 "Fault" 55 "Fault" 56 "Fault" 57 "Fault" 58 "Fault" 59 "Fault" 60 "Fault" 61 "Fault" 62 "Fault" 63 "Fault" 64 "In_Progress" 65 "In_Progress" 66 "In_Progress" 67 "In_Progress" 68 "In_Progress" 69 "In_Progress" 70 "In_Progress" 71 "In_Progress" 72 "In_Progress" 73 "In_Progress" 74 "In_Progress" 75 "In_Progress" 76 "In_Progress" 77 "In_Progress" 78 "In_Progress" 79 "In_Progress" 80 "In_Progress" 81 "In_Progress" 82 "In_Progress" 83 "In_Progress" 84 "In_Progress" 85 "In_Progress" 86 "In_Progress" 87 "In_Progress" 88 "In_Progress" 89 "In_Progress" 90 "In_Progress" 91 "In_Progress" 92 "In_Progress" 93 "In_Progress" 94 "In_Progress" 95 "In_Progress" 96 "In_Progress" 97 "In_Progress" 98 "In_Progress" 99 "In_Progress" 100 "In_Progress" 101 "In_Progress" 102 "In_Progress" 103 "In_Progress" 104 "In_Progress" 105 "In_Progress" 106 "In_Progress" 107 "In_Progress" 108 "In_Progress" 109 "In_Progress" 110 "In_Progress" 111 "In_Progress" 112 "In_Progress" 113 "In_Progress" 114 "In_Progress" 115 "In_Progress" 116 "In_Progress" 117 "In_Progress" 118 "In_Progress" 119 "In_Progress" 120 "In_Progress" 121 "In_Progress" 122 "In_Progress" 123 "In_Progress" 124 "In_Progress" 125 "In_Progress" 126 "In_Progress" 127 "In_Progress" 128 "Complete_Key_not_found" 129 "Complete_ExteriorRear" 130 "Complete_ExteriorLeft" 131 "Invalid" 132 "Complete_ExteriorRight" 133 "Invalid" 134 "Invalid" 135 "Invalid" 136 "Complete_Interior" 137 "Invalid" 138 "Invalid" 139 "Invalid" 140 "Invalid" 141 "Invalid" 142 "Invalid" 143 "Invalid" 144 "Complete_Trunk" 145 "Invalid" 146 "Invalid" 147 "Invalid" 148 "Invalid" 149 "Invalid" 150 "Invalid" 151 "Invalid" 152 "Complete_TrunkInterior" 153 "Invalid" 154 "Invalid" 155 "Invalid" 156 "Invalid" 157 "Invalid" 158 "Invalid" 159 "Invalid" 160 "Fault" 161 "Fault" 162 "Fault" 163 "Fault" 164 "Fault" 165 "Fault" 166 "Fault" 167 "Fault" 168 "Fault" 169 "Fault" 170 "Fault" 171 "Fault" 172 "Fault" 173 "Fault" 174 "Fault" 175 "Fault" 176 "Fault" 177 "Fault" 178 "Fault" 179 "Fault" 180 "Fault" 181 "Fault" 182 "Fault" 183 "Fault" 184 "Fault" 185 "Fault" 186 "Fault" 187 "Fault" 188 "Fault" 189 "Fault" 190 "Fault" 191 "Fault" 192 "TimeOut" 193 "TimeOut" 194 "TimeOut" 195 "TimeOut" 196 "TimeOut" 197 "TimeOut" 198 "TimeOut" 199 "TimeOut" 200 "TimeOut" 201 "TimeOut" 202 "TimeOut" 203 "TimeOut" 204 "TimeOut" 205 "TimeOut" 206 "TimeOut" 207 "TimeOut" 208 "TimeOut" 209 "TimeOut" 210 "TimeOut" 211 "TimeOut" 212 "TimeOut" 213 "TimeOut" 214 "TimeOut" 215 "TimeOut" 216 "TimeOut" 217 "TimeOut" 218 "TimeOut" 219 "TimeOut" 220 "TimeOut" 221 "TimeOut" 222 "TimeOut" 223 "TimeOut" 224 "TimeOut" 225 "TimeOut" 226 "TimeOut" 227 "TimeOut" 228 "TimeOut" 229 "TimeOut" 230 "TimeOut" 231 "TimeOut" 232 "TimeOut" 233 "TimeOut" 234 "TimeOut" 235 "TimeOut" 236 "TimeOut" 237 "TimeOut" 238 "TimeOut" 239 "TimeOut" 240 "TimeOut" 241 "TimeOut" 242 "TimeOut" 243 "TimeOut" 244 "TimeOut" 245 "TimeOut" 246 "TimeOut" 247 "TimeOut" 248 "TimeOut" 249 "TimeOut" 250 "TimeOut" 251 "TimeOut" 252 "TimeOut" 253 "TimeOut" 254 "TimeOut" 255 "TimeOut";
VAL_ 359 RFReq 0 "REQUESTOR_DEFAULT" 1 "REQUESTOR_RKE" 2 "REQUESTOR_PE" 3 "REQUESTOR_REMOTESTART" 4 "REQUESTOR_UCONNECT" 5 "REQUESTOR_WalkAway" 6 "REQUESTOR_PE_KICKBOOT" 7 "SNA";
VAL_ 359 EmergencyShutdown 0 "Not_Active" 1 "Active";
VAL_ 359 FobSearchFault 0 "NO_FAULT" 1 "FAULT";
VAL_ 359 HMIPowerOnReq 0 "Not_Active" 1 "Active";
VAL_ 359 FOBInterferenceAvoid 0 "Not_Active" 1 "Active";
VAL_ 359 DriverEnginOffRequest 0 "Not_active" 1 "Active";
VAL_ 359 FobSearchResult_LongPressure 0 "No_Action" 1 "Research_in_progress" 2 "Not_Found" 3 "Found_ExteriorRear" 4 "Found_ExteriorLeft" 5 "Found_Exterior_Right" 6 "Found_Interior" 7 "Found_Trunk";
VAL_ 359 FobSearchExteriorRear 0 "NO_FOB_IN_ZONE" 1 "FOB_IN_ZONE";
VAL_ 359 FobSearchExteriorLeft 0 "NO_FOB_IN_ZONE" 1 "FOB_IN_ZONE";
VAL_ 359 FobSearchExteriorRight 0 "NO_FOB_IN_ZONE" 1 "FOB_IN_ZONE";
VAL_ 359 FobSearchInterior 0 "NO_FOB_IN_ZONE" 1 "FOB_IN_ZONE";
VAL_ 359 FobSearchTrunk 0 "NO_FOB_IN_ZONE" 1 "FOB_IN_ZONE";
VAL_ 359 FobSearchStatus 0 "NO_ACTION" 1 "IN_PROGRESS" 2 "COMPLETE" 3 "TIMEOUT";
VAL_ 359 KeyCommandReq 0 "Unlock" 1 "Lock";
VAL_ 359 NPE_ActuationReq 0 "No_Request" 1 "Insert_Key_Request" 2 "PowerOn_Request" 3 "PowerOff_Request";
VAL_ 502 SteeringVibrationType 0 "'TYPE_0'" 1 "'TYPE_1'" 2 "'TYPE_2'" 3 "'SNA'";
VAL_ 502 TorqueOverlayIntActivation_HALF 0 "'IDLE'" 1 "'HAS'" 2 "'LKA'" 3 "'ABSD'" 4 "'TJA'" 5 "Not_used" 6 "Not_used" 7 "'SNA'";
VAL_ 502 SteeringVibrationReq 0 "'NOT_REQUESTED'" 1 "'REQUESTED'";
VAL_ 502 HALFSystemSts 0 "'NoFault'" 1 "'Fault'";
VAL_ 523 S_and_G_StandStilConfig 0 "No_S_and_G_StandstilFlag" 1 "S_and_G_StandstilFlag";
VAL_ 523 VehicleStandStillSts 0 "True" 1 "False" 2 "Not_used" 3 "SNA";
VAL_ 523 AEB_InterventionType 0 "None" 1 "ACC" 2 "AEB_P_standard" 3 "AEB_P_extended" 4 "EBA" 5 "AEB_L" 6 "'AEB_Crossing'" 7 "SNA";
VAL_ 523 ExternalBrkRequestsDisabled 0 "Enabled" 1 "Disabled" 2 "Not_used" 3 "SNA";
VAL_ 523 ACCFSafe 0 "No_Failure_Present";
VAL_ 523 CMMInterventionAck 0 "Idle" 1 "Accepted" 2 "Rejected" 3 "Not_Used";
VAL_ 523 PrefillActive 0 "Not_Active" 1 "Active";
VAL_ 523 BrakeInterventionSts 0 "No_active_brake_intervention" 1 "Active_brake_intervention";
VAL_ 523 DASMBrkForceFlag 0 "No_force" 1 "Force_Present";
VAL_ 523 HDCSts 0 "Init" 1 "Fault" 2 "Off" 3 "Ready" 4 "Active" 5 "Suspended" 6 "Not_used" 7 "Not_used";
VAL_ 524 VehicleSpeed_ASILxFailSts 0 "Fail_not_present" 1 "Fail_present";
VAL_ 524 VehicleSpeedVSOSigFailSts 0 "Fail_not_present" 1 "Fail_present";
VAL_ 524 NFR_Speed_FA_FailSts 0 "Fail_not_present" 1 "Fail_present";
VAL_ 524 NFRCruiseEnabler 0 "CC_Enabled" 1 "CC_Not_Enabled";
VAL_ 599 SBR2RowCentralSeatBuckleFailSts 0 "Fail_Not_Present" 1 "Fail_Present" 2 "Not_used" 3 "SNA";
VAL_ 599 SBR2RowCentralSeatConfigSts 0 "Seat_Not_Checked" 1 "Seat_Checked";
VAL_ 599 AirBagFailSts 0 "Fail_Not_Present_Lamp_Off" 1 "Fail_Not_Present_Lamp_Flashing" 2 "Fail_Present_Lamp_On" 3 "Not_used";
VAL_ 599 SBR1RowDriverSeatFailSts 0 "Fail_Not_Present" 1 "Fail_Present" 2 "Not_used" 3 "SNA";
VAL_ 599 SBR1RowDriverSeatConfigSts 0 "Seat_Not_Checked" 1 "Seat_Checked";
VAL_ 599 SBR2RowCentralSeatSts 0 "Seat_Belt_Fasten" 1 "Seat_Belt_Not_Fasten" 2 "Seat_Safe" 3 "Seat_Not_Safe" 4 "Not_used" 5 "Not_used" 6 "Not_used" 7 "SNA";
VAL_ 599 SBR1RowCentralSeatPPDFailSts 0 "Fail_Not_Present" 1 "Fail_Present" 2 "Not_used" 3 "SNA";
VAL_ 599 SBR1RowPsngrSeatPPDFailSts 0 "Fail_Not_Present" 1 "Fail_Present" 2 "Not_used" 3 "SNA";
VAL_ 599 SBR1RowPsngrSeatBuckleFailSts 0 "Fail_Not_Present" 1 "Fail_Present" 2 "Not_used" 3 "SNA";
VAL_ 599 SBR1RowPsngrSeatConfigSts 0 "Seat_Not_Checked" 1 "Seat_Checked";
VAL_ 599 SBR1RowDriverSeatSts 0 "Seat_Belt_Fasten" 1 "Seat_Belt_Not_Fasten" 2 "Not_used" 3 "SNA";
VAL_ 599 SBR2RowLeftSeatSts 0 "Seat_Belt_Fasten" 1 "Seat_Belt_Not_Fasten" 2 "Not_used" 3 "SNA";
VAL_ 599 SBR2RowRightSeatFailSts 0 "Fail_Not_Present" 1 "Fail_Present" 2 "Not_used" 3 "SNA";
VAL_ 599 SBR2RowLeftSeatFailSts 0 "Fail_Not_Present" 1 "Fail_Present" 2 "Not_used" 3 "SNA";
VAL_ 599 SBR1RowPsngrSeatSts 0 "Seat_Belt_Fasten" 1 "Seat_Belt_Not_Fasten" 2 "Seat_Safe" 3 "Seat_Not_Safe" 4 "Not_used" 5 "Not_used" 6 "Not_used" 7 "SNA";
VAL_ 599 CrashOutputSts 0 "No_crash" 1 "Front_Pretensioner" 2 "Front_First_Level" 4 "Front_Second_Level" 8 "Passenger_Side" 16 "Driver_Side" 32 "Rear" 64 "Rollover" 128 "Pedestrian";
VAL_ 599 SBR2RowRightSeatSts 0 "Seat_Belt_Fasten" 1 "Seat_Belt_Not_Fasten" 2 "Not_used" 3 "SNA";
VAL_ 599 CrashOutputValidData 0 "Valid" 1 "Not_Valid";
VAL_ 599 AirBagWarningPADLampOnSts 0 "PADLampON_OK" 1 "PADLampON_Fail";
VAL_ 599 AirBagWarningPADLampOffSts 0 "PADLampOFF_OK" 1 "PADLampOFF_Fail";
VAL_ 599 SBR2RowRightSeatConfigSts 0 "Seat_Not_Checked" 1 "Seat_Checked";
VAL_ 599 SBR2RowLeftSeatConfigSts 0 "Seat_Not_Checked" 1 "Seat_Checked";
VAL_ 599 Ppd_psngr_info 0 "passenger_absent" 1 "passenger_present" 2 "PPD_Fault" 3 "PPD_device_not_present";
VAL_ 599 AirBagWarningLampSts 0 "Lamp_OK" 1 "Lamp_in_Fail";
VAL_ 599 AirBagWarningPADPassengerAirbagSts 0 "PassengerAirbag_OK" 1 "PassengerAirbag_Fail";
VAL_ 625 GasPedalPositionValidData 0 "Valid" 1 "Not_valid";
VAL_ 625 StopStartParkLockReq 0 "PL_not_requested_by_NCM" 1 "PL_requested_by_NCM";
VAL_ 625 VCUCrashSts 0 "Not_Active" 1 "Active";
VAL_ 625 VCUFisSts 0 "FIS_Not_active" 1 "FIS_Active";
VAL_ 625 VCUVehicleSecureRqt 0 "NoRqt" 1 "Rqt";
VAL_ 625 PWT_StopLightActReq 0 "Init" 1 "Req" 2 "No_Req" 3 "Not_used";
VAL_ 625 PowerUnitDriverPresence 0 "Driver_Not_Present" 1 "Driver_Present";
VAL_ 625 VehWheelDriverReqTrqValidData 0 "Valid" 1 "Not_Valid";
VAL_ 625 TotalVehicleWheelTrqValidData 0 "Valid" 1 "Not_valid";
VAL_ 630 EPBMalfunction 0 "Not_active" 1 "Active";
VAL_ 630 EPBSts 0 "Released" 1 "Applied" 2 "Applying_in_progress" 3 "Releasing_in_progress" 4 "Not_used" 5 "Not_used" 6 "Not_used" 7 "Undefined_position";
VAL_ 630 CRBSts 0 "Init" 1 "Fcn_Available_Ctrl_not_Active" 2 "Failure" 3 "Not_Available" 4 "Control_Active";
VAL_ 630 AVHSts 0 "INIT_" 1 "Fnc_Available_Ctrl_not_Active" 2 "Failure" 3 "Not_Available" 4 "Control_active" 5 "not_used" 6 "not_used" 7 "not_used";
VAL_ 630 CDPSts 0 "INIT_" 1 "Fnc_Available_Ctrl_not_Active" 2 "Failure" 3 "Not_Available" 4 "Control_active" 5 "not_used" 6 "not_used" 7 "not_used";
VAL_ 630 HHCSts 0 "INIT_" 1 "Fnc_Available_Ctrl_not_Active" 2 "Failure" 3 "Not_Available" 4 "Control_active" 5 "not_used" 6 "not_used" 7 "not_used";
VAL_ 630 ABSSts 0 "INIT_" 1 "Fnc_Available_Ctrl_not_Active" 2 "Failure" 3 "Not_Available" 4 "Control_active" 5 "not_used" 6 "not_used" 7 "not_used";
VAL_ 630 EBDSts 0 "INIT_" 1 "Fnc_Available_Ctrl_not_Active" 2 "Failure" 3 "Not_Available" 4 "Control_active" 5 "not_used" 6 "not_used" 7 "not_used";
VAL_ 630 ESCOFF_Mode 0 "ESC_ON" 1 "ESC_OFF";
VAL_ 630 MSRSts 0 "Init" 1 "Fcn_Available_Ctrl_not_Active" 2 "Failure" 3 "Not_Available" 4 "Control_Active" 5 "Not_Used" 6 "Not_Used" 7 "Not_Used";
VAL_ 630 EPB_ButtonSts 0 "Switch_not_pressed" 1 "Switch_pressed" 2 "Switch_defect_and_pressed" 3 "Switch_defect_and_not_pressed";
VAL_ 630 AutoEPBEnable 0 "Disabled" 1 "Enabled" 2 "Disable_Denied" 3 "Automatic_Enabled";
VAL_ 630 VDCSts 0 "INIT_" 1 "Fnc_Available_Ctrl_not_Active" 2 "Failure" 3 "Not_Available" 4 "Control_active" 5 "not_used" 6 "not_used" 7 "not_used";
VAL_ 630 LDISts 0 "INIT_" 1 "Fnc_Available_Ctrl_not_Active" 2 "Failure" 3 "Not_Available" 4 "Control_active" 5 "not_used" 6 "not_used" 7 "not_used";
VAL_ 630 Slope 0 "less_than_minus60" 122 "more_than_60" 123 "Not_used" 124 "Not_used" 125 "Not_used" 126 "Not_used" 127 "Not_used";
VAL_ 630 TireToleranceCompensation 0 "On" 1 "Disabled";
VAL_ 630 MiniSpareDetection 0 "On" 1 "Disabled";
VAL_ 630 SlopeValidData 0 "Valid" 1 "Not_Valid";
VAL_ 653 PowerOff_AutoMode_ActualLevel 0 "Level_1" 1 "Level_2" 2 "Level_3" 3 "Not_Used" 4 "Not_Used" 5 "Not_Used" 6 "Not_Used" 7 "Not_Used";
VAL_ 653 OdomMismatchFailSts 0 "Fail_Not_Present" 1 "Fail_Present";
VAL_ 653 ReadyIndicationForDisplay 0 "Not_Active" 1 "Active";
VAL_ 653 OverboostStatus 0 "normal" 1 "overboost_active" 2 "derated" 3 "Enabled";
VAL_ 653 OverboostLevel_NQS 63 "Fail";
VAL_ 654 VCU_UserPlugUnlock_Mng 0 "Not_Active" 1 "Active_unlock_now" 2 "Active_unlock_auto" 3 "Not_used";
VAL_ 654 VCU_VehicleChargeEnable 0 "Not_enabled" 1 "Enabled";
VAL_ 654 RechargeLedRqt 0 "Off" 1 "White" 2 "Flashes_White" 3 "Green" 4 "Flashes_Green" 5 "Blue" 6 "Flashes_Blue" 7 "Red";
VAL_ 654 VCU_UserChargeEnable 0 "Not_enabled" 1 "Enabled";
VAL_ 670 ACCSystemSts 0 "OFF" 1 "Enabled" 2 "Engaged" 3 "Engaged_BrakeOnly" 4 "Override" 5 "Cancel" 6 "Not_used" 7 "Not_used";
VAL_ 670 ACC_RadarBlinded 0 "Fail_not_present" 1 "Fail_Present";
VAL_ 670 RadarBlinded 0 "Fail_not_present" 1 "Fail_Present";
VAL_ 670 ACCFailReversibleSts 0 "No_ACC_Fail" 1 "ACC_Reversible_Fail" 2 "ACC_Irreversible_Fail" 3 "Not_used";
VAL_ 670 DASMTemporaryFailSts 0 "Fail_not_present" 1 "Fail_Present";
VAL_ 670 DASMFailSts 0 "Fail_not_present" 1 "Fail_Present";
VAL_ 670 ACCFailSts 0 "Fail_not_present" 1 "Fail_Present";
VAL_ 761 GearLeverPositionforNPE 0 "P" 1 "N" 2 "R" 3 "D" 4 "Not_used" 5 "Unknown" 6 "Transition" 7 "Not_used";
VAL_ 761 ShiftType 0 "NO_SHIFT" 1 "DOWNSHIFT" 2 "UPSHIFT" 3 "HOLD_UPSHIFT" 4 "UPSHIFT_AFTER_HOLD";
VAL_ 761 GearLeverFailForNPE 0 "No_Fail" 1 "Fail";
VAL_ 778 LifterFailSts 0 "Fail_not_present" 1 "Minor_Error" 2 "Critical_Error" 3 "Not_used";
VAL_ 778 LifterSts 0 "Down" 1 "Moving_Up" 2 "Moving_Down" 3 "Up" 4 "Inhibited" 5 "Not_used" 6 "Not_used" 7 "Unknown";
VAL_ 778 LifterBuzzerReq 0 "No_acoustic_signal" 1 "Lifter_inhibited" 2 "End_of_raising_sequence" 3 "Lifter_Suppressed" 4 "Waiting_at_Key_ON" 5 "Waiting_at_Key_OFF" 6 "Limited_UP" 7 "Vehicle_lifter_failure";
VAL_ 778 LifterInfoForDisplay 0 "None" 1 "Moving_Up" 2 "Moving_Down_Sys_Disabled" 3 "Up" 4 "Down_Sys_Disabled" 5 "Inhibited" 6 "Failure" 7 "Waiting_at_Key_OFF" 8 "Waiting_at_Key_ON" 9 "Down_Sys_Enabled" 10 "Moving_Down_Sys_Enabled" 11 "Limited_UP" 12 "Not_used" 13 "Not_used" 14 "Not_used" 15 "Not_used" 16 "Not_used" 17 "Not_used" 18 "Not_used" 19 "Not_used" 20 "Not_used" 21 "Not_used" 22 "Not_used" 23 "Not_used" 24 "Not_used" 25 "Not_used" 26 "Not_used" 27 "Not_used" 28 "Not_used" 29 "Not_used" 30 "Not_used" 31 "Not_used";
VAL_ 778 LifterAutonomy 63 "Full_Autonomy";
VAL_ 778 LifterType 0 "ASC" 1 "Hydraulic";
VAL_ 778 LifterAutoStopStaySts 0 "RecrankEngine" 1 "RemainStop";
VAL_ 778 LifterAutoStopFailSts 0 "Fail_Not_Present" 1 "Fail_Present";
VAL_ 778 LifterAutoStopEnableSts 0 "Disable" 1 "Enable";
VAL_ 865 EngineSpeedValidData 0 "Valid" 1 "Not_valid";
VAL_ 865 CylCutEnabled 0 "Cyl_Cut_not_enabled_for_DCT" 1 "Cyl_Cut_enabled_for_DCT";
VAL_ 865 VehDriverReqTrqValidData 0 "Valid" 1 "Not_valid";
VAL_ 980 CruiseControlCmdResumeSts 0 "Not_Active" 1 "Active";
VAL_ 980 CruiseControlCmdChangeSts 0 "Not_Active" 1 "Active";
VAL_ 980 CruiseControlCmdDecelerationSts 0 "Not_Pressed" 1 "Pressed";
VAL_ 980 CruiseControlCmdAccelerationSts 0 "Not_Pressed" 1 "Pressed";
VAL_ 980 EManettinoDriverWish 0 "Pos_0" 1 "Pos_1" 2 "Pos_2" 3 "Pos_3" 4 "Pos_4" 5 "Pos_5" 6 "Pos_6" 7 "Pos_7" 8 "Pos_8" 9 "Pos_9" 10 "Pos_10" 11 "Pos_11" 12 "Pos_12" 13 "Not_Used" 14 "Not_Used" 15 "SNA";
VAL_ 980 CruiseControlFailSts 0 "Fail_not_present" 1 "Fail_Present";
VAL_ 980 ACC_OnOffSts 0 "Not_active" 1 "Active";
VAL_ 980 SpeedRockerSts 0 "Increase_10" 1 "Increase_01" 2 "No_Req" 3 "Decrease_01" 4 "Decrease_10" 5 "Not_used" 6 "Not_used" 7 "Not_used";
VAL_ 980 ACC_DistSts 0 "Not_active" 1 "Active";
VAL_ 980 ResumeSwitch 0 "Not_active" 1 "Active";
VAL_ 980 ManettinoSuspensionSts 0 "Follow_Manettino_Sts" 1 "Position_1" 2 "Position_2" 3 "Position_3" 4 "Not_used" 5 "Not_used" 6 "Not_used" 7 "Not_used";
VAL_ 980 ESPChangeModeReqSts 0 "Not_active" 1 "Active";
VAL_ 980 ManettinoFailSts 0 "Fail_Not_Present" 1 "Fail_Present";
VAL_ 980 ManettinoSts 0 "Position_0" 1 "Position_1" 2 "Position_2" 3 "Position_3" 4 "Position_4" 5 "Not_used" 6 "Not_used" 7 "Not_used";
VAL_ 980 FrontWindshieldWiperSwitchSts 0 "No_command" 1 "Antipanic" 2 "First_Speed" 3 "Second_Speed" 4 "Auto1" 5 "Auto2" 6 "Not_used" 7 "Not_used";
VAL_ 980 SuspensionButtonSts 0 "Not_Pressed" 1 "Pressed";
VAL_ 980 LdirectionSwitchSts 0 "Not_Active" 1 "Active";
VAL_ 980 RdirectionSwitchSts 0 "Not_Active" 1 "Active";
VAL_ 980 LTICmdFailSts 0 "Fail_Not_Present" 1 "Fail_Present";
VAL_ 980 SuspensionButtonValidData 0 "Valid" 1 "Not_Valid";
VAL_ 980 EManettinoDriverWishDirection 0 "No_Rqt" 1 "Clockwise" 2 "Counter_Clockwise" 3 "Not_Used";
VAL_ 980 HDCButtonSts 0 "Not_Pressed" 1 "Pressed";
VAL_ 980 WiperCmdFailSts 0 "Fail_not_present" 1 "Fail_present";
VAL_ 980 FrontWindshieldWasherSwitchSts 0 "Not_Active" 1 "Active";
VAL_ 980 ConfirmationCommand 0 "Not_Pressed" 1 "Pressed" 2 "Not_Used" 3 "Reserved for Touch";
VAL_ 980 ContentsCommand 0 "Not_Pressed" 1 "Pressed UP" 2 "Pressed Down" 3 "Reserved for Touch";
VAL_ 980 RChangeLaneSts 0 "Not_Active" 1 "Active";
VAL_ 980 LChangeLaneSts 0 "Not_Active" 1 "Active";
VAL_ 980 RTICmdFailSts 0 "Fail_Not_Present" 1 "Fail_Present";
VAL_ 988 TyrePressureSystemSts 0 "On" 1 "Disabled";
VAL_ 988 TyrePressureSystemFailSts 0 "Fail_Not_Present" 1 "Fail_Present";
VAL_ 988 TyrePressureSysCalibrationSts 0 "SystemCalibrated" 1 "SystemNotCalibrated";
VAL_ 988 NTPTempNotActiveSts 0 "Active" 1 "TemporarilyNotActive";
VAL_ 988 NTPCalibrationReqACK 0 "No_calibration_request" 1 "Calibration_Request_Acknowledged";
VAL_ 988 IDtyre_temperature 0 "LF" 1 "RF" 2 "LR" 3 "RR";
VAL_ 988 TemperatureSts_xx 254 "ValueNotAvailable" 255 "FaultValue";
VAL_ 988 UnknownTyrePressureSts 0 "Fail_Not_Present" 1 "Low_Pressure_Soft_warning" 2 "Flat_Tyre_Hard_warning" 3 "High_Temperature";
VAL_ 988 TPMSTelltaleSts 0 "OFF" 1 "Blink_Malfunctioning" 2 "ON_Puncture_Malfunctioning" 3 "Not_used";
VAL_ 988 RHRTyrePressureSts 0 "Fail_Not_Present" 1 "Low_Pressure_Soft_warning" 2 "Flat_Tyre_Hard_warning" 3 "High_Temperature";
VAL_ 988 LHRTyrePressureSts 0 "Fail_Not_Present" 1 "Low_Pressure_Soft_warning" 2 "Flat_Tyre_Hard_warning" 3 "High_Temperature";
VAL_ 988 RHFTyrePressureSts 0 "Fail_Not_Present" 1 "Low_Pressure_Soft_warning" 2 "Flat_Tyre_Hard_warning" 3 "High_Temperature";
VAL_ 988 LHFTyrePressureSts 0 "Fail_Not_Present" 1 "Low_Pressure_Soft_warning" 2 "Flat_Tyre_Hard_warning" 3 "High_Temperature";
VAL_ 988 LHFPressureSts 254 "ValueNotAvailable" 255 "FaultValue";
VAL_ 988 RHFPressureSts 254 "ValueNotAvailable" 255 "FaultValue";
VAL_ 988 LHRPressureSts 254 "ValueNotAvailable" 255 "FaultValue";
VAL_ 988 RHRPressureSts 254 "ValueNotAvailable" 255 "FaultValue";
VAL_ 1023 HBActivation 0 "OFF" 1 "ON" 2 "FLASH" 3 "Not_used";
VAL_ 1023 LBActivation 0 "OFF" 1 "ON";
VAL_ 1023 ParkingLightCmd 0 "Not_Active" 1 "Active";
VAL_ 1023 LeftPL 0 "OFF" 1 "ON";
VAL_ 1023 RightPL 0 "OFF" 1 "ON";
VAL_ 1023 LeftDRL 0 "OFF" 1 "ON";
VAL_ 1023 RightDRL 0 "OFF" 1 "ON";
VAL_ 1023 AHB_Memory 0 "FALSE" 1 "TRUE";
VAL_ 1023 FBL_Activation 0 "OFF" 1 "ON";
VAL_ 1023 TrafficChangeEnable 0 "INIT" 1 "active" 2 "Not_Active" 3 "Not_used";
VAL_ 1023 AFSReq 0 "OFF" 1 "ON";
VAL_ 1023 FrontWindshieldWiperSts 0 "Not_Active" 1 "Active";
VAL_ 1023 FrontWindshieldWasherSts 0 "Not_Active" 1 "Active";
VAL_ 1023 AHBFeature 0 "OFF" 1 "ON";
VAL_ 1023 AHB_ON 0 "OFF" 1 "ON";
VAL_ 1024 YawRate 4095 "Invalid_value";
VAL_ 1024 YRSStat 0 "Signal_in_specification_limits" 1 "Temporary_signal_error" 2 "Permanent_signal_error" 3 "Sensor_element_in_initialization";
VAL_ 1035 CeremonySts_IDC 0 "Not_Active" 1 "Active" 2 "Completed" 3 "Not_Used";
VAL_ 1035 ETA_to_Dest 2047 "SNA";
VAL_ 1035 Ecall_IDCMuteReq 0 "Not_Active" 1 "Active";
VAL_ 1035 ETA_to_EVSE 2047 "SNA";
VAL_ 1035 HMISts 0 "HMI_OFF" 1 "HMI_ON" 2 "HMI_PowerOn";
VAL_ 1035 CabinModeSts 0 "Not_Enabled" 1 "Enabled";
VAL_ 1035 IDC_CommandSts 0 "No_Action" 1 "PowerOn_Action" 2 "PowerOff_Action" 3 "not_used";
VAL_ 1035 IDC_VisualizationSts 0 "No_Visualization" 1 "Insert_Key" 2 "Key_Not_Found" 3 "not_used";
VAL_ 1109 P4L_speed_v2 32767 "SNA";
VAL_ 1109 P4R_speed_v2 32767 "SNA";
VAL_ 1109 P4RL_Speed 32767 "SNA";
VAL_ 1109 P4RR_Speed 32767 "SNA";
VAL_ 1212 RemoteFuncReq 0 "NO_BASIC_REQUEST" 1 "Lock_Command" 2 "Unlock_Command" 3 "not_used" 4 "not_used" 5 "not_used" 6 "not_used" 7 "not_used" 8 "not_used" 9 "not_used" 10 "not_used" 11 "not_used" 12 "not_used" 13 "not_used" 14 "not_used" 15 "not_used";
VAL_ 1212 TCU_Replacement_Warning 0 "Not_Active" 1 "Active";
VAL_ 1214 LVB_SOCSts 0 "OK" 1 "FLT";
VAL_ 1214 LVB_SOC 127 "SNA";
VAL_ 1214 LVB_MaxCellsTemp 255 "SNA";
VAL_ 1214 LVB_SOH 127 "SNA";
VAL_ 1214 LVB_MaxCellsTempFailsts 0 "Fail_not_Present" 1 "Fail_Present";
VAL_ 1214 RecirculationReq 0 "No_Req" 1 "Req";
VAL_ 1214 LVB_Relay_Status 0 "CLS" 1 "OPN_REQ" 2 "OPN" 3 "SNA";
VAL_ 1261 DMS_Attentiveness 0 "Status_not_available" 1 "Driver_inattentive" 2 "Driver_attentive" 3 "Not_used";
VAL_ 1261 DMSSystemFail 0 "not_fail" 1 "temp_fail" 2 "perma_fail" 3 "degraded";
VAL_ 1261 DMSSystemStatus 0 "Init" 1 "Off" 2 "On" 3 "Error" 4 "Calib_state" 5 "Not_used" 6 "Not_used" 7 "Not_used";
VAL_ 1261 HMICode_DMS 0 "not_active" 1 "visual" 2 "visual_acoustic" 3 "Degraded";
VAL_ 1261 CabinDivision 0 "Status_not_available" 1 "area1" 2 "area2" 3 "area3";
VAL_ 1261 NIR_Blocking_GlassesDetection 0 "Status_not_available" 1 "No_glasses_detection" 2 "glasses_detection" 3 "Not_used";
VAL_ 1261 DMS_DriverPresent 0 "Status_not_available" 1 "No_driver_present" 2 "Driver_present" 3 "Not_used";
VAL_ 1261 Nominal_condition 0 "Status_not_available" 1 "Nominal_condition" 2 "No_nominal_condition" 3 "Not_used";
VAL_ 1267 PWT_Limited_Perfo 0 "Normal" 1 "Degraded";
VAL_ 1267 RechargeSts_HVB 0 "Not_Active" 1 "Normal" 2 "Degraded" 3 "Critical";
VAL_ 1267 PWTBuzzerReq 0 "Not_Active" 1 "Active";
VAL_ 1267 HMICode_CC 0 "CC_UNAVAILABLE_BRAKE_APPLIED" 1 "CC_UNAVAILABLE" 2 "CC_UNAVAILABLE_BELT" 3 "CC_UNAVAILABLE_ABOVE_MAX_SPEED" 4 "CC_UNAVAILABLE_EPB_ACTIVE" 5 "CC_UNAVAILABLE_ESC_EVENT" 6 "CC_UNAVAILABLE_DRIVE_MODE" 7 "CC_UNAVAILABLE_BACKWARD" 8 "CC_UNAVAILABLE_SHIFT_D" 9 "CC_UNAVAILABLE_ROAD_TOO_STEEP" 10 "CC_CANCEL_SHIFT_D" 11 "CC_CANCEL_BACKWARD" 12 "CC_CANCEL_ESC_EVENT" 13 "CC_CANCEL_HIGH_RPM" 14 "CC_CANCEL_CHIME" 15 "CC_CANCEL_EPB_ACTIVE" 16 "CC_CANCEL_BELT" 17 "CC_CANC_ROAD_TOO_STEEP" 18 "CC_OVERRIDE" 19 "CC_UNAVAILABLE_DOOR_OPEN" 20 "CC_CANC_DOOR_OPEN" 21 "CC_MAX_SPEED_EDRIVE_BELOW" 22 "CC_MAX_SPEED_EDRIVE_ABOVE" 23 "CC_MAX_SPEED_ECO_BELOW" 24 "CC_MAX_SPEED_ECO_ABOVE" 25 "CC_MAX_SPEED_STD_BELOW" 26 "CC_MAX_SPEED_STD_ABOVE" 27 "CC_MAX_SPEED_PERF_BELOW" 28 "CC_MAX_SPEED_PERF_ABOVE" 29 "NO_CODE" 30 "Not_used" 31 "Not_used";
VAL_ 1267 Recharge_PlugSts 0 "Not_Connected" 1 "Connected_unlocked" 2 "Connected_locked" 3 "Not_used";
VAL_ 1267 VehicleStartNotAllowed 0 "Not_Active" 1 "Active";
VAL_ 1267 START_ButtonPress_Rqt 0 "No_Visualization" 1 "Pressure" 2 "Pressure_and_hold" 3 "Not_used";
VAL_ 1267 CCSpeedWarning 0 "No_Warning" 1 "CCSpeedReducedByEDrive" 2 "MaxCCSpeedReachedForEDrive" 3 "CCNotAvailable";
VAL_ 1267 PlugInRechargeWarning 0 "Not_Active" 1 "PlugInRecharge_NotAvailable_CheckEPB" 2 "PlugInRecharge_NotAvailable_InsertP" 3 "PlugInRecharge_NotAvailable" 4 "PlugInRecharge_NotCompleteable" 5 "not_used" 6 "not_used" 7 "not_used" 8 "not_used" 9 "not_used" 10 "not_used" 11 "not_used" 12 "not_used" 13 "not_used" 14 "not_used" 15 "not_used" 16 "not_used" 17 "not_used" 18 "not_used" 19 "not_used" 20 "not_used" 21 "not_used" 22 "not_used" 23 "not_used" 24 "not_used" 25 "not_used" 26 "not_used" 27 "not_used" 28 "not_used" 29 "not_used" 30 "not_used" 31 "not_used";
VAL_ 1267 LVSysWarningForDisplay 0 "No_Failure" 1 "LVB_Thermal_Runaway" 2 "LVB_Temperature_Critical" 3 "LV_Failure_Critical" 4 "LVB_Recharge_Not_Available" 5 "LVB_Electrical_Fault_Critical" 6 "LVB_HW_Fault_Critical" 7 "Communication_Fault_Critical" 8 "LVB_Temperature_Warning" 9 "LVB_Electrical_Fault_Warning" 10 "LVB_HW_Fault_Warning" 11 "Communication_Fault_Warning" 12 "LVB_SOH_warning" 13 "LVB_SW_Fault" 14 "LV_Failure_Warning" 15 "LV_Secondary_Relè_Stuck_Closed" 16 "LV_Consumption_too_high" 17 "not_used" 18 "not_used" 19 "not_used" 20 "not_used" 21 "not_used" 22 "not_used" 23 "not_used" 24 "not_used" 25 "not_used" 26 "not_used" 27 "not_used" 28 "not_used" 29 "not_used" 30 "not_used" 31 "not_used";
VAL_ 1267 PWTSystemWarningForDisplay 0 "No_Failure" 1 "AWD_EM_Not_Available" 2 "RWD_EM_Not_Available" 3 "not_used" 4 "not_used" 5 "AWD_Not_Available_OneFront" 6 "AWD_Not_Available_OneRear" 7 "FirstStart_OneRear" 8 "FrontAxle_ForcedAWD" 9 "FrontAxle_ForcedRWD" 10 "FrontAxleUnknown_ForcedRWD" 11 "Traction_System_Not_Available" 12 "RegenerativeBraking_Fail" 13 "P4_SafeStateFault" 14 "not_used" 15 "not_used" 16 "not_used" 17 "not_used" 18 "not_used" 19 "not_used" 20 "not_used" 21 "not_used" 22 "not_used" 23 "not_used" 24 "not_used" 25 "not_used" 26 "not_used" 27 "not_used" 28 "not_used" 29 "not_used" 30 "not_used" 31 "not_used";
VAL_ 1267 PWTLimpHomeSts 0 "No_Warning" 1 "LimitedPerformance" 2 "PWT_Starting" 3 "PWT_Warming" 4 "Not_Used" 5 "Not_Used" 6 "Not_Used" 7 "Not_Used" 8 "Not_Used" 9 "Not_Used" 10 "Not_Used" 11 "Not_Used" 12 "Not_Used" 13 "Not_Used" 14 "Not_Used" 15 "Not_Used" 16 "Not_Used" 17 "Not_Used" 18 "Not_Used" 19 "Not_Used" 20 "Not_Used" 21 "Not_Used" 22 "Not_Used" 23 "Not_Used" 24 "Not_Used" 25 "Not_Used" 26 "Not_Used" 27 "Not_Used" 28 "Not_Used" 29 "Not_Used" 30 "Not_Used" 31 "Not_Used";
VAL_ 1267 PropulsionSystemFailure 0 "Fail_Not_Present" 1 "Fail_Present";
VAL_ 1267 MVSysWarningForDisplay 0 "No_Warning" 1 "MV_Failure_Critical" 2 "MV_Failure_Warning" 3 "Not_used" 4 "Not_used" 5 "Not_used" 6 "Not_used" 7 "Not_used" 8 "Not_used" 9 "Not_used" 10 "Not_used" 11 "Not_used" 12 "Not_used" 13 "Not_used" 14 "Not_used" 15 "Not_used";
VAL_ 1267 PWTFailSts 0 "Fail_Not_Present" 1 "Fail_Present";
VAL_ 1267 MVFailSts 0 "Fail_Not_Present" 1 "Fail_Present";
VAL_ 1274 rub_Current_WAL_Status 0 "'ST_Inactive'" 1 "'ST_Polling_Interior'" 2 "'ST_Polling_In_Trunk'" 3 "'ST_Polling_Ext_Driver'" 4 "'ST_Polling_Ext_Passenger'" 5 "'ST_Polling_Ext_Trunk'" 6 "Not_used" 7 "Not_used";
VAL_ 1274 rub_WAL_Current_Activation 0 "'No_Trig'" 1 "'Driver_Door_Closing'" 2 "'Driver_Door_Opening'" 3 "'Passenger_Door_Closing'" 4 "'Passenger_Door_Opening'" 5 "'RearLeft_Door_Closing'" 6 "'RearLeft_Door_Opening'" 7 "'RearRight_Door_Closing'" 8 "'RearRight_Door_Opening'" 9 "'Trunk_Door_Closing'" 10 "'Trunk_Door_Opening'" 11 "'Unsecure_PE_Door_Opening'" 12 "'Exit_Driving_With_Door_Opened'" 13 "Not_used" 14 "Not_used" 15 "Not_used";
VAL_ 1274 WAL_Trig_EV 0 "'No_Trig'" 1 "'Driver_Door_Closing'" 2 "'Driver_Door_Opening'" 3 "'Passenger_Door_Closing'" 4 "'Passenger_Door_Opening'" 5 "'RearLeft_Door_Closing'" 6 "'RearLeft_Door_Opening'" 7 "'RearRight_Door_Closing'" 8 "'RearRight_Door_Opening'" 9 "'Trunk_Door_Closing'" 10 "'Trunk_Door_Opening'" 11 "'Unsecured_PE_Door_Opening'" 12 "'Exit_Driving_With_Door_Opened'" 13 "Not_used" 14 "Not_used" 15 "Not_used";
VAL_ 1274 X_SET_WAL_Area_To_Search_m 0 "None" 1 "Interior" 2 "In_Trunk" 3 "Ext_Driver" 4 "Ext_Passenger" 5 "Ext_Trunk" 6 "Not_used" 7 "Not_used";
VAL_ 1274 is_WAL_Search 0 "'IN_NO_ACTIVE_CHILD_m'" 1 "'IN_WAL_Polling_Ext_Driver'" 2 "'IN_WAL_Polling_Ext_Passenger'" 3 "'IN_WAL_Polling_Ext_Trunk'" 4 "'IN_WAL_Polling_Interior'" 5 "'IN_WAL_Polling_Trunk'" 6 "Not_used" 7 "Not_used";
VAL_ 1274 rub_WAL_Current_Exit 0 "'RKE_Inhibit'" 1 "'Id_Inside_All_Doors_Closed_Inh'" 2 "'Path_Not_Ok'" 3 "'No_ID_After_Trig'" 4 "'Vehicle_State_Inhibit'" 5 "'Car_Secured'" 6 "'Detection_TimeOut'" 7 "'LF_Error'" 8 "'Key_Event'" 9 "'Crash_Event'" 10 "'By_Reset'" 11 "'By_WAL'" 12 "'No_One'" 13 "Not_used" 14 "Not_used" 15 "Not_used";
VAL_ 1276 KeyFob_Button 0 "'CID_NO_BUTTON_PRESSED'" 1 "'CID_BUTTON_5_PRESSED'" 2 "'CID_BUTTON_2_PRESSED'" 4 "'CID_BUTTON_3_PRESSED'" 8 "'CID_BUTTON_1_PRESSED'" 64 "'CID_BUTTON_4_PRESSED'";
VAL_ 1286 AVHDisplayInfo 0 "No_Request_to_HMI" 1 "Not_used" 2 "Under_Intervention" 3 "Fail_Lamp_ON";
VAL_ 1286 HHCDisplayInfo 0 "No_Request_to_HMI" 1 "Fail_Lamp_ON";
VAL_ 1286 EBDDisplayInfo 0 "No_Request_to_HMI" 1 "Fail_Lamp_ON";
VAL_ 1286 ABSDisplayInfo 0 "No_Request_to_HMI" 1 "Fail_Lamp_ON";
VAL_ 1286 ESCOFFLampRequest 0 "No_Request_to_HMI" 1 "Fail_Lamp_ON";
VAL_ 1286 BrakeFluidLevelSts 0 "OK" 1 "Low_Level";
VAL_ 1286 NFRSts 0 "Init_" 1 "Normal_Operation" 2 "Degraded_" 3 "Error" 4 "RollBenchMode_Active" 5 "Not_used" 6 "BrakeBenchMode_Active" 7 "Not_used" 8 "DiagnosticSessionActive_on_NFR" 9 "Not_used" 10 "Not_available" 11 "Not_used" 12 "Not_used" 13 "Not_used" 14 "Not_used" 15 "Not_used";
VAL_ 1286 EPBRemovePLRqtInfo 0 "Off" 1 "On";
VAL_ 1286 ThirdLightFaultSts 0 "No_Fault" 1 "Fault_Present";
VAL_ 1286 EPB_BrakePedalPressIndicationReq 0 "OFF" 1 "ON";
VAL_ 1286 EPB_BuzzerReq 0 "OFF" 1 "ON";
VAL_ 1286 LDIDisplayInfo 0 "No_Request_to_HMI" 1 "Enable" 2 "Under_Intervention" 3 "Fail_Lamp_On" 4 "Fail_Temp_Not_Available" 5 "Not_used" 6 "Not_used" 7 "Not_used";
VAL_ 1286 PBDisplayInfoValidData 0 "Valid" 1 "Not_valid";
VAL_ 1286 VDCDisplayInfo 0 "No_Request_to_HMI" 1 "Not_used" 2 "Under_Intervention" 3 "Fail_Lamp_ON";
VAL_ 1286 ServiceLampBlinkFreq 0 "No_blinking" 1 "Slow_Blinking_1_Hz" 3 "Fast_blinking_3_Hz" 7 "Signal_invalid";
VAL_ 1286 PBDisplayInfo 0 "Not_used" 1 "See_note" 2 "See_note" 3 "See_note" 4 "See_note" 5 "See_note" 6 "See_note" 7 "See_note" 8 "See_note" 9 "See_note" 10 "See_note" 11 "See_note" 12 "See_note" 13 "See_note" 14 "See_note" 15 "See_note" 16 "See_note" 17 "See_note" 18 "See_note" 19 "See_note" 20 "See_note" 21 "See_note" 22 "See_note" 23 "See_note" 24 "See_note" 25 "See_note" 26 "See_note" 27 "Not_used" 28 "Not_used" 29 "Not_used" 30 "Not_used" 31 "Not_used";
VAL_ 1286 FadeWarning 0 "Level_0_No_Fade" 1 "Level_1_Soft" 2 "Level_2_Critical" 3 "not_used";
VAL_ 1286 EPBDisplayEnable 0 "not_used" 1 "Enabled" 2 "Disabled" 3 "not_used";
VAL_ 1286 WarningLampReq 0 "OFF" 1 "ON" 2 "Not_used" 3 "Signal_invalid";
VAL_ 1286 ServiceLampReq 0 "OFF" 1 "ON" 2 "Not_used" 3 "Signal_invalid";
VAL_ 1286 ESCOFF_Inhibition_Info 0 "Not_Inhibited" 1 "Inhibited";
VAL_ 1286 CRBInfoForDisplay 0 "No_req_to_HMI" 1 "Not_used" 2 "Under_Intervention" 3 "Fail";
VAL_ 1286 MSRInfoForDisplay 0 "No_req_to_HMI" 1 "Not_used" 2 "Under_Intervention" 3 "Fail";
VAL_ 1286 EPBLifeCycleWarning 0 "OFF" 1 "ON";
VAL_ 1286 HDC_Pop_Up 0 "No_Visualization" 1 "HDC_Not_Available" 2 "HDC_ACC_Engaged" 3 "not_used" 4 "not_used" 5 "not_used" 6 "not_used" 7 "not_used";
VAL_ 1312 TurnIndicatorSts 0 "Center" 1 "Left" 2 "Right" 3 "SNA";
VAL_ 1312 KeySts 0 "Data_not_valid" 1 "STOP" 2 "PARK" 3 "Not_used" 4 "ON" 5 "Not_used" 6 "Not_used" 7 "Not_used" 8 "Not_used" 9 "Not_used" 10 "Not_used" 11 "Not_used" 12 "CRANK_ON" 13 "Not_used" 14 "Not_used" 15 "Not_used";
VAL_ 1312 TrailerConnected 0 "Not_Connected" 1 "Connected";
VAL_ 1312 LHRTurnLightFailSts 0 "Fail_Not_Present" 1 "Fail_Present";
VAL_ 1312 LHRParkTailLightFailSts 0 "Fail_Not_Present" 1 "Fail_Present";
VAL_ 1312 HazardLightSts 0 "OFF" 1 "ON";
VAL_ 1312 LHFTurnLightFailSts 0 "Fail_Not_Present" 1 "Fail_Present";
VAL_ 1312 NBCFISSts 0 "Not_active" 1 "Active";
VAL_ 1312 StopLightFault 0 "False" 1 "True";
VAL_ 1312 AHBFeature 0 "OFF" 1 "ON";
VAL_ 1312 RHTurnSignalSts 0 "OFF" 1 "ON";
VAL_ 1312 RHStopLightFailSts 0 "Fail_Not_Present" 1 "Fail_Present";
VAL_ 1312 RHRTurnLightFailSts 0 "Fail_Not_Present" 1 "Fail_Present";
VAL_ 1312 RHRParkTailLightFailSts 0 "Fail_Not_Present" 1 "Fail_Present";
VAL_ 1312 TrailerConnectedFailSts 0 "Fail_Not_Present" 1 "Fail_Present";
VAL_ 1312 RHFTurnLightFailSts 0 "Fail_Not_Present" 1 "Fail_Present";
VAL_ 1312 LHTurnSignalSts 0 "OFF" 1 "ON";
VAL_ 1312 LHStopLightFailSts 0 "Fail_Not_Present" 1 "Fail_Present";
VAL_ 1312 LBCmdNightInfoForDisplay 0 "Not_Active" 1 "Active";
VAL_ 1312 NSVSts 0 "Down" 1 "Up" 2 "Moving" 3 "Not_Available";
VAL_ 1312 LHParkTailLightSts 0 "OFF" 1 "ON";
VAL_ 1312 RHParkTailLightSts 0 "OFF" 1 "ON";
VAL_ 1312 RLSWiperSpeed 0 "Off" 1 "Low_Speed" 2 "High_Speed" 3 "Not_used" 4 "Not_used" 5 "Not_used" 6 "RLS_Error" 7 "SNA";
VAL_ 1312 FrontWiperModeSts 0 "Stop" 1 "Moving";
VAL_ 1313 STS_DRS_DriverLatchsts 0 "init" 1 "Unlocked" 2 "Locked" 3 "SNA";
VAL_ 1313 STS_DRS_PsngrDoorSts 0 "SNA" 1 "close" 2 "Ajar" 3 "Open";
VAL_ 1313 STS_DRS_DriverDoorSts 0 "SNA" 1 "close" 2 "Ajar" 3 "Open";
VAL_ 1313 STS_DRS_VPSTrunkSts 0 "Closed_Unlocked" 1 "Closed_Locked" 2 "Open_Unlocked" 3 "Open_Locked";
VAL_ 1313 STS_DRS_RearRightLatchsts 0 "init" 1 "Unlocked" 2 "Locked" 3 "SNA";
VAL_ 1313 STS_DRS_RearLeftDoorSts 0 "SNA" 1 "close" 2 "Ajar" 3 "Open";
VAL_ 1313 STS_DRS_RearRightDoorSts 0 "SNA" 1 "close" 2 "Ajar" 3 "Open";
VAL_ 1313 STS_DRS_PsngrLatchsts 0 "init" 1 "Unlocked" 2 "Locked" 3 "SNA";
VAL_ 1313 STS_DRS_PsngrWindowSts 0 "Open" 1 "Close" 2 "Middle" 3 "Running_Up" 4 "Running_Down" 5 "Reverse" 6 "Short_drop" 7 "SNA";
VAL_ 1313 STS_DRS_DriverWindowSts 0 "Open" 1 "Close" 2 "Middle" 3 "Running_Up" 4 "Running_Down" 5 "Reverse" 6 "Short_drop" 7 "SNA";
VAL_ 1313 STS_DRS_VPSLockValidData 0 "Valid" 1 "Not_Valid";
VAL_ 1313 STS_DRS_RearLeftLatchsts 0 "init" 1 "Unlocked" 2 "Locked" 3 "SNA";
VAL_ 1313 TrunkInternalButton 0 "Not_Active" 1 "Active";
VAL_ 1313 STS_DRS_RearRightWindowSts 0 "Open" 1 "Close" 2 "Middle" 3 "Running_Up" 4 "Running_Down" 5 "Reverse" 6 "Short_drop" 7 "SNA";
VAL_ 1313 STS_DRS_RearLeftWindowSts 0 "Open" 1 "Close" 2 "Middle" 3 "Running_Up" 4 "Running_Down" 5 "Reverse" 6 "Short_drop" 7 "SNA";
VAL_ 1313 Interior_Lock 0 "Not_Active" 1 "Active";
VAL_ 1313 VPSDoorSts 0 "Locked_External" 1 "Locked_Internal" 2 "Unlocked_External" 3 "Unlocked_Internal";
VAL_ 1313 LockUnlockDoors_Button 0 "Not_Pressed" 1 "Pressed";
VAL_ 1313 TrunkExternalButton 0 "Not_Active" 1 "Active";
VAL_ 1318 HazardActRqt 0 "Hazard_Off" 1 "Hazard_On";
VAL_ 1318 StopLightActRqt 0 "Stop_Light_switched_OFF" 1 "Stop_Light_switched_ON";
VAL_ 1318 BrakePedalSts 0 "Not_Pressed" 1 "Pressed";
VAL_ 1318 BrakePedalValidData 0 "Valid_QM" 1 "Not_valid" 2 "Valid_ASIL" 3 "Not_used";
VAL_ 1318 BrakePressureActualValidData 0 "Valid_QM" 1 "Not_valid" 2 "Valid_ASIL" 3 "Not_used";
VAL_ 1318 DriverBrkPressureRqtValidData 0 "Valid_QM" 1 "Not_valid" 2 "Valid_ASIL" 3 "Not_used";
VAL_ 1318 BrakePressureTargetValidData 0 "Valid_QM" 1 "Not_valid" 2 "Valid_ASIL" 3 "Not_used";
VAL_ 1318 BrakeRodStrokeValidData 0 "Valid_QM" 1 "Not_valid" 2 "Valid_ASIL" 3 "Not_used";
VAL_ 1351 HALF_CHIME_TYPESts 0 "None" 1 "Audio_01" 2 "Audio_02" 3 "Audio_03" 4 "Audio_04" 5 "Audio_05" 6 "Half_Chime" 7 "not_used" 8 "not_used" 9 "not_used" 10 "not_used" 11 "not_used" 12 "not_used" 13 "not_used" 14 "not_used" 15 "SNA";
VAL_ 1351 TSR_Fault 0 "OFF" 1 "ON";
VAL_ 1351 TSR_ON 0 "OFF" 1 "ON";
VAL_ 1351 LDWSystemSts 0 "OFF" 1 "ON" 2 "Init" 3 "Not_used";
VAL_ 1351 StatusLKA 0 "OFF" 1 "LKA_ON" 2 "LDW_ON" 3 "Init";
VAL_ 1351 LDWSensitivitySts 0 "Early" 1 "Med" 2 "Late" 3 "Init";
VAL_ 1351 HALF_RF_CHIME_RQSts 0 "False" 1 "True";
VAL_ 1351 HALF_LF_CHIME_RQSts 0 "False" 1 "True";
VAL_ 1351 TSA_ON 0 "Init" 1 "OFF" 2 "Visual" 3 "Visual_Acoustic";
VAL_ 1351 HandsOnSts 0 "OFF" 1 "Yellow" 2 "Red" 3 "Green" 4 "NO_HANDS_ON_STR_WHEEL_YELLOW" 5 "NO_HANDS_ON_STR_WHEEL_RED" 6 "NoDisplay" 7 "Not_Valid";
VAL_ 1351 StatusDDA 0 "Init" 1 "Enable" 2 "Not_Enable" 3 "not_used";
VAL_ 1351 ADAS_Unavailable_Camera 0 "No_Code" 1 "Camera_Blinded_ADAS_unavailable" 2 "Camera_Fail_ADAS_unavailable" 3 "SNA";
VAL_ 1351 TSAMainSign2Fbk 0 "Init" 1 "OFF" 2 "ON" 3 "Not_used";
VAL_ 1351 TSASignChangeFbk 0 "Init" 1 "OFF" 2 "ON" 3 "Not_used";
VAL_ 1351 DDAW_Level 0 "None" 1 "Level_1" 2 "Level_2" 3 "Level_3" 4 "Level_4" 5 "Level_5" 6 "Level_6" 7 "Level_7" 8 "Level_8" 9 "Level_9" 10 "Level_10" 11 "Not_used" 12 "Not_used" 13 "Not_used" 14 "Not_used" 15 "Not_used";
VAL_ 1351 DrowsinessSts 0 "LAMP_ON" 1 "LAMP_OFF" 2 "Failure" 3 "Not_Available";
VAL_ 1351 LDWWarningType_fbk 0 "Acoustic" 1 "Vibration" 2 "Acoustic_Vibration" 3 "Init";
VAL_ 1351 DisplaySts 0 "LaneSense_OFF" 1 "LaneSense_ON_HF_NotA" 2 "SingleLine_Left" 3 "SingleLine_Right" 4 "ON_HF_NotA_NHTSA_on_Left" 5 "ON_HF_NotA_NHTSA_on_Right" 6 "ON_HF_Armed" 7 "ON_HF_Left_SingleLine_Left" 8 "ON_HF_Left_Side" 9 "ON_HF_Right_SingleLine_Right" 10 "ON_HF_Right_Side" 11 "ON_HF_Left_NHTSA_Left" 12 "ON_HF_Right_NHTSA_Right" 13 "ON" 14 "ON_HF_LKA_on_Left" 15 "ON_HF_LKA_on_Right" 16 "Not_used" 17 "LKA_UNAVAILABLE" 18 "Not_used" 19 "Not_used" 20 "Not_used" 21 "Not_used" 22 "Not_used" 23 "Not_used" 24 "Not_used" 25 "Not_used" 26 "Not_used" 27 "Not_used" 28 "Not_used" 29 "Not_used" 30 "Not_used" 31 "Not_used" 32 "Not_used" 33 "Not_used" 34 "Not_used" 35 "Not_used" 36 "Not_used" 37 "Not_used" 38 "Not_used" 39 "Not_used" 40 "Not_used" 41 "Not_used" 42 "Not_used" 43 "Not_used" 44 "Not_used" 45 "Not_used" 46 "Not_used" 47 "Not_used" 48 "Not_used" 49 "Not_used" 50 "Not_used" 51 "Not_used" 52 "Not_used" 53 "Not_used" 54 "Not_used" 55 "Not_used" 56 "Not_used" 57 "Not_used" 58 "Not_used" 59 "Not_used" 60 "Not_used" 97 "ON_HF_NotA_NoHands" 98 "SingleLine_Left_marker_NoHands" 99 "SingleLine_Right_marker_NoHands" 100 "ON_HF_NotA_NHTSA_on_Left_NoHand" 101 "ON_HF_NotA_NHTSA_on_Right_NoHand" 102 "ON_HF_Armed_NoHands" 103 "ON_HF_Left_SingleLineLeft_NoHand" 104 "ON_HF_Left_NoHands" 105 "ON_HF_Right_SingleLine_R_NoHand" 106 "ON_HF_Right_NoHands" 107 "ON_HF_Left_NHTSA_on_Left_NoHand" 108 "ON_HF_Right_NHTSA_on_R_NoHand" 109 "Not_used" 110 "Not_used" 111 "Not_used" 112 "Not_used" 113 "Not_used" 114 "Not_used" 115 "Not_used" 116 "Not_used" 117 "Not_used" 118 "Not_used" 119 "Not_used" 120 "Not_used" 121 "Not_used" 122 "Not_used" 123 "Not_used" 124 "Not_used" 125 "Not_used" 126 "Not_used" 127 "Not_used" 128 "Not_used" 129 "Not_used" 130 "Not_used" 131 "Not_used" 132 "Not_used" 133 "Not_used" 134 "Not_used" 135 "Not_used" 136 "Not_used" 137 "Not_used" 138 "Not_used" 139 "Not_used" 140 "Not_used" 141 "Not_used" 142 "Not_used" 143 "Not_used" 144 "Not_used" 145 "Not_used" 146 "Not_used" 147 "Not_used" 148 "Not_used" 149 "Not_used" 150 "Not_used" 151 "Not_used" 152 "Not_used" 153 "Not_used" 154 "Not_used" 155 "Not_used" 156 "Not_used" 157 "Not_used" 158 "Not_used" 159 "Not_used" 160 "Sensor_Blinded" 161 "LaneSense_Temp_Unavailable" 162 "Blinded_LaneSense_AHBC_ON" 163 "Not_used" 164 "Not_used" 165 "Not_used" 166 "Not_used" 167 "Not_used" 168 "Not_used" 169 "Not_used" 170 "Not_used" 171 "Not_used" 172 "Not_used" 173 "Not_used" 174 "Not_used" 175 "Not_used" 176 "Not_used" 177 "Not_used" 178 "Not_used" 179 "Not_used" 180 "Not_used" 181 "Not_used" 182 "Not_used" 183 "Not_used" 184 "Not_used" 185 "Not_used" 186 "Not_used" 187 "Not_used" 188 "Not_used" 189 "Not_used" 190 "Not_used" 191 "Not_used" 192 "Not_used" 193 "Not_used" 194 "Not_used" 195 "Not_used" 196 "Not_used" 197 "Not_used" 198 "Not_used" 199 "Not_used" 200 "Not_used" 201 "Not_used" 202 "Not_used" 203 "Not_used" 204 "Not_used" 205 "Not_used" 206 "Not_used" 207 "Not_used" 208 "Not_used" 209 "Not_used" 210 "Not_used" 211 "Not_used" 212 "Not_used" 213 "Not_used" 214 "Not_used" 215 "Not_used" 216 "Not_used" 217 "Not_used" 218 "Not_used" 219 "Not_used" 220 "Not_used" 221 "Not_used" 222 "Not_used" 223 "Not_used" 224 "Not_used" 225 "Not_used" 226 "Not_used" 227 "Not_used" 228 "Not_used" 229 "Not_used" 230 "Not_used" 231 "Not_used" 232 "Not_used" 233 "Not_used" 234 "Not_used" 235 "Not_used" 236 "Not_used" 237 "Not_used" 238 "Not_used" 239 "Not_used" 240 "LaneSense_Fault" 241 "Not_used" 242 "Not_used" 243 "Not_used" 244 "Not_used" 245 "Not_used" 246 "Not_used" 247 "Not_used" 248 "Not_used" 249 "Not_used" 250 "Not_used" 251 "Not_used" 252 "Not_used" 253 "Not_used" 254 "Not_used" 255 "SNA";
VAL_ 1351 SensorBlinded 0 "OFF" 1 "ON";
VAL_ 1351 AHBFault 0 "OFF" 1 "ON";
VAL_ 1351 AHB_ON 0 "OFF" 1 "ON";
VAL_ 1351 TSR_Sts 0 "init" 1 "Operative";
VAL_ 1351 HALF_heaterSts 0 "Inactive" 1 "Active";
VAL_ 1351 DDAW_Index 511 "SNA";
VAL_ 1376 TrunkSts 0 "Closed" 1 "Open";
VAL_ 1376 AutoEPBButtonSts 0 "Not_Active" 1 "Active";
VAL_ 1376 PowerModeSts 0 "Standard_Power" 1 "Logistic_Mode_ON" 2 "Logistic_Mode_PR" 3 "Not_used";
VAL_ 1376 TrunkReleaseReqCntrl 0 "Not_active" 1 "Active";
VAL_ 1376 RechargeFlapButtonSts 0 "Not_Pressed" 1 "Pressed";
VAL_ 1376 KeySts 0 "Data_not_valid" 1 "STOP" 2 "PARK" 3 "Not_used" 4 "ON" 5 "Not_used" 6 "Not_used" 7 "Not_used" 8 "Not_used" 9 "Not_used" 10 "Not_used" 11 "Not_used" 12 "CRANK_ON" 13 "Not_used" 14 "Not_used" 15 "Not_used";
VAL_ 1376 ExternalTemperature 0 "FaultValue";
VAL_ 1376 FuelLevelFailSts 0 "Fail_Not_Present" 1 "Fail_Present";
VAL_ 1376 EngineBonnetSts 0 "Closed" 1 "Open";
VAL_ 1376 ExternalTemperatureFailSts 0 "Fail_Not_Present" 1 "Fail_Present";
VAL_ 1376 FOBSearchRequest 0 "NO_ACTION" 1 "REQUEST_SEARCH" 2 "RESULT_RECEIVED" 3 "RESERVED";
VAL_ 1376 TheftAlarmStatus 0 "VTA_DISARM" 1 "VTA_PREARM" 2 "VTA_ARM" 3 "VTA_LGT" 4 "VTA_LGT_HORN" 5 "VTA_TAMP" 6 "VTA_ITM_Alarm" 7 "SNA";
VAL_ 1376 ChargingReleaseReqCntrl 0 "Not_Active" 1 "Active";
VAL_ 1376 NTPCalibrationReqSts 0 "no_Request" 1 "Request";
VAL_ 1377 ShiftIndicatorLightSts 0 "Light_Indication_off" 1 "Flashing_Light_Indication" 2 "Fix_Light_Indication" 3 "Not_used";
VAL_ 1377 EngineSpeedValidData 0 "Valid" 1 "Not_valid";
VAL_ 1382 GenericFailSts 0 "No_functional_fail_is_present" 1 "At_least_one_funct_fail_pres";
VAL_ 1382 CurrentFailSts 0 "No_functional_fail_is_present" 1 "DTCStatus_present";
VAL_ 1382 EOL 0 "No_EOL_prog_At_FIAT" 1 "EOL_prog_At_FIAT";
VAL_ 1382 DES 0 "Error_Active_State" 1 "Error_Passive_Warning_State" 2 "Bus_Off_State" 3 "Not_used";
VAL_ 1382 R_OdometerPulseCounterFailSts 0 "Fail_Not_Present" 1 "Fail_Present";
VAL_ 1382 L_OdometerPulseCounterFailSts 0 "Fail_Not_Present" 1 "Fail_Present";
VAL_ 1387 GenericFailSts 0 "No_functional_fail_is_present" 1 "At_least_one_funct_fail_pres";
VAL_ 1387 CurrentFailSts 0 "No_functional_fail_is_present" 1 "DTCStatus_present";
VAL_ 1387 EOL 0 "No_EOL_prog_At_FIAT" 1 "EOL_prog_At_FIAT";
VAL_ 1387 D_ES 0 "Error_Active_State" 1 "Error_Passive_Warning_State" 2 "Bus_Off_State" 3 "Not_used";
VAL_ 1387 ShiftModeSts 0 "Manual" 1 "Automatic";
VAL_ 1387 Automatic_RoboticXmsnFailSts 0 "Fail_Not_Present" 1 "Fail_Present";
VAL_ 1387 ActualGearForDisplay 0 "Not_coded" 1 "_1st_gear" 2 "_2nd_gear" 3 "_3rd_gear" 4 "_4th_gear" 5 "_5th_gear" 6 "_6th_gear" 7 "_7th_gear" 8 "'8th gear'" 9 "Not_used" 10 "Not_used" 11 "'P'" 12 "'D'" 13 "'L'" 14 "'R'" 15 "'N'";
VAL_ 1387 NCDFailSts 0 "Lamps_Off_Fail_not_present" 1 "Amber_Lamp_On_Fail_present" 2 "Amber_Lamp_On_Fail_present" 3 "Red_Lamp_On_Fail_present";
VAL_ 1387 GPFInfo_NCR_MuxId 0 "GPFInfo_LSB" 1 "GPFInfo_MSB";
VAL_ 1387 LaunchCircularLedSts 0 "OFF" 1 "ON" 2 "Blinking" 3 "Not_used";
VAL_ 1387 AutoEPBInhibitionReq 0 "Not_Active" 1 "Active";
VAL_ 1387 Command_Lamp_Fail_Gear 0 "Lamp_OK" 1 "Lamp_in_Fail";
VAL_ 1387 BuzzerReqSts 0 "OFF" 1 "Reverse_gear_sound_ON" 2 "Others_case_sound_ON" 3 "ParkLock_not_Inserted";
VAL_ 1387 GPFInfo_NCR_ValidData 0 "Valid" 1 "Not_valid";
VAL_ 1387 GearIndicationSts 0 "Normal" 1 "Blinking";
VAL_ 1387 LaunchLedSts 0 "Launch OFF" 1 "Launch ON" 2 "Launch BLINKING OFF" 3 "Launch BLINKING ON";
VAL_ 1387 PerformanceLaunchIndication 0 "No_Warning" 1 "Pressing_Brake_And_Gas_Pedal" 2 "Press_And_Hold_Gas_Pedal" 3 "Release_Brake_Pedal";
VAL_ 1387 AutomaticRoboticXmsnDegradedMode 0 "Not_active" 1 "Active";
VAL_ 1387 PerformanceLaunchMode 0 "Not_active" 1 "Active";
VAL_ 1387 RoboticTransmissionWarning 0 "No_warning" 1 "Press_brake_pedal_for_Start_warning" 2 "Tip_not_available_warning" 3 "Lower_gear_shifts_warning" 4 "Manual_mode_not_avail_warn" 5 "Insert_N_warning" 6 "Automatic_mode_not_avail_warning" 7 "Delayed_start_up_warning" 8 "Clutch_over_temperature" 9 "Manoeuvre_not_allowed_warning" 10 "Press_brake_pedal_and_repeat_man" 11 "F1_pump_overheating_lower_gear" 12 "Parking_lock_not_inserted" 13 "Carwash_mode_activation" 14 "Disengage_parklock_request" 15 "Creeping_Deactivation" 16 "SuperCapWarning" 17 "Insert_P_Warning" 18 "GearLever_Fail" 19 "LaunchLever_Fail" 20 "HVB_Preconditioning_Interrupted" 21 "LaunchProcedureEngaged" 22 "Vehicle_Not_Standstill" 23 "Wrong_EManettino_Position_Launch" 24 "Communication_Error" 25 "Parking_Lock_Stuck_Engaged" 26 "Torque_Disabled_Disengage_EPB" 27 "Road_Slope_Too_High" 28 "Warm_Up_Needed_for_Launch" 29 "Low_SOC_for_Launch" 30 "Lifter_ON_Warning" 31 "Seatbelts_Unfastened" 32 "Wrong_EManettino_Position_Manual" 33 "Press_brake_pedal_for_Launch" 34 "Not_used" 35 "Not_used" 36 "Not_used" 37 "Not_used" 38 "Not_used" 39 "Not_used" 40 "Not_used" 41 "Not_used" 42 "Not_used" 43 "Not_used" 44 "Not_used" 45 "Not_used" 46 "Not_used" 47 "Not_used" 48 "Not_used" 49 "Not_used" 50 "Not_used" 51 "Not_used" 52 "Not_used" 53 "Not_used" 54 "Not_used" 55 "Not_used" 56 "Not_used" 57 "Not_used" 58 "Not_used" 59 "Not_used" 60 "Not_used" 61 "Not_used" 62 "Not_used" 63 "Not_used";
VAL_ 1387 PLockSts 0 "Not_Engaged" 1 "Engaged" 2 "Fail" 3 "Not_used";
VAL_ 1387 NCR_EPB_Req 0 "Not_Req" 1 "Req";
VAL_ 1387 SailingAct 0 "Not_active" 1 "Active";
VAL_ 1391 GenericFailSts 0 "No_functional_fail_is_present" 1 "At_least_one_funct_fail_pres";
VAL_ 1391 CurrentFailSts 0 "No_functional_fail_is_present" 1 "DTCStatus_present";
VAL_ 1391 EOL 0 "No_EOL_prog_At_FIAT" 1 "EOL_prog_At_FIAT";
VAL_ 1391 D_ES 0 "Error_Active_State" 1 "Error_Passive_Warning_State" 2 "Bus_Off_State" 3 "Not_used";
VAL_ 1398 GenericFailSts 0 "No_functional_fail_is_present" 1 "At_least_one_funct_fail_pres";
VAL_ 1398 CurrentFailSts 0 "No_functional_fail_is_present" 1 "DTCStatus_present";
VAL_ 1398 EOL 0 "No_EOL_prog_At_FIAT" 1 "EOL_prog_At_FIAT";
VAL_ 1398 D_ES 0 "Error_Active_State" 1 "Error_Passive_Warning_State" 2 "Bus_Off_State" 3 "Not_used";
VAL_ 1398 RWSInternalSts 0 "Init_Check" 1 "Ready_for_Drive" 2 "Drive" 3 "Diag" 4 "Emergency_2_Zero_Position" 5 "Error_Blocked" 6 "Shutdown" 7 "Not_used" 8 "Not_used" 9 "Not_used" 10 "Not_used" 11 "Not_used" 12 "Not_used" 13 "Not_used" 14 "Not_used" 15 "Not_used" 16 "Not_used" 17 "Not_used" 18 "Not_used" 19 "Not_used" 20 "Not_used" 21 "Not_used" 22 "Not_used" 23 "Not_used" 24 "Not_used" 25 "Not_used" 26 "Not_used" 27 "Not_used" 28 "Not_used" 29 "Not_used" 30 "Not_used" 31 "Not_used";
VAL_ 1398 WarningLamp 0 "None" 1 "Yellow_Lamp" 2 "Red_Lamp" 3 "Invalid";
VAL_ 1398 SnowChainModeLampSts 0 "Lamp_OFF" 1 "Lamp_ON";
VAL_ 1408 FLS1RawValueValidData 0 "Valid" 1 "Not_valid";
VAL_ 1408 FLS2RawValueValidData 0 "Valid" 1 "Not_valid";
VAL_ 1408 FLS3RawValueValidData 0 "Valid" 1 "Not_valid";
VAL_ 1441 ReducePowerAssist 0 "Not_Active" 1 "Active";
VAL_ 1441 BatteryDisconnectionWarning 0 "Not_Active" 1 "Active";
VAL_ 1441 VCU_EnergyProfileRqt 0 "Normal" 1 "Eco" 2 "Low_Driver" 3 "Low_Auto" 4 "Degraded" 5 "Not_Used" 6 "Not_Used" 7 "Not_Used";
VAL_ 1441 VehicleNotInUse 0 "Vehicle_in_Use" 1 "Start_Countdown" 2 "Start_Signalling" 3 "System_Failure";
VAL_ 1441 EManettinoSts 1 "Edrive_ECO" 2 "Standard" 3 "Performance" 4 "Qualifying";
VAL_ 1441 EManettinoFailSts 0 "Fail_Not_Present" 1 "Fail_Present";
VAL_ 1441 EManettinoTransitionInfo 0 "No_Transition" 1 "Status_Not_Allowed" 2 "Setting_Refused" 3 "not_used" 4 "not_used" 5 "not_used" 6 "Status_Modified" 7 "Setting_Accepted";
VAL_ 1441 MVLoadEnable_NPR 0 "Disable" 1 "Enable";
VAL_ 1441 CruiseControlSts 0 "Not_inserted" 1 "Inserted";
VAL_ 1441 CruiseControlLampSts 0 "cruise_off" 1 "cruise_on_not_engaged" 2 "cruise_on_engaged" 3 "cruise_error";
VAL_ 1441 RechargeSts 0 "Charging" 1 "Not_charging";
VAL_ 1441 BatteryVoltageLevelFailSts 0 "Fail_not_present" 1 "Fail_present";
VAL_ 1441 EngineSts 0 "Engine_OFF" 1 "Engine_ON" 2 "Engine_cranking" 3 "Engine_Shut_down";
VAL_ 1441 StopStartSts 0 "Off" 1 "On" 2 "Engine_Restart" 3 "Stop_Request";
VAL_ 1441 PowertrainSts 0 "OFF" 1 "ON" 2 "Starting" 3 "Shut_down" 4 "Not_used" 5 "Not_used" 6 "Not_used" 7 "Not_used";
VAL_ 1441 EDriveSts 0 "Off" 1 "Prepare_E_Drive" 2 "E_Drive" 3 "Stop_E_Drive";
VAL_ 1443 a4WDDisplayInfo 0 "No_Request_to_HMI" 1 "Fail_Lamp_ON";
VAL_ 1443 ISA_ChangeSignWarning 0 "Not_Active" 1 "Active";
VAL_ 1443 ISA_AcusticWarning 0 "Not_Active" 1 "Active";
VAL_ 1443 TCSDisplayInfo 0 "No_Request_to_HMI" 1 "Degraded_mode" 2 "Under_Intervention" 3 "Fail_Lamp_ON";
VAL_ 1443 LongParkingDays 16383 "Mote_than_9999";
VAL_ 1443 ISA_VisualWarning 0 "Not_Active" 1 "Active";
VAL_ 1443 ISA_Fault 0 "Not_Active" 1 "Active";
VAL_ 1445 MsgFOBLeftVeh 0 "MSG_DEFAULT" 1 "MSG_ACTIVE" 2 "Not_used" 3 "SNA";
VAL_ 1445 PowerModeSts_NPE 0 "Standard_Power" 1 "Logistic_Mode_ON" 2 "Logistic_Mode_PR" 3 "Not_used";
VAL_ 1445 KeyProgramSts 0 "RKE_NORM_STAT" 1 "EN_KEY_PROG" 2 "PROG_ACT" 3 "EX_KEY_PROG" 4 "KEY_PROG" 5 "DMG_KEY" 6 "INV_KEY" 7 "EXCD_KEY" 8 "RKE_BATT_LO" 9 "SRV_SKREEM" 10 "BTN_DLY_ACT" 11 "BTN_DLY_INACT" 12 "KEY_NOT_PROG" 13 "Not_used" 14 "Not_used" 15 "SNA";
VAL_ 1445 MsgServPEKG 0 "MSG_DEFAULT" 1 "MSG_ACTIVE" 2 "Not_used" 3 "SNA";
VAL_ 1445 MsgPutInPark 0 "MSG_DEFAULT" 1 "MSG_ACTIVE" 2 "Not_used" 3 "SNA";
VAL_ 1445 MsgNotInPark 0 "MSG_DEFAULT" 1 "MSG_ACTIVE" 2 "Not_used" 3 "SNA";
VAL_ 1445 MsgFOBNotFnd 0 "MSG_DEFAULT" 1 "MSG_ACTIVE" 2 "Not_used" 3 "SNA";
VAL_ 1445 MsgRemovePlug 0 "MSG_DEFAULT" 1 "MSG_ACTIVE";
VAL_ 1445 LastKeyFobNumSeen 0 "FOB_DEFAULT" 1 "FOB_1" 2 "FOB_2" 3 "FOB_3" 4 "FOB_4" 5 "FOB_5" 6 "FOB_6" 7 "FOB_7" 8 "FOB_8" 9 "FOB_9" 10 "FOB_10" 11 "not_used" 12 "not_used" 13 "not_used" 14 "not_used" 15 "not_used";
VAL_ 1445 MsgAutoIgnOFF 0 "No_Message" 1 "Engine_ON_Required" 2 "Key_OFF_Ongoing" 3 "Not_used";
VAL_ 1445 Key_ON_Visualization 0 "Not_Active" 1 "Active" 2 "Not_Used" 3 "Not_Used";
VAL_ 1459 OCSM_Passenger_Classification 0 "Not_Used" 1 "Child" 2 "Adult" 3 "Indeterminate";
VAL_ 1459 OCSSts 0 "OK" 1 "Fail";
VAL_ 1459 DrvSbltUnFltr 0 "Seat_belt_fastened_buckled" 1 "Seatbelt_not_fastened_unbuckled" 2 "Seatbelt_shorted_low" 3 "Seatbelt_shorted_high" 4 "Not_used" 5 "Not_used" 6 "Not_used" 7 "SNA";
VAL_ 1459 NEC_Replacement_Warning 0 "Not_Active" 1 "Active";
VAL_ 1459 OCSM_Passenger_Detected 0 "False" 1 "True";
VAL_ 1481 HVB_Temperature_Indicator 117 "Virtual_0";
VAL_ 1481 SOC_Indicator_Bars 0 "SOC_BarGraphIndicatorEmpty" 1 "_1st_SOC_Notch_ON" 2 "_2nd_SOC_Notch_ON" 3 "_3rd_SOC_Notch_ON" 4 "_4th_SOC_Notch_ON" 5 "_5th_SOC_Notch_ON" 6 "_6th_SOC_Notch_ON" 7 "_7th_SOC_Notch_ON" 8 "_8th_SOC_Notch_ON" 9 "Not_used" 10 "Not_used" 11 "Not_used" 12 "Not_used" 13 "Not_used" 14 "Not_used" 15 "Not_used";
VAL_ 1481 HVB_SOC_Colour_HMI 0 "No_colour" 1 "Green" 2 "Yellow" 3 "Red";
VAL_ 1485 LongParkingInfoForDisplay 0 "Not_Active" 1 "Deactivated" 2 "Activated" 3 "Not_Activated" 4 "Automatic_Activated" 5 "Automatic_Activation_Rqt" 6 "not_used" 7 "not_used";
VAL_ 1485 HVBBuzzerReq 0 "Not_Active" 1 "Active";
VAL_ 1485 HVBChargeWarningForDisplay 0 "No_Failure" 1 "OBC Fail_Communication" 2 "PlugLock_Fail" 3 "OBC_Fail_Power_Conversion" 4 "BOOSTER_Fail" 5 "HVB_Recharge_Fail_ChargingBus" 6 "EVSE_Fail" 7 "Pwr_Limited_By_Grid" 8 "not_used" 9 "not_used" 10 "not_used" 11 "not_used" 12 "not_used" 13 "not_used" 14 "not_used" 15 "not_used" 16 "not_used" 17 "not_used" 18 "not_used" 19 "not_used" 20 "not_used" 21 "not_used" 22 "not_used" 23 "not_used" 24 "not_used" 25 "not_used" 26 "not_used" 27 "not_used" 28 "not_used" 29 "not_used" 30 "not_used" 31 "not_used";
VAL_ 1485 LongParkingSts 0 "Not_Active" 1 "Active";
VAL_ 1485 HVBSOC_Status_HMI 0 "Not_Present" 1 "Degraded" 2 "Critical" 3 "not_used";
VAL_ 1485 HVB_TemperatureFailSts 0 "Not_Active" 1 "Degraded" 2 "Critical" 3 "Not_Used";
VAL_ 1485 BatPrecondSts 0 "Not_Active" 1 "Active" 2 "Active_TargetReached";
VAL_ 1485 HVSysWarningForDisplay 0 "No_Failure" 1 "MSD_Open" 2 "HVIL_Open" 3 "HV_Insulation_Critical" 4 "HV_Energizing_Error_Critical" 5 "HV_Insulation_Warning" 6 "HV_Energizing_Error_Warning" 7 "not_used" 8 "not_used" 9 "not_used" 10 "not_used" 11 "not_used" 12 "not_used" 13 "not_used" 14 "not_used" 15 "not_used";
VAL_ 1485 BatEstTimeToTarget 127 "SNA";
VAL_ 1485 MILrequest 0 "MILLampOff" 1 "MILLampOn";
VAL_ 1485 BatPrecondProgress 255 "SNA";
VAL_ 1485 HVBWarningForDisplay 0 "No_Failure" 1 "HVB_Thermal_runaway" 2 "HVB_Temperature_Critical" 3 "HVB_Electrical_Fault_Critical" 4 "HVB_HW_Fault_Critical" 5 "Communication_Fault_Critical" 6 "HVB_Temperature_Warning" 7 "HVB_Electrical_Fault_Warning" 8 "HVB_HW_Fault_Warning" 9 "Communication_Fault_Warning" 10 "Crash_Warning" 11 "HVB_SOH_warning" 12 "HVB_SOC_low" 13 "HVB_SOC_mid" 14 "HVB_SOC_high" 15 "HVB_Charge_needed_less_than_one_day" 16 "HVB_Charge_needed_less_than_X_days" 17 "not_used" 18 "not_used" 19 "not_used" 20 "not_used" 21 "not_used" 22 "not_used" 23 "not_used" 24 "not_used" 25 "not_used" 26 "not_used" 27 "not_used" 28 "not_used" 29 "not_used" 30 "not_used" 31 "not_used";
VAL_ 1485 HVBStatus 0 "Not_Present" 1 "Degraded" 2 "Critical" 3 "Not_Used";
VAL_ 1485 HVBSOC_Status_China_HMI 0 "Normal" 1 "Degraded";

SIG_GROUP_  670 DASM_RQT_2_SigGroup 1 : ACCFailReversibleSts ACCFailSts ACCSystemSts ACC_RadarBlinded CRC_DASM_RQT_2 DASMFailSts DASMTemporaryFailSts MsgCnt_DASM_RQT_2 RadarBlinded;
SIG_GROUP_  1485 HVB_HMI_STS_SigGroup 1 : BatEstTimeToTarget BatPrecondProgress BatPrecondSts CRC_HVB_HMI_STS HVBBuzzerReq HVBChargeWarningForDisplay HVBSOC_Status_China_HMI HVBSOC_Status_HMI HVBStatus HVBWarningForDisplay HVB_SOC_BEV_HMI HVB_TemperatureFailSts HVSysWarningForDisplay LongParkingInfoForDisplay LongParkingSts MILrequest MsgCnt_HVB_HMI_STS;
SIG_GROUP_  778 LIFTER_INFO_SigGroup 1 : CRC_LIFTER_INFO LifterAutoStopEnableSts LifterAutoStopFailSts LifterAutoStopStaySts LifterAutonomy LifterBuzzerReq LifterFailSts LifterInfoForDisplay LifterSts LifterType MsgCnt_LIFTER_INFO;
SIG_GROUP_  630 NFR_INFO_SigGroup 1 : ABSSts AVHSts AutoEPBEnable CDPSts CRBSts CRC_NFR_INFO EBDSts EPBMalfunction EPBSts EPB_ButtonSts ESCOFF_Mode HHCSts LDISts MSRSts MessageCounter_NFR_INFO MiniSpareDetection Slope SlopeValidData TireToleranceCompensation VDCSts;
SIG_GROUP_  1267 PWT_STATUS_1_SigGroup 1 : CCSpeedWarning CRC_PWT_STATUS_1 HMICode_CC LVSysWarningForDisplay MVFailSts MVSysWarningForDisplay MsgCnt_PWT_STATUS_1 PWTBuzzerReq PWTFailSts PWTLimpHomeSts PWTSystemWarningForDisplay PWT_Limited_Perfo PlugInRechargeWarning PropulsionSystemFailure RechargeSts_HVB Recharge_PlugSts START_ButtonPress_Rqt VehicleStartNotAllowed;
SIG_GROUP_  625 PWT_STATUS_3_SigGroup 1 : CRC_PWT_STATUS_3 GasPedalPosition GasPedalPositionValidData MsgCnt_PWT_STATUS_3 PWT_StopLightActReq PowerUnitDriverPresence StopStartParkLockReq TotalVehicleWheelTrq TotalVehicleWheelTrqValidData VCUCrashSts VCUFisSts VCUVehicleSecureRqt VehWheelDriverReqTrq VehWheelDriverReqTrqValidData;
SIG_GROUP_  653 PWT_STATUS_4_SigGroup 1 : CRC_PWT_STATUS_4 MsgCnt_PWT_STATUS_4 OdomMismatchFailSts OverboostLevel_NQS OverboostStatus PowerOff_AutoMode_ActualLevel ReadyIndicationForDisplay;
SIG_GROUP_  1443 PWT_STATUS_5_SigGroup 1 : AbsolutePedalPosition CRC_PWT_STATUS_5 ISA_AcusticWarning ISA_ChangeSignWarning ISA_Fault ISA_VisualWarning LongParkingDays MsgCnt_PWT_STATUS_5 TCSDisplayInfo TimeSincePowerUnitStart a4WDDisplayInfo;
SIG_GROUP_  654 VCU_CHRG_RQT_SigGroup 1 : CRC_VCU_CHRG_RQT MsgCnt_VCU_CHRG_RQT RechargeLedRqt VCU_UserChargeEnable VCU_UserPlugUnlock_Mng VCU_VehicleChargeEnable;
